VERSION "HNNBNNNYNNNNNNNNNNNNNNNNNNNNNNNNNNNNNNNNNN/4/%%%/4/'%**4NNN///"

NS_ :

BS_:

BU_: BAP_Tester BMS_NV_12V Gateway_Max Klima

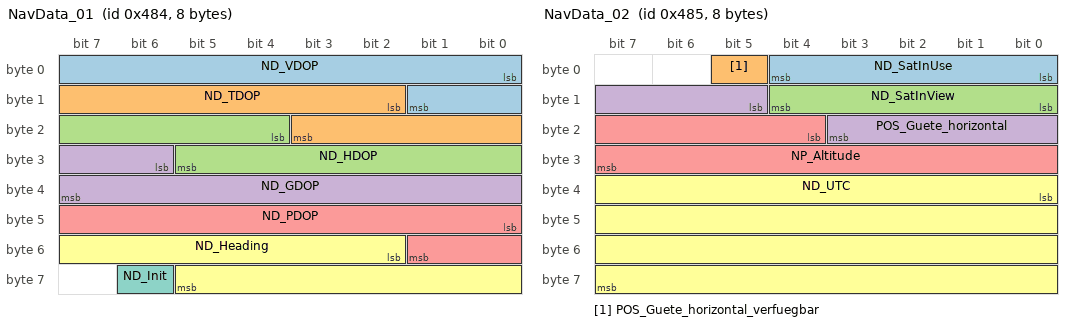
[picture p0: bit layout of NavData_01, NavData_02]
BO_ 1156 NavData_01: 8 Gateway_Max
 SG_ ND_VDOP : 0|10@1+ (0.025,0) [0.000|25.000] ""  Vector__XXX
 SG_ ND_TDOP : 10|10@1+ (0.025,0) [0.000|25.000] ""  Vector__XXX
 SG_ ND_HDOP : 20|10@1+ (0.025,0) [0.000|25.000] ""  Vector__XXX
 SG_ ND_GDOP : 30|10@1+ (0.025,0) [0.000|25.000] ""  Vector__XXX
 SG_ ND_PDOP : 40|10@1+ (0.025,0) [0.000|25.000] ""  Vector__XXX
 SG_ ND_Heading : 50|12@1+ (0.1,0) [0.0|359.9] "Unit_DegreOfArc"  Klima
 SG_ ND_Init : 62|1@1+ (1.0,0.0) [0.0|1] ""  Vector__XXX

BO_ 1157 NavData_02: 8 Gateway_Max
 SG_ ND_SatInUse : 0|5@1+ (1,0) [0|29] ""  Vector__XXX
 SG_ POS_Guete_horizontal_verfuegbar : 5|1@1+ (1.0,0.0) [0.0|1] ""  Vector__XXX
 SG_ ND_SatInView : 8|5@1+ (1,0) [0|29] ""  Vector__XXX
 SG_ POS_Guete_horizontal : 13|7@1+ (2,0) [0|246] "Unit_Meter"  Vector__XXX
 SG_ NP_Altitude : 20|12@1+ (2,-500) [-500|7686] "Unit_Meter"  Klima
 SG_ ND_UTC : 32|32@1+ (1,0) [0|4294967293] "Unit_Secon"  Klima

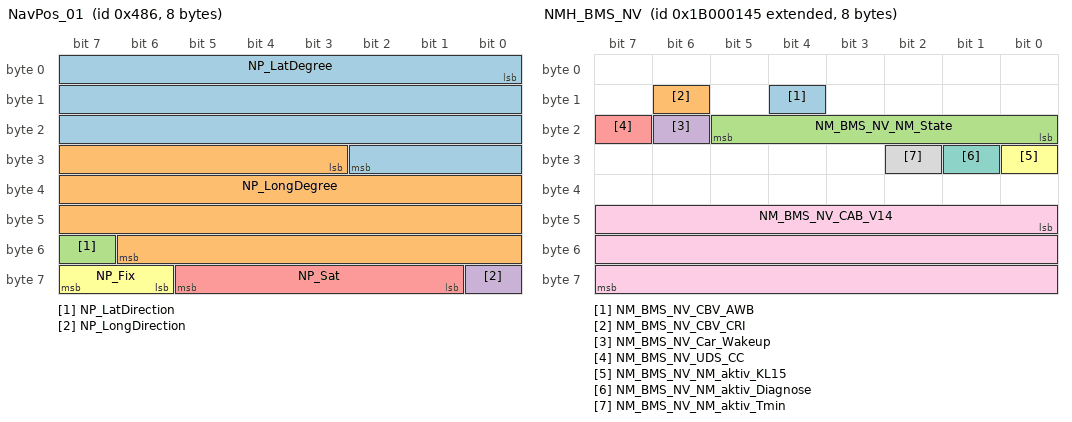
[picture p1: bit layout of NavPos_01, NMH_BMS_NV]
BO_ 1158 NavPos_01: 8 Gateway_Max
 SG_ NP_LatDegree : 0|27@1+ (0.000001,0) [0.000000|90.000000] "Unit_DegreOfArc"  Klima
 SG_ NP_LongDegree : 27|28@1+ (0.000001,0) [0.000000|180.000000] "Unit_DegreOfArc"  Klima
 SG_ NP_LatDirection : 55|1@1+ (1.0,0.0) [0.0|1] ""  Klima
 SG_ NP_LongDirection : 56|1@1+ (1.0,0.0) [0.0|1] ""  Klima
 SG_ NP_Sat : 57|5@1+ (1,0) [0|29] ""  Vector__XXX
 SG_ NP_Fix : 62|2@1+ (1.0,0.0) [0.0|3] ""  Vector__XXX

BO_ 2600468805 NMH_BMS_NV: 8 BMS_NV_12V
 SG_ NM_BMS_NV_CBV_AWB : 12|1@1+ (1.0,0.0) [0.0|1] ""  Gateway_Max
 SG_ NM_BMS_NV_CBV_CRI : 14|1@1+ (1.0,0.0) [0.0|1] ""  Gateway_Max
 SG_ NM_BMS_NV_NM_State : 16|6@1+ (1.0,0.0) [0.0|63] ""  Klima
 SG_ NM_BMS_NV_Car_Wakeup : 22|1@1+ (1.0,0.0) [0.0|1] ""  Gateway_Max
 SG_ NM_BMS_NV_UDS_CC : 23|1@1+ (1.0,0.0) [0.0|1] ""  Vector__XXX
 SG_ NM_BMS_NV_NM_aktiv_KL15 : 24|1@1+ (1.0,0.0) [0.0|1] ""  Vector__XXX
 SG_ NM_BMS_NV_NM_aktiv_Diagnose : 25|1@1+ (1.0,0.0) [0.0|1] ""  Vector__XXX
 SG_ NM_BMS_NV_NM_aktiv_Tmin : 26|1@1+ (1.0,0.0) [0.0|1] ""  Vector__XXX
 SG_ NM_BMS_NV_CAB_V14 : 40|24@1+ (1.0,0.0) [0.0|16777215] ""  Gateway_Max

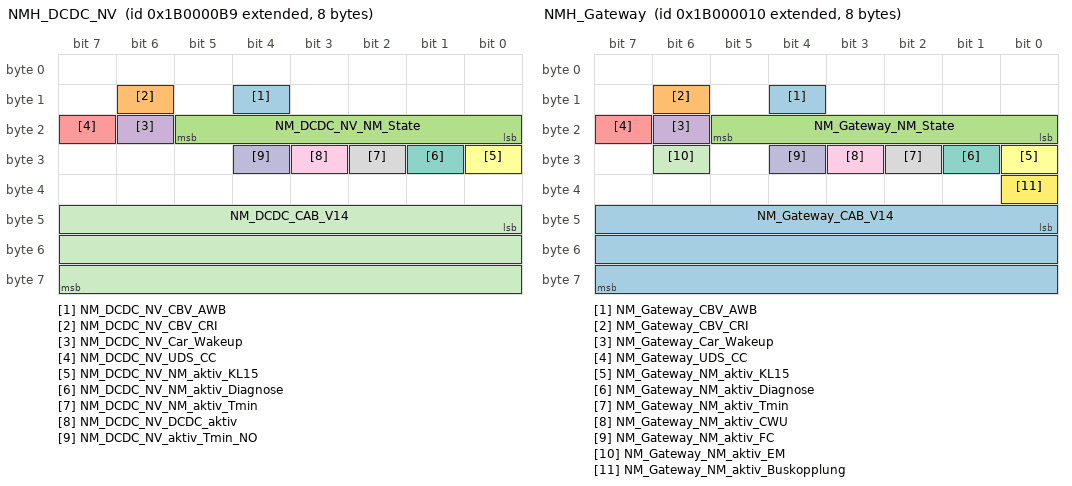
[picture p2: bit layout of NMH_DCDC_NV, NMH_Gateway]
BO_ 2600468665 NMH_DCDC_NV: 8 Vector__XXX
 SG_ NM_DCDC_NV_CBV_AWB : 12|1@1+ (1.0,0.0) [0.0|1] ""  Gateway_Max
 SG_ NM_DCDC_NV_CBV_CRI : 14|1@1+ (1.0,0.0) [0.0|1] ""  Gateway_Max
 SG_ NM_DCDC_NV_NM_State : 16|6@1+ (1.0,0.0) [0.0|63] ""  BMS_NV_12V,Klima
 SG_ NM_DCDC_NV_Car_Wakeup : 22|1@1+ (1.0,0.0) [0.0|1] ""  Gateway_Max
 SG_ NM_DCDC_NV_UDS_CC : 23|1@1+ (1.0,0.0) [0.0|1] ""  Vector__XXX
 SG_ NM_DCDC_NV_NM_aktiv_KL15 : 24|1@1+ (1.0,0.0) [0.0|1] ""  Vector__XXX
 SG_ NM_DCDC_NV_NM_aktiv_Diagnose : 25|1@1+ (1.0,0.0) [0.0|1] ""  Vector__XXX
 SG_ NM_DCDC_NV_NM_aktiv_Tmin : 26|1@1+ (1.0,0.0) [0.0|1] ""  Vector__XXX
 SG_ NM_DCDC_NV_DCDC_aktiv : 27|1@1+ (1.0,0.0) [0.0|1] ""  Vector__XXX
 SG_ NM_DCDC_NV_aktiv_Tmin_NO : 28|1@1+ (1.0,0.0) [0.0|1] ""  Vector__XXX
 SG_ NM_DCDC_CAB_V14 : 40|24@1+ (1.0,0.0) [0.0|16777215] ""  Gateway_Max

BO_ 2600468496 NMH_Gateway: 8 Gateway_Max
 SG_ NM_Gateway_CBV_AWB : 12|1@1+ (1.0,0.0) [0.0|1] ""  Vector__XXX
 SG_ NM_Gateway_CBV_CRI : 14|1@1+ (1.0,0.0) [0.0|1] ""  Vector__XXX
 SG_ NM_Gateway_NM_State : 16|6@1+ (1.0,0.0) [0.0|63] ""  BMS_NV_12V,Klima
 SG_ NM_Gateway_Car_Wakeup : 22|1@1+ (1.0,0.0) [0.0|1] ""  Vector__XXX
 SG_ NM_Gateway_UDS_CC : 23|1@1+ (1.0,0.0) [0.0|1] ""  Vector__XXX
 SG_ NM_Gateway_NM_aktiv_KL15 : 24|1@1+ (1.0,0.0) [0.0|1] ""  Vector__XXX
 SG_ NM_Gateway_NM_aktiv_Diagnose : 25|1@1+ (1.0,0.0) [0.0|1] ""  Vector__XXX
 SG_ NM_Gateway_NM_aktiv_Tmin : 26|1@1+ (1.0,0.0) [0.0|1] ""  Vector__XXX
 SG_ NM_Gateway_NM_aktiv_CWU : 27|1@1+ (1.0,0.0) [0.0|1] ""  Vector__XXX
 SG_ NM_Gateway_NM_aktiv_FC : 28|1@1+ (1.0,0.0) [0.0|1] ""  Vector__XXX
 SG_ NM_Gateway_NM_aktiv_EM : 30|1@1+ (1.0,0.0) [0.0|1] ""  Vector__XXX
 SG_ NM_Gateway_NM_aktiv_Buskopplung : 32|1@1+ (1.0,0.0) [0.0|1] ""  Vector__XXX
 SG_ NM_Gateway_CAB_V14 : 40|24@1+ (1.0,0.0) [0.0|16777215] ""  Vector__XXX

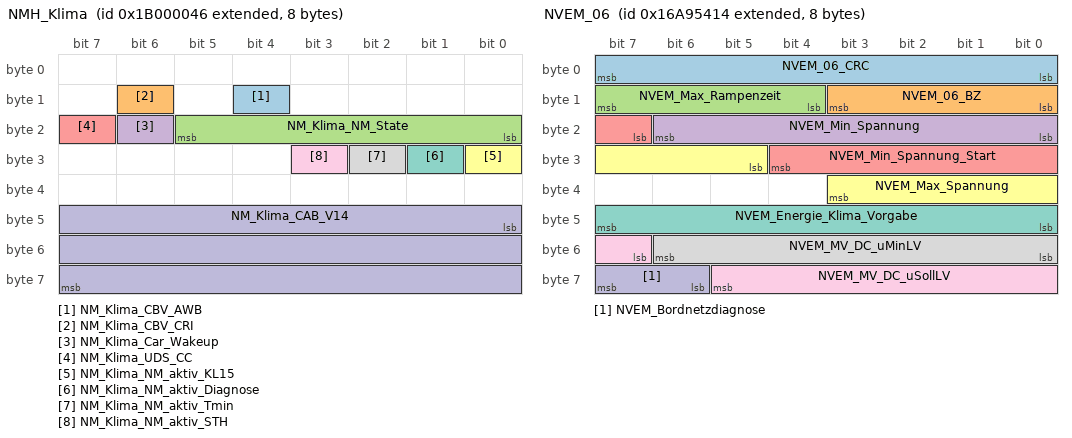
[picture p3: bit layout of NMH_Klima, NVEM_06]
BO_ 2600468550 NMH_Klima: 8 Klima
 SG_ NM_Klima_CBV_AWB : 12|1@1+ (1.0,0.0) [0.0|1] ""  Gateway_Max
 SG_ NM_Klima_CBV_CRI : 14|1@1+ (1.0,0.0) [0.0|1] ""  Gateway_Max
 SG_ NM_Klima_NM_State : 16|6@1+ (1.0,0.0) [0.0|63] ""  BMS_NV_12V
 SG_ NM_Klima_Car_Wakeup : 22|1@1+ (1.0,0.0) [0.0|1] ""  Gateway_Max
 SG_ NM_Klima_UDS_CC : 23|1@1+ (1.0,0.0) [0.0|1] ""  Vector__XXX
 SG_ NM_Klima_NM_aktiv_KL15 : 24|1@1+ (1.0,0.0) [0.0|1] ""  Vector__XXX
 SG_ NM_Klima_NM_aktiv_Diagnose : 25|1@1+ (1.0,0.0) [0.0|1] ""  Vector__XXX
 SG_ NM_Klima_NM_aktiv_Tmin : 26|1@1+ (1.0,0.0) [0.0|1] ""  Vector__XXX
 SG_ NM_Klima_NM_aktiv_STH : 27|1@1+ (1.0,0.0) [0.0|1] ""  Vector__XXX
 SG_ NM_Klima_CAB_V14 : 40|24@1+ (1.0,0.0) [0.0|16777215] ""  Gateway_Max

BO_ 2527679508 NVEM_06: 8 Gateway_Max
 SG_ NVEM_06_CRC : 0|8@1+ (1,0) [0|255] ""  Vector__XXX
 SG_ NVEM_06_BZ : 8|4@1+ (1,0) [0|15] ""  Vector__XXX
 SG_ NVEM_Max_Rampenzeit : 12|4@1+ (1.0,0.0) [0.0|15] ""  Vector__XXX
 SG_ NVEM_Min_Spannung : 16|7@1+ (0.05,10.6) [10.60|16.00] "Unit_Volt"  Vector__XXX
 SG_ NVEM_Min_Spannung_Start : 23|6@1+ (0.1,7) [7.0|13.1] "Unit_Volt"  Vector__XXX
 SG_ NVEM_Max_Spannung : 29|7@1+ (0.05,10.6) [10.60|16.00] "Unit_Volt"  Vector__XXX
 SG_ NVEM_Energie_Klima_Vorgabe : 40|8@1+ (10,0) [0|2530] "Unit_WattHour"  Vector__XXX
 SG_ NVEM_MV_DC_uMinLV : 48|7@1+ (0.1,3.5) [3.5|16.0] "Unit_Volt"  Vector__XXX
 SG_ NVEM_MV_DC_uSollLV : 55|7@1+ (0.05,10.6) [10.60|16.00] "Unit_Volt"  Vector__XXX
 SG_ NVEM_Bordnetzdiagnose : 62|2@1+ (1.0,0.0) [0.0|3] ""  Vector__XXX

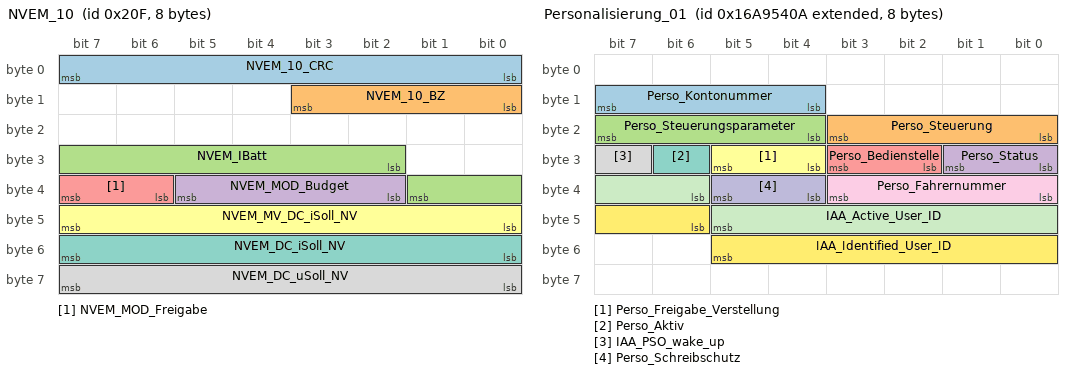
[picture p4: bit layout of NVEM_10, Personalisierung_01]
BO_ 527 NVEM_10: 8 Gateway_Max
 SG_ NVEM_10_CRC : 0|8@1+ (1,0) [0|255] ""  Vector__XXX
 SG_ NVEM_10_BZ : 8|4@1+ (1,0) [0|15] ""  Vector__XXX
 SG_ NVEM_IBatt : 26|8@1+ (1,-127) [-127|127] "Unit_Amper"  Vector__XXX
 SG_ NVEM_MOD_Budget : 34|4@1+ (10,0) [0|100] "Unit_PerCent"  Vector__XXX
 SG_ NVEM_MOD_Freigabe : 38|2@1+ (1.0,0.0) [0.0|3] ""  Vector__XXX
 SG_ NVEM_MV_DC_iSoll_NV : 40|8@1+ (1,-253) [-253|0] "Unit_Amper"  Vector__XXX
 SG_ NVEM_DC_iSoll_NV : 48|8@1+ (1,-253) [-253|0] "Unit_Amper"  Vector__XXX
 SG_ NVEM_DC_uSoll_NV : 56|8@1+ (0.025,10.6) [10.600|16.000] "Unit_Volt"  Vector__XXX

BO_ 2621440668 OBDC_BMS_48V_Req_FD: 64 Gateway_Max
 SG_ OBDC_BMS_48V_Req_FD_Data : 0|512@1+ (1.0,0.0) [0.0|13407807929942597099574024998205846127479365820592393377723561443721764030073546976801874298166903427690031858186486050853753882811946569946433649006084095] ""  Vector__XXX

BO_ 2621571740 OBDC_BMS_48V_Resp_FD: 64 Vector__XXX
 SG_ OBDC_BMS_48V_Resp_FD_Data : 0|512@1+ (1.0,0.0) [0.0|13407807929942597099574024998205846127479365820592393377723561443721764030073546976801874298166903427690031858186486050853753882811946569946433649006084095] ""  Gateway_Max

BO_ 2621702725 OBDC_BMS_NV_Req_FD: 64 Gateway_Max
 SG_ OBDC_BMS_NV_Req_FD_Data : 0|512@1+ (1.0,0.0) [0.0|13407807929942597099574024998205846127479365820592393377723561443721764030073546976801874298166903427690031858186486050853753882811946569946433649006084095] ""  BMS_NV_12V

BO_ 2621833797 OBDC_BMS_NV_Resp_FD: 64 BMS_NV_12V
 SG_ OBDC_BMS_NV_Resp_FD_Data : 0|512@1+ (1.0,0.0) [0.0|13407807929942597099574024998205846127479365820592393377723561443721764030073546976801874298166903427690031858186486050853753882811946569946433649006084095] ""  Gateway_Max

BO_ 2621440697 OBDC_DCDC_NV_Req_FD: 64 Gateway_Max
 SG_ OBDC_DCDC_NV_Req_FD_Data : 0|512@1+ (1.0,0.0) [0.0|13407807929942597099574024998205846127479365820592393377723561443721764030073546976801874298166903427690031858186486050853753882811946569946433649006084095] ""  Vector__XXX

BO_ 2621571769 OBDC_DCDC_NV_Resp_FD: 64 Vector__XXX
 SG_ OBDC_DCDC_NV_Resp_FD_Data : 0|512@1+ (1.0,0.0) [0.0|13407807929942597099574024998205846127479365820592393377723561443721764030073546976801874298166903427690031858186486050853753882811946569946433649006084095] ""  Gateway_Max

BO_ 2621440577 OBDC_DCDC_Req_FD: 64 Gateway_Max
 SG_ OBDC_DCDC_Req_FD_Data : 0|512@1+ (1.0,0.0) [0.0|13407807929942597099574024998205846127479365820592393377723561443721764030073546976801874298166903427690031858186486050853753882811946569946433649006084095] ""  Vector__XXX

BO_ 2621571649 OBDC_DCDC_Resp_FD: 64 Vector__XXX
 SG_ OBDC_DCDC_Resp_FD_Data : 0|512@1+ (1.0,0.0) [0.0|13407807929942597099574024998205846127479365820592393377723561443721764030073546976801874298166903427690031858186486050853753882811946569946433649006084095] ""  Gateway_Max

BO_ 2621506048 OBDC_Funktionaler_Req_All_FD: 64 Gateway_Max
 SG_ OBDC_Funktion_Req_All_FD_Data : 0|512@1+ (1.0,0.0) [0.0|13407807929942597099574024998205846127479365820592393377723561443721764030073546976801874298166903427690031858186486050853753882811946569946433649006084095] ""  BMS_NV_12V,Klima

BO_ 2621440635 OBDC_Hybrid_01_Req_FD: 64 Gateway_Max
 SG_ OBDC_Hybrid_01_Req_FD_Data : 0|512@1+ (1.0,0.0) [0.0|13407807929942597099574024998205846127479365820592393377723561443721764030073546976801874298166903427690031858186486050853753882811946569946433649006084095] ""  Vector__XXX

BO_ 2621571707 OBDC_Hybrid_01_Resp_FD: 64 Vector__XXX
 SG_ OBDC_Hybrid_01_Resp_FD_Data : 0|512@1+ (1.0,0.0) [0.0|13407807929942597099574024998205846127479365820592393377723561443721764030073546976801874298166903427690031858186486050853753882811946569946433649006084095] ""  Gateway_Max

BO_ 2621440582 OBDC_Klima_Req_FD: 64 Gateway_Max
 SG_ OBDC_Klima_Req_FD_Data : 0|512@1+ (1.0,0.0) [0.0|13407807929942597099574024998205846127479365820592393377723561443721764030073546976801874298166903427690031858186486050853753882811946569946433649006084095] ""  Klima

BO_ 2621571654 OBDC_Klima_Resp_FD: 64 Klima
 SG_ OBDC_Klima_Resp_FD_Data : 0|512@1+ (1.0,0.0) [0.0|13407807929942597099574024998205846127479365820592393377723561443721764030073546976801874298166903427690031858186486050853753882811946569946433649006084095] ""  Gateway_Max

BO_ 2621440580 OBDC_Ladegeraet_Req_FD: 64 Gateway_Max
 SG_ OBDC_Ladegeraet_Req_FD_Data : 0|512@1+ (1.0,0.0) [0.0|13407807929942597099574024998205846127479365820592393377723561443721764030073546976801874298166903427690031858186486050853753882811946569946433649006084095] ""  Vector__XXX

BO_ 2621571652 OBDC_Ladegeraet_Resp_FD: 64 Vector__XXX
 SG_ OBDC_Ladegeraet_Resp_FD_Data : 0|512@1+ (1.0,0.0) [0.0|13407807929942597099574024998205846127479365820592393377723561443721764030073546976801874298166903427690031858186486050853753882811946569946433649006084095] ""  Gateway_Max

BO_ 2621702683 OBDC_SACID_1_Req_FD: 64 Gateway_Max
 SG_ OBDC_SACID_1_Req_FD_Data : 0|512@1+ (1.0,0.0) [0.0|13407807929942597099574024998205846127479365820592393377723561443721764030073546976801874298166903427690031858186486050853753882811946569946433649006084095] ""  Vector__XXX

BO_ 2621833755 OBDC_SACID_1_Resp_FD: 64 Vector__XXX
 SG_ OBDC_SACID_1_Resp_FD_Data : 0|512@1+ (1.0,0.0) [0.0|13407807929942597099574024998205846127479365820592393377723561443721764030073546976801874298166903427690031858186486050853753882811946569946433649006084095] ""  Gateway_Max

BO_ 2549903569 OBDC_SSN_CMC_01_Req: 8 Gateway_Max
 SG_ OBDC_SSN_CMC_01_Req_Data : 0|64@1+ (1.0,0.0) [0.0|18446744073709551615] ""  Vector__XXX

BO_ 2550034641 OBDC_SSN_CMC_01_Resp: 8 Vector__XXX
 SG_ OBDC_SSN_CMC_01_Resp_Data : 0|64@1+ (1.0,0.0) [0.0|18446744073709551615] ""  Gateway_Max

BO_ 2549903573 OBDC_SSN_CMC_05_Req: 8 Gateway_Max
 SG_ OBDC_SSN_CMC_05_Req_Data : 0|64@1+ (1.0,0.0) [0.0|18446744073709551615] ""  Vector__XXX

BO_ 2550034645 OBDC_SSN_CMC_05_Resp: 8 Vector__XXX
 SG_ OBDC_SSN_CMC_05_Resp_Data : 0|64@1+ (1.0,0.0) [0.0|18446744073709551615] ""  Gateway_Max

BO_ 2549903577 OBDC_SSN_CMC_09_Req: 8 Gateway_Max
 SG_ OBDC_SSN_CMC_09_Req_Data : 0|64@1+ (1.0,0.0) [0.0|18446744073709551615] ""  Vector__XXX

BO_ 2550034649 OBDC_SSN_CMC_09_Resp: 8 Vector__XXX
 SG_ OBDC_SSN_CMC_09_Resp_Data : 0|64@1+ (1.0,0.0) [0.0|18446744073709551615] ""  Gateway_Max

BO_ 2549903601 OBDC_SSN_CMC_13_Req: 8 Gateway_Max
 SG_ OBDC_SSN_CMC_13_Req_Data : 0|64@1+ (1.0,0.0) [0.0|18446744073709551615] ""  Vector__XXX

BO_ 2550034673 OBDC_SSN_CMC_13_Resp: 8 Vector__XXX
 SG_ OBDC_SSN_CMC_13_Resp_Data : 0|64@1+ (1.0,0.0) [0.0|18446744073709551615] ""  Gateway_Max

BO_ 2564502513 OBDx_allOBD_Req: 8 Gateway_Max
 SG_ OBDx_allOBD_Req_Data : 0|64@1+ (1.0,0.0) [0.0|18446744073709551615] ""  BMS_NV_12V,Klima

BO_ 2564428273 OBDx_BMS_48V_Req: 8 Gateway_Max
 SG_ OBDx_BMS_48V_Req_Data : 0|64@1+ (1.0,0.0) [0.0|18446744073709551615] ""  Vector__XXX

BO_ 2564485393 OBDx_BMS_48V_Resp: 8 Vector__XXX
 SG_ OBDx_BMS_48V_Resp_Data : 0|64@1+ (1.0,0.0) [0.0|18446744073709551615] ""  Gateway_Max

BO_ 2564433393 OBDx_BMS_NV_Req: 8 Gateway_Max
 SG_ OBDx_BMS_NV_Req_Data : 0|64@1+ (1.0,0.0) [0.0|18446744073709551615] ""  BMS_NV_12V

BO_ 2564485413 OBDx_BMS_NV_Resp: 8 BMS_NV_12V
 SG_ OBDx_BMS_NV_Resp_Data : 0|64@1+ (1.0,0.0) [0.0|18446744073709551615] ""  Gateway_Max

BO_ 2564426737 OBDx_DCDC_NV_Req: 8 Gateway_Max
 SG_ OBDx_DCDC_NV_Req_Data : 0|64@1+ (1.0,0.0) [0.0|18446744073709551615] ""  Vector__XXX

BO_ 2564485387 OBDx_DCDC_NV_Resp: 8 Vector__XXX
 SG_ OBDx_DCDC_NV_Resp_Data : 0|64@1+ (1.0,0.0) [0.0|18446744073709551615] ""  Gateway_Max

BO_ 2564425201 OBDx_Hybrid_01_Req: 8 Gateway_Max
 SG_ OBDx_Hybrid_01_Req_Data : 0|64@1+ (1.0,0.0) [0.0|18446744073709551615] ""  Vector__XXX

BO_ 2564485381 OBDx_Hybrid_01_Resp: 8 Vector__XXX
 SG_ OBDx_Hybrid_01_Resp_Data : 0|64@1+ (1.0,0.0) [0.0|18446744073709551615] ""  Gateway_Max

BO_ 2564426481 OBDx_Klima_Req: 8 Gateway_Max
 SG_ OBDx_Klima_Req_Data : 0|64@1+ (1.0,0.0) [0.0|18446744073709551615] ""  Klima

BO_ 2564485386 OBDx_Klima_Resp: 8 Klima
 SG_ OBDx_Klima_Resp_Data : 0|64@1+ (1.0,0.0) [0.0|18446744073709551615] ""  Gateway_Max

BO_ 2564426993 OBDx_Ladegeraet_Req: 8 Gateway_Max
 SG_ OBDx_Ladegeraet_Req_Data : 0|64@1+ (1.0,0.0) [0.0|18446744073709551615] ""  Vector__XXX

BO_ 2564485388 OBDx_Ladegeraet_Resp: 8 Vector__XXX
 SG_ OBDx_Ladegeraet_Resp_Data : 0|64@1+ (1.0,0.0) [0.0|18446744073709551615] ""  Gateway_Max

BO_ 2463978776 OBG_01: 64 Vector__XXX
 SG_ OBG_01_CRC : 0|8@1+ (1,0) [0|255] ""  Gateway_Max
 SG_ OBG_01_BZ : 8|4@1+ (1,0) [0|15] ""  Gateway_Max
 SG_ HVLE_IstSpannung_HV : 12|10@1+ (1,0) [0|1021] "Unit_Volt"  Gateway_Max
 SG_ HVLE_Ist_Wirkungsgrad : 22|7@1+ (1,0) [0|100] "Unit_PerCent"  Gateway_Max
 SG_ HVLE_Netzfrequenz_EVU : 29|9@1+ (0.1,40) [40.0|80.0] "Unit_Hertz"  Gateway_Max
 SG_ HVLE_Energiemenge_Laden : 38|14@1+ (40,0) [0|654800] "Unit_WattHour"  Gateway_Max
 SG_ HVLE_I_istAC_Netz_L1 : 52|9@1+ (0.1,0) [0.0|50.8] "Unit_Amper"  Gateway_Max
 SG_ HVLE_I_istAC_Netz_L2 : 61|9@1+ (0.1,0) [0.0|50.8] "Unit_Amper"  Gateway_Max
 SG_ HVLE_I_istAC_Netz_L3 : 70|9@1+ (0.1,0) [0.0|50.8] "Unit_Amper"  Gateway_Max
 SG_ HVLE_U_istAC_Netz_L1 : 79|9@1+ (1,0) [0|508] "Unit_Volt"  Gateway_Max
 SG_ HVLE_U_istAC_Netz_L2 : 88|9@1+ (1,0) [0|508] "Unit_Volt"  Gateway_Max
 SG_ HVLE_U_istAC_Netz_L3 : 97|9@1+ (1,0) [0|508] "Unit_Volt"  Gateway_Max
 SG_ HVLE_OBG_DC_MaxStrom : 106|11@1+ (0.1,0) [0.0|204.5] "Unit_Amper"  Gateway_Max
 SG_ HVLE_OBG_DC_IstStrom : 117|11@1+ (0.1,0) [0.0|204.5] "Unit_Amper"  Gateway_Max
 SG_ HVLE_Netzmodus : 128|4@1+ (1.0,0.0) [0.0|15] ""  Gateway_Max
 SG_ HVLE_Derating_Temperatur : 132|1@1+ (1.0,0.0) [0.0|1] ""  Gateway_Max
 SG_ HVLE_OBG_IstModus : 133|3@1+ (1.0,0.0) [0.0|7] ""  Gateway_Max
 SG_ HVLE_OBG_Warnzustand : 136|4@1+ (1.0,0.0) [0.0|15] ""  Gateway_Max
 SG_ HVLE_OBG_Fehlerstatus : 140|1@1+ (1.0,0.0) [0.0|1] ""  Gateway_Max
 SG_ HVLE_OBG_Status_EoHVL : 141|2@1+ (1.0,0.0) [0.0|3] ""  Gateway_Max
 SG_ HVLE_OBG_Fehlerstrom : 143|1@1+ (1.0,0.0) [0.0|1] ""  Gateway_Max
 SG_ HVLE_OBG_ACDC_IstLeistung : 144|11@1+ (25,0) [0|45000] "Unit_Watt"  Gateway_Max
 SG_ HVLE_OBG_ACDC_MaxLeistung : 155|11@1+ (25,0) [0|45000] "Unit_Watt"  Gateway_Max
 SG_ HVLE_OBG_AC_maxStrom : 166|10@1+ (0.1,0) [0.0|100.0] "Unit_Amper"  Gateway_Max
 SG_ HVLE_OBG_AC_maxSpannung : 176|10@1+ (1,0) [0|1000] "Unit_Volt"  Gateway_Max
 SG_ HVLE_AnzahlVerwendeterPhasen : 186|2@1+ (1.0,0.0) [0.0|3] ""  Gateway_Max
 SG_ HVLE_AsymmetrischLadenMoeglich : 188|1@1+ (1.0,0.0) [0.0|1] ""  Gateway_Max
 SG_ HVLE_OBG_Typ_verbaut : 189|3@1+ (1.0,0.0) [0.0|7] ""  Gateway_Max
 SG_ HVLE_PE_Monitor : 192|3@1+ (1.0,0.0) [0.0|7] ""  Gateway_Max
 SG_ HVLE_OBG_Status_Spgfreiheit : 195|2@1+ (1.0,0.0) [0.0|3] ""  Gateway_Max
 SG_ HVLE_OBG_Kuehltemperatur : 197|8@1+ (1,-40) [-40|213] "Unit_DegreCelsi"  Gateway_Max
 SG_ SOK_OBG_01_Signatur : 480|32@1+ (1.0,0.0) [0.0|4294967295] ""  Gateway_Max

BO_ 2589283656 ORU_01: 8 Gateway_Max
 SG_ ORU_Warnung : 58|2@1+ (1.0,0.0) [0.0|3] ""  Vector__XXX
 SG_ ORU_Status : 61|3@1+ (1.0,0.0) [0.0|7] ""  Klima

BO_ 2527679498 Personalisierung_01: 8 Gateway_Max
 SG_ Perso_Kontonummer : 12|4@1+ (1.0,0.0) [0.0|15] ""  Klima
 SG_ Perso_Steuerung : 16|4@1+ (1.0,0.0) [0.0|15] ""  Klima
 SG_ Perso_Steuerungsparameter : 20|4@1+ (1.0,0.0) [0.0|15] ""  Klima
 SG_ Perso_Status : 24|2@1+ (1.0,0.0) [0.0|3] ""  Klima
 SG_ Perso_Bedienstelle : 26|2@1+ (1.0,0.0) [0.0|3] ""  Klima
 SG_ Perso_Freigabe_Verstellung : 28|2@1+ (1.0,0.0) [0.0|3] ""  Klima
 SG_ Perso_Aktiv : 30|1@1+ (1.0,0.0) [0.0|1] ""  Klima
 SG_ IAA_PSO_wake_up : 31|1@1+ (1.0,0.0) [0.0|1] ""  Klima
 SG_ Perso_Fahrernummer : 32|4@1+ (1.0,0.0) [0.0|15] ""  Klima
 SG_ Perso_Schreibschutz : 36|2@1+ (1.0,0.0) [0.0|3] ""  Klima
 SG_ IAA_Active_User_ID : 38|8@1+ (1,0) [0|255] "Unit_None"  Klima
 SG_ IAA_Identified_User_ID : 46|8@1+ (1,0) [0|255] "Unit_None"  Klima

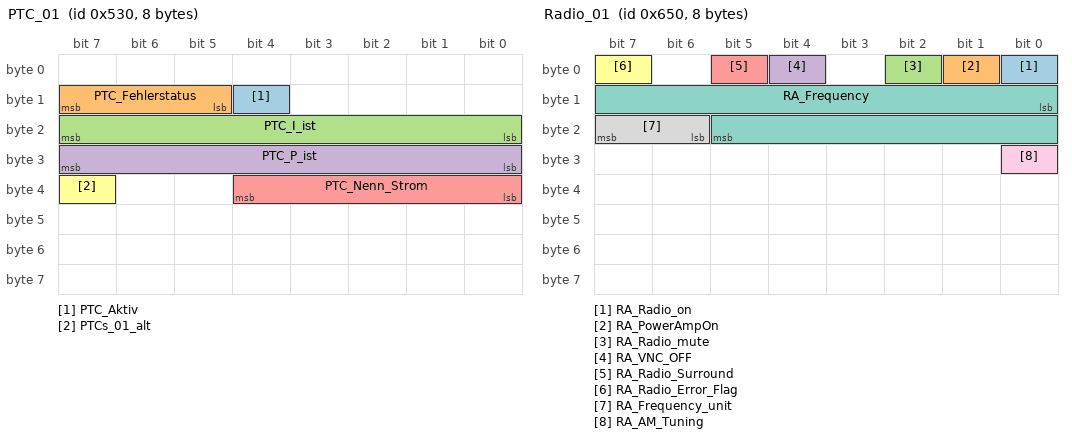
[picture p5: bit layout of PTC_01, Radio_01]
BO_ 1328 PTC_01: 8 Klima
 SG_ PTC_Aktiv : 12|1@1+ (1,0) [0|1] ""  Vector__XXX
 SG_ PTC_Fehlerstatus : 13|3@1+ (1,0) [0|7] ""  Vector__XXX
 SG_ PTC_I_ist : 16|8@1+ (1,0) [0|253] "Unit_Amper"  Gateway_Max
 SG_ PTC_P_ist : 24|8@1+ (10,0) [0|2530] "Unit_Watt"  Vector__XXX
 SG_ PTC_Nenn_Strom : 32|5@1+ (10,0) [0|310] "Unit_Amper"  Vector__XXX
 SG_ PTCs_01_alt : 39|1@1+ (1.0,0.0) [0.0|1] ""  Vector__XXX

BO_ 1616 Radio_01: 8 Gateway_Max
 SG_ RA_Radio_on : 0|1@1+ (1,0) [0|1] ""  Vector__XXX
 SG_ RA_PowerAmpOn : 1|1@1+ (1,0) [0|1] ""  Vector__XXX
 SG_ RA_Radio_mute : 2|1@1+ (1,0) [0|1] ""  Vector__XXX
 SG_ RA_VNC_OFF : 4|1@1+ (1,0) [0|1] ""  Vector__XXX
 SG_ RA_Radio_Surround : 5|1@1+ (1,0) [0|1] ""  Vector__XXX
 SG_ RA_Radio_Error_Flag : 7|1@1+ (1.0,0.0) [0.0|1] ""  Vector__XXX
 SG_ RA_Frequency : 8|14@1+ (1,0) [0|16383] "Unit_None"  Klima
 SG_ RA_Frequency_unit : 22|2@1+ (1.0,0.0) [0.0|3] ""  Klima
 SG_ RA_AM_Tuning : 24|1@1+ (1.0,0.0) [0.0|1] ""  Klima

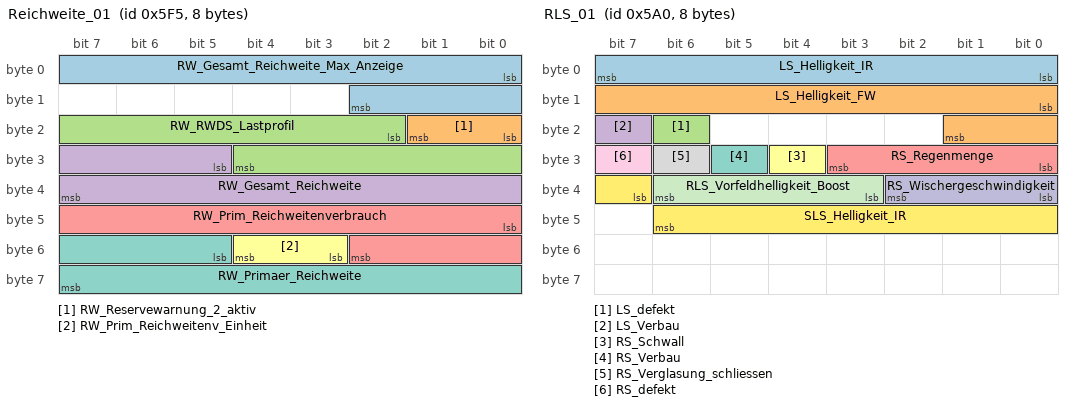
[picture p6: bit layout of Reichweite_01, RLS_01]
BO_ 1525 Reichweite_01: 8 Gateway_Max
 SG_ RW_Gesamt_Reichweite_Max_Anzeige : 0|11@1+ (1,0) [0|2044] "Unit_None"  Vector__XXX
 SG_ RW_Reservewarnung_2_aktiv : 16|2@1+ (1.0,0.0) [0.0|3] ""  Vector__XXX
 SG_ RW_RWDS_Lastprofil : 18|11@1+ (1,0) [0|2045] "Unit_Amper"  Vector__XXX
 SG_ RW_Gesamt_Reichweite : 29|11@1+ (1,0) [0|2044] "Unit_KiloMeter"  Vector__XXX
 SG_ RW_Prim_Reichweitenverbrauch : 40|11@1+ (0.1,0) [0.0|204.4] "Unit_None"  Vector__XXX
 SG_ RW_Prim_Reichweitenv_Einheit : 51|2@1+ (1.0,0.0) [0.0|3] ""  Vector__XXX
 SG_ RW_Primaer_Reichweite : 53|11@1+ (1,0) [0|2044] "Unit_KiloMeter"  Vector__XXX

BO_ 1440 RLS_01: 8 Gateway_Max
 SG_ LS_Helligkeit_IR : 0|8@1+ (400,0) [0|101200] "Unit_Lux"  Klima
 SG_ LS_Helligkeit_FW : 8|10@1+ (6,0) [0|6126] "Unit_Lux"  Vector__XXX
 SG_ LS_defekt : 22|1@1+ (1.0,0.0) [0.0|1] ""  Vector__XXX
 SG_ LS_Verbau : 23|1@1+ (1.0,0.0) [0.0|1] ""  Vector__XXX
 SG_ RS_Regenmenge : 24|4@1+ (1.0,0.0) [0.0|15] ""  Klima
 SG_ RS_Schwall : 28|1@1+ (1.0,0.0) [0.0|1] ""  Vector__XXX
 SG_ RS_Verbau : 29|1@1+ (1.0,0.0) [0.0|1] ""  Vector__XXX
 SG_ RS_Verglasung_schliessen : 30|1@1+ (1.0,0.0) [0.0|1] ""  Vector__XXX
 SG_ RS_defekt : 31|1@1+ (1.0,0.0) [0.0|1] ""  Klima
 SG_ RS_Wischergeschwindigkeit : 32|3@1+ (1.0,0.0) [0.0|7] ""  Klima
 SG_ RLS_Vorfeldhelligkeit_Boost : 35|4@1+ (1.0,0.0) [0.0|15] ""  Vector__XXX
 SG_ SLS_Helligkeit_IR : 39|8@1+ (250,0) [0|7000] "Unit_Lux"  Vector__XXX

BO_ 2584746776 SACID_1_AuthTime_Req: 8 Vector__XXX
 SG_ SACID_1_AuthTime_Req_Data : 0|64@1+ (1.0,0.0) [0.0|18446744073709551615] ""  Gateway_Max

BO_ 2584877848 SACID_1_AuthTime_Resp: 8 Gateway_Max
 SG_ SACID_1_AuthTime_Resp_Data : 0|64@1+ (1.0,0.0) [0.0|18446744073709551615] ""  Vector__XXX

BO_ 2630884158 SACID_1_PLC_Req_FD: 64 Vector__XXX
 SG_ SACID_1_PLC_Req_FD_Data : 0|512@1+ (1.0,0.0) [0.0|13407807929942597099574024998205846127479365820592393377723561443721764030073546976801874298166903427690031858186486050853753882811946569946433649006084095] ""  Gateway_Max

BO_ 2631015230 SACID_1_PLC_Resp_FD: 64 Gateway_Max
 SG_ SACID_1_PLC_Resp_FD_Data : 0|512@1+ (1.0,0.0) [0.0|13407807929942597099574024998205846127479365820592393377723561443721764030073546976801874298166903427690031858186486050853753882811946569946433649006084095] ""  Vector__XXX

BO_ 1504 SAD_01: 8 Gateway_Max
 SG_ MD1_Position : 8|7@1+ (1,0) [0|100] "Unit_PerCent"  Klima
 SG_ MD1_Lage : 15|1@1+ (1.0,0.0) [0.0|1] ""  Klima
 SG_ MD3_Position : 16|7@1+ (1,0) [0|100] "Unit_PerCent"  Klima
 SG_ MD3_Lage : 23|1@1+ (1.0,0.0) [0.0|1] ""  Klima
 SG_ MRollo_Position : 24|7@1+ (1,0) [0|100] "Unit_PerCent"  Klima
 SG_ MRollo_Lage : 31|1@1+ (1.0,0.0) [0.0|1] ""  Klima
 SG_ SAD_normiert : 32|1@1+ (1.0,0.0) [0.0|1] ""  Vector__XXX
 SG_ SAD_Thermoschutz : 33|1@1+ (1.0,0.0) [0.0|1] ""  Vector__XXX
 SG_ SAD_UEKB_aktiv : 34|1@1+ (1.0,0.0) [0.0|1] ""  Vector__XXX
 SG_ Rollo_normiert : 35|1@1+ (1.0,0.0) [0.0|1] ""  Vector__XXX
 SG_ Rollo_Thermoschutz : 36|1@1+ (1.0,0.0) [0.0|1] ""  Vector__XXX
 SG_ Rollo_UEKB_aktiv : 37|1@1+ (1.0,0.0) [0.0|1] ""  Vector__XXX
 SG_ SAD_Taster_Deckel_hi : 38|4@1+ (1.0,0.0) [0.0|15] ""  Vector__XXX
 SG_ SAD_Taster_Deckel_vo : 42|4@1+ (1.0,0.0) [0.0|15] ""  Vector__XXX
 SG_ SAD_Taster_Rollo_hi : 46|3@1+ (1.0,0.0) [0.0|7] ""  Vector__XXX
 SG_ SAD_Taster_Rollo_vo : 49|3@1+ (1.0,0.0) [0.0|7] ""  Vector__XXX
 SG_ SAD_Anf_ESC_Zuschaltung : 52|1@1+ (1.0,0.0) [0.0|1] ""  Vector__XXX

BO_ 980 SMLS_01: 8 Gateway_Max
 SG_ SMLS_01_CRC : 0|8@1+ (1,0) [0|255] ""  Vector__XXX
 SG_ SMLS_01_BZ : 8|4@1+ (1,0) [0|15] ""  Vector__XXX
 SG_ BH_Blinker_li : 12|1@1+ (1.0,0.0) [0.0|1] ""  Vector__XXX
 SG_ BH_Blinker_re : 13|1@1+ (1.0,0.0) [0.0|1] ""  Vector__XXX
 SG_ BH_Lichthupe : 14|1@1+ (1.0,0.0) [0.0|1] ""  Vector__XXX
 SG_ BH_Fernlicht : 15|1@1+ (1.0,0.0) [0.0|1] ""  Vector__XXX
 SG_ WH_Tipwischen : 16|1@1+ (1.0,0.0) [0.0|1] ""  Vector__XXX
 SG_ WH_Intervall : 17|1@1+ (1.0,0.0) [0.0|1] ""  Vector__XXX
 SG_ WH_WischerStufe1 : 18|1@1+ (1.0,0.0) [0.0|1] ""  Vector__XXX
 SG_ WH_WischerStufe2 : 19|1@1+ (1.0,0.0) [0.0|1] ""  Vector__XXX
 SG_ WH_Frontwaschen : 20|1@1+ (1.0,0.0) [0.0|1] ""  Vector__XXX
 SG_ WH_Heckintervall : 21|1@1+ (1.0,0.0) [0.0|1] ""  Vector__XXX
 SG_ WH_Heckwaschen : 22|1@1+ (1.0,0.0) [0.0|1] ""  Vector__XXX
 SG_ WH_Intervallstufen : 23|4@1+ (1.0,0.0) [0.0|15] ""  Vector__XXX
 SG_ FAS_Taster : 27|1@1+ (1.0,0.0) [0.0|1] ""  Vector__XXX
 SG_ FAS_Taster_Fehler : 28|1@1+ (1.0,0.0) [0.0|1] ""  Vector__XXX
 SG_ SMLS_Hupe : 29|1@1+ (1.0,0.0) [0.0|1] ""  Vector__XXX
 SG_ LRH_On_Off : 30|2@1+ (1.0,0.0) [0.0|3] ""  Klima
 SG_ LSS_Tastencode : 32|8@1+ (1.0,0.0) [0.0|255] ""  Vector__XXX
 SG_ LRH_aktiv : 40|1@1+ (1.0,0.0) [0.0|1] ""  Vector__XXX
 SG_ SMLS_P_verriegelt : 41|2@1+ (1.0,0.0) [0.0|3] ""  Vector__XXX
 SG_ SMLS_P_verriegelt_plausibel : 43|1@1+ (1.0,0.0) [0.0|1] ""  Vector__XXX
 SG_ WH_SRA : 44|1@1+ (1.0,0.0) [0.0|1] ""  Vector__XXX
 SG_ WH_Wischer_Fehler : 45|1@1+ (1.0,0.0) [0.0|1] ""  Vector__XXX
 SG_ BH_Blinker_Fehler : 46|1@1+ (1.0,0.0) [0.0|1] ""  Vector__XXX
 SG_ SMLS_PTT : 47|1@1+ (1.0,0.0) [0.0|1] ""  Vector__XXX
 SG_ WH_Tipwischen_lang : 48|1@1+ (1.0,0.0) [0.0|1] ""  Vector__XXX

BO_ 2464157766 SOK_FoD_Klima_Req_Chal_02: 8 Klima
 SG_ SOK_FoD_Klima_Req_Challenge : 0|64@1+ (1,0) [0|18446744073709551615] "Unit_None"  Gateway_Max

BO_ 2464292934 SOK_FoD_Klima_Resp_Chal_02: 8 Gateway_Max
 SG_ SOK_FoD_Klima_Resp_Challenge : 0|64@1+ (1,0) [0|18446744073709551615] "Unit_None"  Klima

BO_ 2589283756 SOK_NoAuthenticTime_01: 8 Gateway_Max
 SG_ SOK_ungeschuetzte_Zeit : 8|56@1+ (1,0) [1|72057594037927935] "Unit_None"  BMS_NV_12V,Klima

BO_ 2464153756 SOK_Zeit_BMS_48V_Chal_01: 8 Vector__XXX
 SG_ SOK_Zeit_BMS_48V_Challenge : 0|64@1+ (1,0) [0|18446744073709551615] "Unit_None"  Gateway_Max

BO_ 2464284828 SOK_Zeit_BMS_48V_Resp_01: 16 Gateway_Max
 SG_ SOK_Zeit_BMS_48V_Zeit : 0|56@1+ (1,0) [0|72057594037927935] "Unit_None"  Vector__XXX
 SG_ SOK_Zeit_BMS_48V_Signatur : 64|64@1+ (1,0) [0|18446744073709551615] ""  Vector__XXX

BO_ 2464153925 SOK_Zeit_BMS_NV_Chal_01: 8 BMS_NV_12V
 SG_ SOK_Zeit_BMS_NV_Challenge : 0|64@1+ (1,0) [0|18446744073709551615] "Unit_None"  Gateway_Max

BO_ 2464284997 SOK_Zeit_BMS_NV_Resp_01: 16 Gateway_Max
 SG_ SOK_Zeit_BMS_NV_Zeit : 0|56@1+ (1,0) [0|72057594037927935] "Unit_None"  BMS_NV_12V
 SG_ SOK_Zeit_BMS_NV_Signatur : 64|64@1+ (1,0) [0|18446744073709551615] ""  BMS_NV_12V

BO_ 2464153665 SOK_Zeit_DCDC_Chal_01: 8 Vector__XXX
 SG_ SOK_Zeit_DCDC_Challenge : 0|64@1+ (1,0) [0|18446744073709551615] "Unit_None"  Gateway_Max

BO_ 2464153785 SOK_Zeit_DCDC_NV_Chal_01: 8 Vector__XXX
 SG_ SOK_Zeit_DCDC_NV_Challenge : 0|64@1+ (1,0) [0|18446744073709551615] "Unit_None"  Gateway_Max

BO_ 2464284857 SOK_Zeit_DCDC_NV_Resp_01: 16 Gateway_Max
 SG_ SOK_Zeit_DCDC_NV_Zeit : 0|56@1+ (1,0) [0|72057594037927935] "Unit_None"  Vector__XXX
 SG_ SOK_Zeit_DCDC_NV_Signatur : 64|64@1+ (1,0) [0|18446744073709551615] ""  Vector__XXX

BO_ 2464284737 SOK_Zeit_DCDC_Resp_01: 16 Gateway_Max
 SG_ SOK_Zeit_DCDC_Zeit : 0|56@1+ (1,0) [0|72057594037927935] "Unit_None"  Vector__XXX
 SG_ SOK_Zeit_DCDC_Signatur : 64|64@1+ (1,0) [0|18446744073709551615] ""  Vector__XXX

BO_ 2464153723 SOK_Zeit_Hybrid_01_Chal_01: 8 Vector__XXX
 SG_ SOK_Zeit_Hybrid_01_Challenge : 0|64@1+ (1,0) [0|18446744073709551615] "Unit_None"  Gateway_Max

BO_ 2464284795 SOK_Zeit_Hybrid_01_Resp_01: 16 Gateway_Max
 SG_ SOK_Zeit_Hybrid_01_Zeit : 0|56@1+ (1,0) [0|72057594037927935] "Unit_None"  Vector__XXX
 SG_ SOK_Zeit_Hybrid_01_Signatur : 64|64@1+ (1,0) [0|18446744073709551615] "Unit_None"  Vector__XXX

BO_ 2464153670 SOK_Zeit_Klima_Chal_01: 8 Klima
 SG_ SOK_Zeit_Klima_Challenge : 0|64@1+ (1,0) [0|18446744073709551615] "Unit_None"  Gateway_Max

BO_ 2464284742 SOK_Zeit_Klima_Signatur_Resp_01: 8 Gateway_Max
 SG_ SOK_Zeit_Klima_Signatur : 0|64@1+ (1,0) [0|18446744073709551615] ""  Klima

BO_ 2464288838 SOK_Zeit_Klima_Zeit_Resp_01: 8 Gateway_Max
 SG_ SOK_Zeit_Klima_Zeit : 0|56@1+ (1,0) [0|72057594037927935] "Unit_None"  Klima

BO_ 2464153668 SOK_Zeit_Ladegeraet_Chal_01: 8 Vector__XXX
 SG_ SOK_Zeit_OCC_Challenge : 0|64@1+ (1,0) [0|18446744073709551615] "Unit_None"  Gateway_Max

BO_ 2464284740 SOK_Zeit_Ladegeraet_Resp_01: 16 Gateway_Max
 SG_ SOK_Zeit_OCC_Zeit : 0|56@1+ (1,0) [0|72057594037927935] "Unit_None"  Vector__XXX
 SG_ SOK_Zeit_OCC_Signatur : 64|64@1+ (1,0) [0|18446744073709551615] ""  Vector__XXX

BO_ 2464153883 SOK_Zeit_SACID_1_Chal_01: 8 Vector__XXX
 SG_ SOK_Zeit_SACID_1_Challenge : 0|64@1+ (1,0) [0|18446744073709551615] "Unit_None"  Gateway_Max

BO_ 2464284955 SOK_Zeit_SACID_1_Resp_01: 16 Gateway_Max
 SG_ SOK_Zeit_SACID_1_Zeit : 0|56@1+ (1,0) [0|72057594037927935] "Unit_None"  Vector__XXX
 SG_ SOK_Zeit_SACID_1_Signatur : 64|64@1+ (1,0) [0|18446744073709551615] ""  Vector__XXX

BO_ 1467 SoSe_01: 8 Gateway_Max
 SG_ SoSe_SunInt_2D_Li : 0|8@1+ (5,0) [0|1200] "Unit_WattPerMeterSquar"  Gateway_Max,Klima
 SG_ SoSe_SunInt_2D_Re : 8|8@1+ (5,0) [0|1200] "Unit_WattPerMeterSquar"  Gateway_Max,Klima

BO_ 2527679739 Standklima_01: 8 Gateway_Max
 SG_ STK_Betriebsdauer : 5|7@1+ (1,0) [0|120] "Unit_Minut"  Klima
 SG_ STK_FSH_Anf : 12|1@1+ (1.0,0.0) [0.0|1] ""  Klima
 SG_ STK_HSH_Anf : 13|1@1+ (1.0,0.0) [0.0|1] ""  Klima
 SG_ STK_Klima_Temp : 14|5@1+ (0.5,15.5) [15.5|29.5] "Unit_DegreCelsi"  Klima
 SG_ STK_KurzVK_Anf : 19|1@1+ (1.0,0.0) [0.0|1] ""  Klima
 SG_ STK_Standklima_Anf : 20|1@1+ (1.0,0.0) [0.0|1] ""  Klima
 SG_ STK_Standklima_Timer_Status : 21|1@1+ (1.0,0.0) [0.0|1] ""  Klima
 SG_ STK_AirCLeaner_Anf : 22|1@1+ (1.0,0.0) [0.0|1] ""  Klima
 SG_ STK_VK_Modus : 23|2@1+ (1.0,0.0) [0.0|3] ""  Klima
 SG_ STK_ErwVK_Anf : 25|1@1+ (1.0,0.0) [0.0|1] ""  Klima
 SG_ STK_ErwVK_Modus : 26|4@1+ (1.0,0.0) [0.0|15] ""  Klima
 SG_ STK_Berechnungsphase : 30|2@1+ (1.0,0.0) [0.0|3] ""  Klima
 SG_ STK_VK_Timer_Status : 32|2@1+ (1.0,0.0) [0.0|3] ""  Vector__XXX
 SG_ STK_Anf_AussenspiegelHZ : 34|1@1+ (1.0,0.0) [0.0|1] ""  Klima
 SG_ STK_ErwVK_Beifahrerzone : 35|1@1+ (1.0,0.0) [0.0|1] ""  Klima
 SG_ STK_ErwVK_Fahrerzone : 36|1@1+ (1.0,0.0) [0.0|1] ""  Klima
 SG_ STK_ErwVK_Heckzone_links : 37|1@1+ (1.0,0.0) [0.0|1] ""  Klima
 SG_ STK_ErwVK_Heckzone_rechts : 38|1@1+ (1.0,0.0) [0.0|1] ""  Klima
 SG_ STK_ErwVK_Scheibenheizung : 39|1@1+ (1.0,0.0) [0.0|1] ""  Klima
 SG_ STK_VK_STH_Einsatz : 40|3@1+ (1.0,0.0) [0.0|7] ""  Klima
 SG_ STK_Voko_LED : 43|1@1+ (1.0,0.0) [0.0|1] ""  Klima
 SG_ STK_MaxLeistung : 44|8@1+ (0.1,0) [0.0|15.0] "Unit_KiloWatt"  Klima
 SG_ STK_GesamtEnergiebedarf : 52|8@1+ (0.1,0) [0.0|15.0] "Unit_KiloWattHour"  Vector__XXX
 SG_ STK_Stecker_Status : 60|2@1+ (1.0,0.0) [0.0|3] ""  Klima
 SG_ STK_ErwVK_Heckzone2_links : 62|1@1+ (1.0,0.0) [0.0|1] ""  Klima
 SG_ STK_ErwVK_Heckzone2_rechts : 63|1@1+ (1.0,0.0) [0.0|1] ""  Klima

BO_ 1313 STH_01: 8 Gateway_Max
 SG_ STH_Funk_ein : 0|1@1+ (1.0,0.0) [0.0|1] ""  Vector__XXX
 SG_ STH_Funk_aus : 1|1@1+ (1.0,0.0) [0.0|1] ""  Vector__XXX
 SG_ STH_Zusatzheizung : 2|1@1+ (1.0,0.0) [0.0|1] ""  Vector__XXX
 SG_ STH_LED : 3|1@1+ (1.0,0.0) [0.0|1] ""  Klima
 SG_ STH_Pumpe_ein : 4|1@1+ (1,0) [0|1] ""  Vector__XXX
 SG_ STH_Geblaese : 5|1@1+ (1.0,0.0) [0.0|1] ""  Klima
 SG_ STH_EKP_Anst : 6|1@1+ (1.0,0.0) [0.0|1] ""  Vector__XXX
 SG_ STH_Start_folgt : 7|1@1+ (1.0,0.0) [0.0|1] ""  Vector__XXX
 SG_ STH_Ventiloeffnungszeit : 8|6@1+ (1,0) [0|63] "Unit_Minut"  Vector__XXX
 SG_ STH_Ventil_Status : 14|1@1+ (1.0,0.0) [0.0|1] ""  Klima
 SG_ STH_Fehler_ElWaPu : 15|1@1+ (1.0,0.0) [0.0|1] ""  Vector__XXX
 SG_ STH_Waermeeintrag : 16|6@1+ (1,0) [0|63] "Unit_None"  Klima
 SG_ STH_Pumpen_Anf_extern : 22|1@1+ (1.0,0.0) [0.0|1] ""  Vector__XXX
 SG_ STH_KL_HUP : 23|1@1+ (1.0,0.0) [0.0|1] ""  Klima
 SG_ STH_KVS : 24|13@1+ (1,0) [0|8191] "Unit_MilliLiter"  Vector__XXX
 SG_ STH_Fehlerstatus : 37|3@1+ (1.0,0.0) [0.0|7] ""  Klima
 SG_ STH_Heizleistung : 40|8@1+ (1,0) [0|255] ""  Klima
 SG_ STH_Wassertemp : 48|8@1+ (0.75,-40) [-40.00|142.25] "Unit_DegreCelsi"  Klima
 SG_ STH_Texte : 56|3@1+ (1.0,0.0) [0.0|7] ""  Klima
 SG_ STH_Motorvorwaermung : 59|1@1+ (1.0,0.0) [0.0|1] ""  Vector__XXX
 SG_ STH_Servicemode : 60|1@1+ (1.0,0.0) [0.0|1] ""  Vector__XXX
 SG_ STH_war_aktiv : 61|1@1+ (1.0,0.0) [0.0|1] ""  Klima
 SG_ STH_KVS_Ueberlauf : 62|1@1+ (1.0,0.0) [0.0|1] ""  Vector__XXX
 SG_ STH_SH_ZH : 63|1@1+ (1.0,0.0) [0.0|1] ""  Klima

CM_ BO_ 2621506048 "VDC funktionaler Request auf CANFD";
CM_ BO_ 1328 "PTC";
CM_ BO_ 1440 "8Byte ab MLBevo
LIN-CAN (1:1) Botschaften werden geroutet
-  wenn entsprechender Slave codiert ist
-  wenn fehlerfreie Kommunikation zum Slave besteht
-  bei fehlerhafter Kommunikation zum Slave wird die Botschaft für 4s mit den letzten gültigen Werte";
CM_ BO_ 1504 "MLBevo 8Byte
LIN-CAN (1:1) Botschaft wird geroutet:
- wenn entsprechender Slave codiert ist
- wenn fehlerfreie Kommunikation zum Slave besteht
- bei fehlerhafter Kommunikation zum Slave wird die Botschaft für 4s mit den letzten gültigen Werten versend";
CM_ BO_ 980 "Ab MQB 7.2";

CM_ SG_ 1156 ND_GDOP "geometric dilution of precision (Gesamtgenauigkeit, 3D und Zeit) 
";
CM_ SG_ 1156 ND_HDOP "horizontal dilution of precision (Horizontalrichtung, 2D)
";
CM_ SG_ 1156 ND_Heading "Fahrtrichtung";
CM_ SG_ 1156 ND_Init "Initialisierung";
CM_ SG_ 1156 ND_PDOP "positional dilution of precision (Positionsgenauigkeit, 3D) 
";
CM_ SG_ 1156 ND_TDOP "time dilution of precision (Zeitgenauigkeit)
";
CM_ SG_ 1156 ND_VDOP "vertical dilution of precision (Vertikalrichtung, 1D)
";

CM_ SG_ 1157 ND_SatInUse "Anzahl der zur Berechnung verwendeten Satelliten";
CM_ SG_ 1157 ND_SatInView "Anzahl der sichtbaren Satelliten";
CM_ SG_ 1157 ND_UTC "UTC-Zeit, verstrichene Sekunden seit 01.01.1970 00:00
0xFFFFFFFE = Init
0xFFFFFFFF = Fehler bei Berechnung der UTC-Time";
CM_ SG_ 1157 NP_Altitude "Hoehe ueber NN
0xFFF = Fehler bei der Berechnung der Höhe über NN";
CM_ SG_ 1157 POS_Guete_horizontal "Horizontale Genauigkeit der Position in der Botschaft NavPos_02_MapMatched (Signale
POS_LatDegree, POS_LongDegree)

Abhängig vom Signal
POS_Guete_horizontal_verfuegbar";
CM_ SG_ 1157 POS_Guete_horizontal_verfuegbar "Bei gesetztem Bit wird das Signal POS_Guete_horizontal befüllt und ist verfügbar.";

CM_ SG_ 1158 NP_LatDegree "Latitude (Nord-Süd Wert)";
CM_ SG_ 1158 NP_LatDirection "Hemisphäre Nord/Süd";
CM_ SG_ 1158 NP_LongDegree "Longitude (Ost-West Wert)";
CM_ SG_ 1158 NP_LongDirection "Hemisphäre Ost/West";
CM_ SG_ 1158 NP_Sat "Nummer der verwendeten Sateliten beim letzten Fix";

CM_ SG_ 2600468805 NM_BMS_NV_CAB_V14 "CAB = Clusteraktivbits (V14)";
CM_ SG_ 2600468805 NM_BMS_NV_Car_Wakeup "Car Wakeup (Gateway wertet aus)";
CM_ SG_ 2600468805 NM_BMS_NV_CBV_AWB "Das Signal ist zu setzen, wenn das SG aktiv den Bus geweckt hat
0 = Passiver_WakeUp = SG hat das Netzwerk nicht aktiv geweckt
1 = Akitiver_WakeUp = SG hat das Netzwerk aktiv geweckt";
CM_ SG_ 2600468805 NM_BMS_NV_CBV_CRI "Das Signal ist dauerhaft gesetzt, wenn das NM-Layout Cluster- Anforderungen enthält";
CM_ SG_ 2600468805 NM_BMS_NV_NM_aktiv_Diagnose "Diagnose befindet sich nach VW80124 in einer NonDefaultDiagnostic-Session, z.B. ExtendedDiagnostic-Session";
CM_ SG_ 2600468805 NM_BMS_NV_NM_aktiv_KL15 "Steuergerät hat KL15-EIN erkannt";
CM_ SG_ 2600468805 NM_BMS_NV_NM_aktiv_Tmin "Mindestaktivzeit ist noch nicht abgelaufen (bei jedem Weckereignis wird die Mindestaktivzeit neu gestartet)";
CM_ SG_ 2600468805 NM_BMS_NV_NM_State "1 = Zustand Repeat Message (<-- Bus-Sleep Mode)
2 = Zustand Repeat Message (<-- Prepare Bus-Sleep Mode)
4 = Zustand Normal Operation (<-- Repeat Message)
8 = Zustand Normal Operation (<-- Ready Sleep)";
CM_ SG_ 2600468805 NM_BMS_NV_UDS_CC "Funktionseinschränkung aufgrund aktivem UDS-Communication Control, siehe VW80124";

CM_ SG_ 2600468665 NM_DCDC_CAB_V14 "CAB = Clusteraktivbits (V14)";
CM_ SG_ 2600468665 NM_DCDC_NV_aktiv_Tmin_NO "Mindestaktivzeit in NormalOperation ist noch nicht abgelaufen";
CM_ SG_ 2600468665 NM_DCDC_NV_Car_Wakeup "Car Wakeup (Gateway wertet aus)

MQB:
aktuell kein Car Wakeup Grund seitens DCDC NV";
CM_ SG_ 2600468665 NM_DCDC_NV_CBV_AWB "Das Signal ist zu setzen, wenn das SG aktiv den Bus geweckt hat
0 = Passiver_WakeUp = SG hat das Netzwerk nicht aktiv geweckt
1 = Akitiver_WakeUp = SG hat das Netzwerk aktiv geweckt";
CM_ SG_ 2600468665 NM_DCDC_NV_CBV_CRI "Das Signal ist dauerhaft gesetzt, wenn das NM-Layout Cluster- Anforderungen enthält";
CM_ SG_ 2600468665 NM_DCDC_NV_DCDC_aktiv "Dieser Bus wird wachgehalten, weil DCDC_NV aktiv";
CM_ SG_ 2600468665 NM_DCDC_NV_NM_aktiv_Diagnose "Diagnose befindet sich nach VW80124 in einer NonDefaultDiagnostic-Session, z.B. ExtendedDiagnostic-Session";
CM_ SG_ 2600468665 NM_DCDC_NV_NM_aktiv_KL15 "Steuergerät hat KL15-EIN erkannt";
CM_ SG_ 2600468665 NM_DCDC_NV_NM_aktiv_Tmin "Mindestaktivzeit ist noch nicht abgelaufen (bei jedem Weckereignis wird die Mindestaktivzeit neu gestartet)";
CM_ SG_ 2600468665 NM_DCDC_NV_NM_State "1 = Zustand Repeat Message (<-- Bus-Sleep Mode)
2 = Zustand Repeat Message (<-- Prepare Bus-Sleep Mode)
4 = Zustand Normal Operation (<-- Repeat Message)
8 = Zustand Normal Operation (<-- Ready Sleep)";
CM_ SG_ 2600468665 NM_DCDC_NV_UDS_CC "Funktionseinschränkung aufgrund aktivem UDS-Communication Control, siehe VW80124";

CM_ SG_ 2600468496 NM_Gateway_CAB_V14 "CAB = Clusteraktivbits (V14)

Cluster CAB_01_Antrieb
-Innenraumklimatisierung starten
-Ladevorbedingung, Beginn des Ladens, Ende
-Lademodusänderung, Timer-Laden vs. Sofort Laden

Cluster CAB_02_Hybrid_Laden
-Laden an oder ausschalten
-Ladevorbedi";
CM_ SG_ 2600468496 NM_Gateway_Car_Wakeup "Car Wakeup (Subbusmaster wertet aus)

MQB: 
-Diagnose- oder Komponentenschutzmaster-Funktion weckt den schlafenden Subbus (z.B. MOST)

E3_Volumen:
- Diagnose aktiv -aktive Diagnosekommunikation am OBD-Stecker

MQBw_Baseline:
- Diagnose aktiv -akt";
CM_ SG_ 2600468496 NM_Gateway_CBV_AWB "Das Signal ist zu setzen, wenn das SG aktiv den Bus geweckt hat
0 = Passiver_WakeUp = SG hat das Netzwerk nicht aktiv geweckt
1 = Akitiver_WakeUp = SG hat das Netzwerk aktiv geweckt";
CM_ SG_ 2600468496 NM_Gateway_CBV_CRI "Das Signal ist dauerhaft gesetzt, wenn das NM-Layout Cluster- Anforderungen enthält";
CM_ SG_ 2600468496 NM_Gateway_NM_aktiv_Buskopplung "Nachlauf aufgrund Kopplung zweier Busse. z.B. K-CAN und K2-CAN";
CM_ SG_ 2600468496 NM_Gateway_NM_aktiv_CWU "Nachlauf aufgrund CWU Anforderung";
CM_ SG_ 2600468496 NM_Gateway_NM_aktiv_Diagnose "Diagnose befindet sich nach VW80124 in einer NonDefaultDiagnostic-Session, z.B. ExtendedDiagnostic-Session";
CM_ SG_ 2600468496 NM_Gateway_NM_aktiv_EM "Nachlauf aufgrund Energiemanagement";
CM_ SG_ 2600468496 NM_Gateway_NM_aktiv_FC "Nachlauf aufgrund Funktionscluster Anforderung";
CM_ SG_ 2600468496 NM_Gateway_NM_aktiv_KL15 "Steuergerät hat KL15-EIN erkannt";
CM_ SG_ 2600468496 NM_Gateway_NM_aktiv_Tmin "Mindestaktivzeit ist noch nicht abgelaufen (bei jedem Weckereignis wird die Mindestaktivzeit neu gestartet)";
CM_ SG_ 2600468496 NM_Gateway_NM_State "1 = Zustand Repeat Message (<-- Bus-Sleep Mode)
2 = Zustand Repeat Message (<-- Prepare Bus-Sleep Mode)
4 = Zustand Normal Operation (<-- Repeat Message)
8 = Zustand Normal Operation (<-- Ready Sleep)";
CM_ SG_ 2600468496 NM_Gateway_UDS_CC "Funktionseinschränkung aufgrund aktivem UDS-Communication Control, siehe VW80124";

CM_ SG_ 2600468550 NM_Klima_CAB_V14 "CAB = Clusteraktivbits (V14)

Cluster - CAB_01_Antrieb
Standheizung ein- oder ausschalten: 
- STH-Taster gedrückt: direkte Aktivierung/Deaktivierung der Standheizung
- STH ein- oder ausschalten (zur programmierten Zeit oder mit Zielzeitlogik)
Restwä";
CM_ SG_ 2600468550 NM_Klima_Car_Wakeup "Car Wakeup (Gateway wertet aus)
MQB: STH einschalten (Zielzeitlogik), Standheizbetrieb angefordert (Sofortheiztaste gedrückt, Ein- und Ausschalten), Restwärmefunktion angefordert, Umentscheidung STL nach STH, Ablauf max Betriebsdauer

MLBevo: STH einsc";
CM_ SG_ 2600468550 NM_Klima_CBV_AWB "Das Signal ist zu setzen, wenn das SG aktiv den Bus geweckt hat";
CM_ SG_ 2600468550 NM_Klima_CBV_CRI "Das Signal ist dauerhaft gesetzt, wenn das NM-Layout dem neuen NM-Layout für Teilnetzbetrieb entspricht";
CM_ SG_ 2600468550 NM_Klima_NM_aktiv_Diagnose "Diagnose befindet sich nach VW80124 in einer NonDefaultDiagnostic-Session, z.B. ExtendedDiagnostic-Session";
CM_ SG_ 2600468550 NM_Klima_NM_aktiv_KL15 "Steuergerät hat KL15-EIN erkannt";
CM_ SG_ 2600468550 NM_Klima_NM_aktiv_STH "Nachlauf aufgrund aktiver Kommunikation mit STH
VW: EE-PROM-Daten speichern";
CM_ SG_ 2600468550 NM_Klima_NM_aktiv_Tmin "Mindestaktivzeit ist noch nicht abgelaufen (bei jedem Weckereignis wird die Mindestaktivzeit neu gestartet)";
CM_ SG_ 2600468550 NM_Klima_NM_State "1 = Zustand Repeat Message (<-- Bus-Sleep Mode)
2 = Zustand Repeat Message (<-- Prepare Bus-Sleep Mode)
4 = Zustand Normal Operation (<-- Repeat Message)
8 = Zustand Normal Operation (<-- Ready Sleep)";
CM_ SG_ 2600468550 NM_Klima_UDS_CC "Funktionseinschränkung aufgrund aktivem UDS-Communication Control; siehe VW80124";

CM_ SG_ 2527679508 NVEM_06_BZ "4bit Botschaftszähler, wird mit jeder Sendebotschaft inkrementiert";
CM_ SG_ 2527679508 NVEM_06_CRC "Für MLB:
'Berechnung siehe Lastenheft 'Kommunikationsabsicherung für FlexRay und CAN''

Ab MQB und MLBevo:
'Berechnung siehe Lastenheft 'End-to-End Kommunikationsabsicherung''

Endwerte siehe Begleitdokument 'S-PDU Kennungsfolgen'";
CM_ SG_ 2527679508 NVEM_Bordnetzdiagnose "Wird vom NVEM im NV-Netz ein Bordnetz-Fehler erkannt, so soll dies zu einer mehrstufigen Anzeige führen.";
CM_ SG_ 2527679508 NVEM_Energie_Klima_Vorgabe "NVEM-Energievorgabe für Klima-Vorkonditionierung";
CM_ SG_ 2527679508 NVEM_Max_Rampenzeit "Vorgabe der max. Rampenzeit für den Generatorbetrieb des 12V-RSG (RSG-Ansteuerung durch Motor-SG)";
CM_ SG_ 2527679508 NVEM_Max_Spannung "Mild_Hybrid: erlaubte Maximalspannung 12V - Netz
";
CM_ SG_ 2527679508 NVEM_Min_Spannung "Mild_Hybrid: erforderliche Mindestspannung 12V - Netz";
CM_ SG_ 2527679508 NVEM_Min_Spannung_Start "Minimale einzuhaltende Spannung im RSG Wiederstart";
CM_ SG_ 2527679508 NVEM_MV_DC_uMinLV "Abregelgrenze: minimal erlaubte Bordnetzspannung im Hochsetzbetrieb vom 12V-Bordnetz ins 48V-Netz";
CM_ SG_ 2527679508 NVEM_MV_DC_uSollLV "Sollwert für die 12V-Bordnetzspannung im Tiefsetzbetrieb vom 48V-Netz ins 12V-Bordnetz";

CM_ SG_ 527 NVEM_10_BZ "4bit Botschaftszähler, wird mit jeder Sendebotschaft inkrementiert";
CM_ SG_ 527 NVEM_10_CRC "Für MLB:
Berechnung siehe Lastenheft 'Kommunikationsabsicherung für FlexRay und CAN'
Ab MQB und MLBevo:
Berechnung siehe Lastenheft 'End-to-End Kommunikationsabsicherung'

Endwerte siehe Begleitdokument 'S-PDU Kennungsfolgen'";
CM_ SG_ 527 NVEM_DC_iSoll_NV "Soll-Entladestrom 12V Seite des DCDC Wandlers";
CM_ SG_ 527 NVEM_DC_uSoll_NV "Sollspannung 12V Seite des DC Wandlers, feine Auflösung";
CM_ SG_ 527 NVEM_IBatt "Strom der Bordnetzbatterie";
CM_ SG_ 527 NVEM_MOD_Budget "Füllstand des NV - Energie-Budgets für MD4";
CM_ SG_ 527 NVEM_MOD_Freigabe "Energiefreigabe für MOD  Funktionen";
CM_ SG_ 527 NVEM_MV_DC_iSoll_NV "Sollstromvorgabe NVEM an MV - DCDC Wandler";

CM_ SG_ 2621440668 OBDC_BMS_48V_Req_FD_Data "OnBoard Tester Diagnose Request BMS_48V";

CM_ SG_ 2621571740 OBDC_BMS_48V_Resp_FD_Data "OnBoard Tester Diagnose Response BMS_48V";

CM_ SG_ 2621702725 OBDC_BMS_NV_Req_FD_Data "TP-Kanal für den Onboard Datensammler";

CM_ SG_ 2621833797 OBDC_BMS_NV_Resp_FD_Data "TP-Kanal für den Onboard Datensammler";

CM_ SG_ 2621440697 OBDC_DCDC_NV_Req_FD_Data "OnBoard Tester Diagnose Request DCDC_NV";

CM_ SG_ 2621571769 OBDC_DCDC_NV_Resp_FD_Data "OnBoard Tester Diagnose Response DCDC_NV";

CM_ SG_ 2621440577 OBDC_DCDC_Req_FD_Data "OnBoard Tester Diagnose Request DCDC";

CM_ SG_ 2621571649 OBDC_DCDC_Resp_FD_Data "OnBoard Tester Diagnose Response DCDC";

CM_ SG_ 2621506048 OBDC_Funktion_Req_All_FD_Data "OnBoard Tester funktionaler Diagnose Request ALL";

CM_ SG_ 2621440635 OBDC_Hybrid_01_Req_FD_Data "OnBoard Tester Diagnose Request Hybrid_01";

CM_ SG_ 2621571707 OBDC_Hybrid_01_Resp_FD_Data "OnBoard Tester Diagnose Response Hybrid_01";

CM_ SG_ 2621440582 OBDC_Klima_Req_FD_Data "OnBoard Tester Diagnose über ISO TP.";

CM_ SG_ 2621571654 OBDC_Klima_Resp_FD_Data "OnBoard Tester Diagnose über ISO TP.";

CM_ SG_ 2621440580 OBDC_Ladegeraet_Req_FD_Data "OnBoard Tester Diagnose Request Ladegeraet";

CM_ SG_ 2621571652 OBDC_Ladegeraet_Resp_FD_Data "OnBoard Tester Diagnose Response Ladegeraet";

CM_ SG_ 2621702683 OBDC_SACID_1_Req_FD_Data "OnBoard Tester Diagnose Request SACID_1";

CM_ SG_ 2621833755 OBDC_SACID_1_Resp_FD_Data "OnBoard Tester Diagnose Response SACID_1";

CM_ SG_ 2549903569 OBDC_SSN_CMC_01_Req_Data "Request FID- zu NA- Kommunikation zw. OnboardDiagnoseClient und DK2F Sub-System-Knoten CMC_01 ... 16";

CM_ SG_ 2550034641 OBDC_SSN_CMC_01_Resp_Data "Response FID- zu NA- Kommunikation zw. OnboardDiagnoseClient und DK2F Sub-System-Knoten CMC_01 ... 16";

CM_ SG_ 2549903573 OBDC_SSN_CMC_05_Req_Data "Request FID- zu NA- Kommunikation zw. OnboardDiagnoseClient und DK2F Sub-System-Knoten CMC_01 ... 16";

CM_ SG_ 2550034645 OBDC_SSN_CMC_05_Resp_Data "Response FID- zu NA- Kommunikation zw. OnboardDiagnoseClient und DK2F Sub-System-Knoten CMC_01 ... 16";

CM_ SG_ 2549903577 OBDC_SSN_CMC_09_Req_Data "Request FID- zu NA- Kommunikation zw. OnboardDiagnoseClient und DK2F Sub-System-Knoten CMC_01 ... 16";

CM_ SG_ 2550034649 OBDC_SSN_CMC_09_Resp_Data "Response FID- zu NA- Kommunikation zw. OnboardDiagnoseClient und DK2F Sub-System-Knoten CMC_01 ... 16";

CM_ SG_ 2549903601 OBDC_SSN_CMC_13_Req_Data "Request FID- zu NA- Kommunikation zw. OnboardDiagnoseClient und DK2F Sub-System-Knoten CMC_01 ... 16";

CM_ SG_ 2550034673 OBDC_SSN_CMC_13_Resp_Data "Response FID- zu NA- Kommunikation zw. OnboardDiagnoseClient und DK2F Sub-System-Knoten CMC_01 ... 16";

CM_ SG_ 2564502513 OBDx_allOBD_Req_Data "Generic Scan Tool funktionaler Diagnose Request ALL OBD";

CM_ SG_ 2564428273 OBDx_BMS_48V_Req_Data "Generic Scan Tool funktionaler Diagnose Request ALL OBD";

CM_ SG_ 2564485393 OBDx_BMS_48V_Resp_Data "Generic Scan Tool funktionaler Diagnose Request ALL OBD";

CM_ SG_ 2564433393 OBDx_BMS_NV_Req_Data "29bit OBD Diagnose";

CM_ SG_ 2564485413 OBDx_BMS_NV_Resp_Data "29bit OBD Diagnose";

CM_ SG_ 2564426737 OBDx_DCDC_NV_Req_Data "29bit OBD Diagnose";

CM_ SG_ 2564485387 OBDx_DCDC_NV_Resp_Data "29bit OBD Diagnose";

CM_ SG_ 2564425201 OBDx_Hybrid_01_Req_Data "Generic Scan Tool funktionaler Diagnose Request ALL OBD";

CM_ SG_ 2564485381 OBDx_Hybrid_01_Resp_Data "Generic Scan Tool funktionaler Diagnose Request ALL OBD";

CM_ SG_ 2564426481 OBDx_Klima_Req_Data "29bit OBD Diagnose";

CM_ SG_ 2564485386 OBDx_Klima_Resp_Data "29bit OBD Diagnose";

CM_ SG_ 2564426993 OBDx_Ladegeraet_Req_Data "Generic Scan Tool funktionaler Diagnose Request ALL OBD";

CM_ SG_ 2564485388 OBDx_Ladegeraet_Resp_Data "Generic Scan Tool funktionaler Diagnose Request ALL OBD";

CM_ SG_ 2463978776 HVLE_AnzahlVerwendeterPhasen "Gibt die Anzahl der verwendeten Phasen für das AC Laden an";
CM_ SG_ 2463978776 HVLE_AsymmetrischLadenMoeglich "Information ob das Ladegerät ein asymetrisches Laden bauartbedingt unterstützt";
CM_ SG_ 2463978776 HVLE_Derating_Temperatur "Derating-Status aufgrund von Temperaturbegrenzungen des Ladegeraet";
CM_ SG_ 2463978776 HVLE_Energiemenge_Laden "Energiemenge, die von dem Ladegeraet ueber einen definierten Zeitraum an das Fahrzeug geliefert wurde";
CM_ SG_ 2463978776 HVLE_I_istAC_Netz_L1 "aktueller AC-Iststrom am Eingangskreis Phase 1 des Ladegeraet";
CM_ SG_ 2463978776 HVLE_I_istAC_Netz_L2 "aktueller AC-Iststrom am Eingangskreis Phase 2 des Ladegeraet";
CM_ SG_ 2463978776 HVLE_I_istAC_Netz_L3 "aktueller AC-Iststrom am Eingangskreis Phase 3 des Ladegeraet";
CM_ SG_ 2463978776 HVLE_Ist_Wirkungsgrad "aktueller Wirkungsgrad des Ladegeraet";
CM_ SG_ 2463978776 HVLE_IstSpannung_HV "aktuelle DC-Ausgangsspannung des Ladegeraet";
CM_ SG_ 2463978776 HVLE_Netzfrequenz_EVU "aktuelle AC-Netzfrequenz im Eingangskreis des Ladegeraet";
CM_ SG_ 2463978776 HVLE_Netzmodus "Das Ladegeraet signalisiert hier den aktuellen Netzmodus. (1-phasig, 2-phasig, 3phasig, usw.)";
CM_ SG_ 2463978776 HVLE_OBG_AC_maxSpannung "Bauteiltechnischer Grenzwert der maximalen nominellen Spannung gemessen zwischen Phase und Neutral.";
CM_ SG_ 2463978776 HVLE_OBG_AC_maxStrom "auteiltechnischer Grenzwert des maximalen Stroms pro Phase welches vom Ladegerät unterstützt wird.";
CM_ SG_ 2463978776 HVLE_OBG_ACDC_IstLeistung "Aktuelle Ist-Leistung des Onboardgleichrichters nach der AC-DC-Umwandlung inkl. Verluste des Wirkungsgrades";
CM_ SG_ 2463978776 HVLE_OBG_ACDC_MaxLeistung "Maximale mögliche Leistung des Onboardgleichrichters nach der AC-DC-Umwandlung inkl. Verluste des Wirkungsgrades";
CM_ SG_ 2463978776 HVLE_OBG_DC_IstStrom "aktueller Iststrom des OCC";
CM_ SG_ 2463978776 HVLE_OBG_DC_MaxStrom "maximaler Strom den das Ladegeraet bei der aktuellen Spannungslage und des vorgegebenen AC-Aufnahmenstrom stellen kann";
CM_ SG_ 2463978776 HVLE_OBG_Fehlerstatus "Gibt an, ob bei dem Ladegerät ein Fehler anliegt.";
CM_ SG_ 2463978776 HVLE_OBG_Fehlerstrom "Fehlerstrom der durch einen Isolationsfehler (z.B. schadhafte Isolierung, Berührung) vom Betriebsmittel zum Erdungssystem abfließt. Dies können hier AC- oder DC-Ströme sein.";
CM_ SG_ 2463978776 HVLE_OBG_IstModus "aktueller Funktionszustand des Ladegeraet";
CM_ SG_ 2463978776 HVLE_OBG_Kuehltemperatur "aktuelle Kuehlmitteltemperatur des OBGs";
CM_ SG_ 2463978776 HVLE_OBG_Status_EoHVL "Erkennung einer offenen HV-Leitung (EoHVL), bewertet anhand einer Spannungsgrenze";
CM_ SG_ 2463978776 HVLE_OBG_Status_Spgfreiheit "Status der Spannungsfreiheit für den Onboard Charge Client";
CM_ SG_ 2463978776 HVLE_OBG_Typ_verbaut "Typ des verbauten Onboard-Gleichrichters";
CM_ SG_ 2463978776 HVLE_OBG_Warnzustand "Zeigt an, ob eine Warnung für das Ladegerät aufgetreten ist.";
CM_ SG_ 2463978776 HVLE_PE_Monitor "Messung des PE-Leiters der Infrastruktur bei galvanisch nicht getrennten Onboard Gleichrichtern.";
CM_ SG_ 2463978776 HVLE_U_istAC_Netz_L1 "aktuelle AC-Istspannung am Eingangskreis Phase 1 des Ladegeraet";
CM_ SG_ 2463978776 HVLE_U_istAC_Netz_L2 "aktuelle AC-Istspannung am Eingangskreis Phase 2 des Ladegeraet";
CM_ SG_ 2463978776 HVLE_U_istAC_Netz_L3 "aktuelle AC-Istspannung am Eingangskreis Phase 3 des Ladegeraet";
CM_ SG_ 2463978776 OBG_01_BZ "4bit Botschaftszähler, wird mit jeder Sendebotschaft inkrementiert";
CM_ SG_ 2463978776 OBG_01_CRC "Für MLB:
Berechnung siehe Lastenheft 'Kommunikationsabsicherung für FlexRay und CAN'
Ab MQB und MLBevo:
Berechnung siehe Lastenheft 'End-to-End Kommunikationsabsicherung'

Endwerte siehe Begleitdokument 'S-PDU Kennungsfolgen'";
CM_ SG_ 2463978776 SOK_OBG_01_Signatur "Signatur im Rahmen des SOK.

Geschützte Funktion:	
Geschützte Signale:  	";

CM_ SG_ 2589283656 ORU_Status "Verteilung des internen ORU Zustandes";
CM_ SG_ 2589283656 ORU_Warnung "Wenn durch Störungen der Funktion Online Remote Update nicht sichergestellt ist, dass vor Kunde keine Funktionseinschränkungen auftreten, muss der Benutzer des Fahrzeugs entsprechend gewarnt werden.";

CM_ SG_ 2527679498 IAA_Active_User_ID "Signal gibt die IAA Nutzer ID des aktiven IAA Nutzers an.";
CM_ SG_ 2527679498 IAA_Identified_User_ID "Signal gibt die IAA Nutzer ID des vom BCM identifizierten IAA Nutzers an";
CM_ SG_ 2527679498 IAA_PSO_wake_up "Signal zum Wake_up der IAA und PSO Komponenten im Kombi und in der OCU";
CM_ SG_ 2527679498 Perso_Aktiv "Status Personalisierung für den Fahrer aktiviert/ deaktiviert (via HMI)";
CM_ SG_ 2527679498 Perso_Bedienstelle "Signal zeigt an, über welche Bedienstelle die Umschaltung des Benutzerkontos gestartet wurden.";
CM_ SG_ 2527679498 Perso_Fahrernummer "Signal gibt die jewels aktuelle Nummer des Fahrers für die Personalisierung an.
Nicht für AU736 und AU48x.";
CM_ SG_ 2527679498 Perso_Freigabe_Verstellung "Signal zeigt an, ob die Ergonomiefunktionen nach Umschaltung des Benutzerkontos verfahren dürfen.";
CM_ SG_ 2527679498 Perso_Kontonummer "Signal gibt die jewels aktuelle Kontonummer für die Personalisierung an.
Nicht für AU736 und AU48x.";
CM_ SG_ 2527679498 Perso_Schreibschutz "Signal zeigt an, ob der Schreibschutz der Personalisierung aktiv ist.";
CM_ SG_ 2527679498 Perso_Status "Codierstatus der Personalisierung
Nicht für AU736 und AU49x.";
CM_ SG_ 2527679498 Perso_Steuerung "Signal gibt einen Steuerungsbefehl an die Funktionsteilnehmer der Personalisierung.
Nicht für AU736 und AU49x.";
CM_ SG_ 2527679498 Perso_Steuerungsparameter "Signal gibt einen Parameter zum Steuerungsbefehl (Signal Perso_Steuerung) für die Personalisierung an.
Nicht für AU736 und AU49x.";

CM_ SG_ 1328 PTC_Aktiv "1 = PTC-Elemente werden bestromt (Heizanforderung vom Bediengeraet und Aussen- und Kuehlwasser-temperaturbedingung erfuellt
Vorhalt fuer VW, nicht Audi B8";
CM_ SG_ 1328 PTC_Fehlerstatus "Fehlerstatus PTC Zuheizer; 0 = kein Fehler; 1 = Unterspannung; 2 = Ueberspannung; 3 = Ueberstrom; 4 = HW defekt; 5 = Ueberhitzung; 6...7 nicht definiert
Vorhalt fuer VW, nicht Audi B8";
CM_ SG_ 1328 PTC_I_ist "PTC Stromverbrauch (max. 120A)";
CM_ SG_ 1328 PTC_Nenn_Strom "Summe der Nennstroeme aller PTC-Heizelemente";
CM_ SG_ 1328 PTC_P_ist "PTC Leistungsaufnahme";
CM_ SG_ 1328 PTCs_01_alt "Veraltet Bit für die LIN-Botschaft PTCs_01. Betroffene Signale:

PTC_I_ist
PTC_P_ist";

CM_ SG_ 1616 RA_AM_Tuning "Das Signal kennzeichnet einen aktiven AM Suchlauf. Während des Suchlaufes wird die Frequenz = 0 übertragen.
0 = frequency locked => Störquelle vermeidet die aktuelle Frequenz
1 = AM tuning in progress => Störquelle abschalten bzw.PWM Signal auf DC umsch";
CM_ SG_ 1616 RA_Frequency "Übermittlung der eingestellten Sendefrequenz AM oder FM, diese wird mit RA_Frequency_unit multipliziert.
Im DAB oder Hybrid/Online Mode wird die aktuelle FM-Alternativfrequenz oder, falls nicht vorhanden, die zuletzt gehörte Senderfrequenz übertragen (AM";
CM_ SG_ 1616 RA_Frequency_unit "Faktor für RA_Frequency
bei AM: Faktor 0 = 1kHz
sonst   Faktor 1 = 100kHz";
CM_ SG_ 1616 RA_PowerAmpOn "1 = Request for Amplifier; 0 = Amplifier mute/off";
CM_ SG_ 1616 RA_Radio_Error_Flag "1 = mindestens ein Kundendienstfehlerspeicher Eintrag vorhanden";
CM_ SG_ 1616 RA_Radio_mute "1=Radio is muted for telephone";
CM_ SG_ 1616 RA_Radio_on "1 = user perceived On";
CM_ SG_ 1616 RA_Radio_Surround "1 = Surround ON; 0 = Surround OFF
requests the Amp to switch Surroundmode";
CM_ SG_ 1616 RA_VNC_OFF "VNC = Vehicle Noice Cancellation;
1 = VNC OFF; 0 = VNC ON
requests the Amp to switch VNC off";

CM_ SG_ 1525 RW_Gesamt_Reichweite "Reichweite für primär und sekundär Reichweite (eventuell Gewichtet)";
CM_ SG_ 1525 RW_Gesamt_Reichweite_Max_Anzeige "Angabe der Maximalen Anzeige der gesamten Reichweite.
Ergänzt das Signal RW_Gesamt_Reichweite_Anzeige.Die Einheit dieser Signal ist über RW_Reichweite_Einheit_Anzeige bereitgestellt.";
CM_ SG_ 1525 RW_Prim_Reichweitenv_Einheit "Für primäre  Reichweitenberechnung (KBI_Prim_Reichweitenverbrauch) zugrunde gelegte Einheit";
CM_ SG_ 1525 RW_Prim_Reichweitenverbrauch "Für primäre Reichweitenberechnung zugrunde gelegter Verbrauch";
CM_ SG_ 1525 RW_Primaer_Reichweite "Reichweite der primären Antriebsart";
CM_ SG_ 1525 RW_Reservewarnung_2_aktiv "Ansteuerung der Reservewarnung im Kombiinstrument (Leuchte und MFA-Warnhinweis). Wird gesetzt bei Erreichen / Unterschreiten eines unteren Reichweitenschwellwerts und zurückgenommen bei Erreich.
Zusätzlich erfolgt eine logische Verknüpfung mit einer akti";
CM_ SG_ 1525 RW_RWDS_Lastprofil "Lastprofil zur Bestimmung der notwendigen Nachladeenergie (Reichweitendurchschnittstrom)";

CM_ SG_ 1440 LS_defekt "Fehlererkennung Lichtsensor
";
CM_ SG_ 1440 LS_Helligkeit_FW "Vorfeldhelligkeit";
CM_ SG_ 1440 LS_Helligkeit_IR "Globalfeldhelligkeit";
CM_ SG_ 1440 LS_Verbau "Verbauinfo Lichtsensor";
CM_ SG_ 1440 RLS_Vorfeldhelligkeit_Boost "erweiterte Helligkeitssensierung für HUD";
CM_ SG_ 1440 RS_defekt "Fehlererkennung Regensensor";
CM_ SG_ 1440 RS_Regenmenge "Regenmenge";
CM_ SG_ 1440 RS_Schwall "Schwallereignis";
CM_ SG_ 1440 RS_Verbau "Verbauinfo Regensensor";
CM_ SG_ 1440 RS_Verglasung_schliessen "Anforderung: Verglasung schliessen
";
CM_ SG_ 1440 RS_Wischergeschwindigkeit "Wischergeschwindigkeit (Hübe/min)";
CM_ SG_ 1440 SLS_Helligkeit_IR "Helligkeitswert des 'Smart-Light-Sensor' im Dashboard analog / alternativ zu LS_Helligkeit_IR.

Es ist entweder ein RLS_LIN oder ein Smart-LS im FZG verbaut.";

CM_ SG_ 2584746776 SACID_1_AuthTime_Req_Data "AuthTime - Authentische Zeit
ISO-TP Datenkanal - NA2FID

SACID_1 an Funktion Authentische Zeit (Request)";

CM_ SG_ 2584877848 SACID_1_AuthTime_Resp_Data "AuthTime - Authentische Zeit
ISO-TP Datenkanal - NA2FID
Response Funktion 0x18 AuthTime

Funktion Authentische Zeit an SACID_1 (Response)";

CM_ SG_ 2630884158 SACID_1_PLC_Req_FD_Data "ISO-TP FD Request Datenkanal (Anfrage Client 'SACID_1') für Inhalte der Power-Line-Kommunikation bzw HEMS Kommunikation über WLAN";

CM_ SG_ 2631015230 SACID_1_PLC_Resp_FD_Data "ISO-TP FD Response Datenkanal (Antwort Server auf dem HCP5) für Inhalte der Power-Line-Kommunikation bzw HEMS Kommunikation über WLAN";

CM_ SG_ 1504 MD1_Lage "Lage Schiebedachstellung 1 (Signal wird 1:1 vom BCM2 geroutet; ursprünglicher Sender: SAD = LIN-Slave vom BCM2)";
CM_ SG_ 1504 MD1_Position "Aktuelle Öffnungsweite Schiebedach.";
CM_ SG_ 1504 MD3_Lage "Lage Schiebedachstellung 3 
(Signal wird 1:1 vom BCM2 geroutet; ursprünglicher Sender: SAD = LIN-Slave vom BCM2) 
";
CM_ SG_ 1504 MD3_Position "Schiebedachstellung 3 
(Signal wird 1:1 vom BCM2 geroutet; ursprünglicher Sender: SAD = LIN-Slave vom BCM2)
";
CM_ SG_ 1504 MRollo_Lage "Lage Rollo
(Signal wird 1:1 vom BCM2 geroutet; ursprünglicher Sender: Rollo = LIN-Slave vom BCM2)";
CM_ SG_ 1504 MRollo_Position "Aktuelle Öffnungsweite des Dachrollos.";
CM_ SG_ 1504 Rollo_normiert "Anzeigen Normierung des Dachrollos";
CM_ SG_ 1504 Rollo_Thermoschutz "Anzeigen aktivierter Thermoschutz des Dachrollo";
CM_ SG_ 1504 Rollo_UEKB_aktiv "Anzeigen aktivierter Überschusskraftbegrenzung des Dachrollos";
CM_ SG_ 1504 SAD_Anf_ESC_Zuschaltung "Zwangsaktivierung ESP durch SAD-SG (bei geöffnetem Schiebedach und V> xx km/h).";
CM_ SG_ 1504 SAD_normiert "Anzeige Normierung des Schiebeausstelldaches";
CM_ SG_ 1504 SAD_Taster_Deckel_hi "Taster für SAD Deckel hinten";
CM_ SG_ 1504 SAD_Taster_Deckel_vo "Taster für SAD Deckel vorne";
CM_ SG_ 1504 SAD_Taster_Rollo_hi "Taster für SAD Rollo hinten";
CM_ SG_ 1504 SAD_Taster_Rollo_vo "Taster für SAD Rollo vorne";
CM_ SG_ 1504 SAD_Thermoschutz "Anzeige aktivierter Thermoschutz des Schiebeausstelldaches";
CM_ SG_ 1504 SAD_UEKB_aktiv "Anzeige aktivierter Überschusskraftbegrenzung des Schiebeausstelldaches";

CM_ SG_ 980 BH_Blinker_Fehler "Anzeige, ob am Lenkstockschalter ein Fehler anliegt.
Notwendig aufgrund ASIL-Einstufung";
CM_ SG_ 980 BH_Blinker_li "Blinkerhebel Richtung links";
CM_ SG_ 980 BH_Blinker_re "Blinkerhebel Richtung rechts";
CM_ SG_ 980 BH_Fernlicht "Betaetigung Fernlicht
";
CM_ SG_ 980 BH_Lichthupe "Betaetigung Lichthupe
";
CM_ SG_ 980 FAS_Taster "Betaetigung FAS Taster
";
CM_ SG_ 980 FAS_Taster_Fehler "Fehlerstatus FAS Taster
";
CM_ SG_ 980 LRH_aktiv "Signal gibt an, ob ein Heizstrom durch die Lenkradheizung fließt. Es dient der Auswertung durch das Energiemanagement.";
CM_ SG_ 980 LRH_On_Off "Status Lenkradheizung";
CM_ SG_ 980 LSS_Tastencode "0x00 = No key pressed / key released
0x01 = Menu
0x02 = Menu Up / Next Screen
0x03 = Menu Down / Previous Screen
0x04 = Up
0x05 = Down
0x06 = Up / Down ThumbWheel
0x07 = OK (ThumbWheel-Button)
0x08 = Cancel / Escape
0x09..0x0F = reserved for furt";
CM_ SG_ 980 SMLS_01_BZ "4bit Botschaftszaehler, wird mit jeder Sendebotschaft inkrementiert";
CM_ SG_ 980 SMLS_01_CRC "Für MLB:
'Berechnung siehe Lastenheft 'Kommunikationsabsicherung für FlexRay und CAN''

Ab MQB und MLBevo:
'Berechnung siehe Lastenheft 'End-to-End Kommunikationsabsicherung''

Endwerte siehe Begleitdokument 'S-PDU Kennungsfolgen'";
CM_ SG_ 980 SMLS_Hupe "Betaetigung Hupe
";
CM_ SG_ 980 SMLS_P_verriegelt "Signal stellt den Status des Signals P-verriegelt auf den Fahrzeugbus zur Verfügung. Nutzer sind z.B. die ELV, die das Signal für die Verriegelung benötigt und die Funktion Verlassenswarnung, die den Fahrer beim Verrollen des Fahrzeugs warnt.";
CM_ SG_ 980 SMLS_P_verriegelt_plausibel "Signal stellt den Plausibilisierungstatus des Signals p_verriegelt auf den Fahrzeugbus zur Verfügung. Eine Plausibilität muss explizit erkannt werden. Initial wird 'unplausibel' gesendet. Ein plausibles Signal wird erkannt, wenn p_verriegelt plausibel geg";
CM_ SG_ 980 SMLS_PTT "Betaetigung PTT";
CM_ SG_ 980 WH_Frontwaschen "Wischerhebel: Stellung Wisch Wasch vorne
";
CM_ SG_ 980 WH_Heckintervall "Wischerhebel: Stellung Heckintervall
";
CM_ SG_ 980 WH_Heckwaschen "Wischerhebel: Stellung Wisch Wasch hinten
";
CM_ SG_ 980 WH_Intervall "Wischerhebel: Stellung Intervall
";
CM_ SG_ 980 WH_Intervallstufen "Wischerhebel: Stellung Intervallstufen";
CM_ SG_ 980 WH_SRA "Scheinwerferreinigungsanlage

derzeit nur bei PAG umgesetzt";
CM_ SG_ 980 WH_Tipwischen "Wischerhebel: Tippwischen

MQB A0/ PQ26: Bei Verbau LSS (kein SMLS): gespiegelter Wert zu Signal WH_WischerStufe1";
CM_ SG_ 980 WH_Tipwischen_lang "Wischerhebel: Tippwischen lang
(dient zur Auswertung für die Unterscheidung Tippwischen oder Serviceposition Wischer)";
CM_ SG_ 980 WH_Wischer_Fehler "Anzeige, ob am Lenkstockschalter ein Fehler anliegt.
Notwendig aufgrund ASIL-Einstufung";
CM_ SG_ 980 WH_WischerStufe1 "Wischerhebel: Stufe Wischen 1
";
CM_ SG_ 980 WH_WischerStufe2 "Wischerhebel: Stufe Wischen 2
";

CM_ SG_ 2464157766 SOK_FoD_Klima_Req_Challenge "Challenge im Rahmen des SOK Challenge-Response Protokolls.

Geschützte Funktion: Function on Demand";

CM_ SG_ 2464292934 SOK_FoD_Klima_Resp_Challenge "Challenge im Rahmen des SOK Challenge-Response Protokolls.

Geschützte Funktion: Function on Demand";

CM_ SG_ 2589283756 SOK_ungeschuetzte_Zeit "Periodisch verschickter SOK Zeitwert des SOK Zeitmasters als Referenzzeit zur Erkennung von Clockjitter durch andere SOK Teilnehmer.

Der Empfang dieses Signals ist verpflichtend für jedes Steuergerät, das durch die authentische Broadcast Funktionalität";

CM_ SG_ 2464153756 SOK_Zeit_BMS_48V_Challenge "Challenge im Rahmen des SOK Challenge-Response Protokolls.

Geschützte Funktion: Empfang der SOK-Zeit vom SOK-Zeitmaster; verbindlich für Steuergeräte, welche mit der durch SOK geschützten Broadcast Nachrichten empfangen oder versenden";

CM_ SG_ 2464284828 SOK_Zeit_BMS_48V_Signatur "Signatur im Rahmen des SOK Challenge-Response Protokolls.

Geschützte Funktion: Empfang der SOK-Zeit vom SOK-Zeitmaster; verbindlich für Steuergeräte, welche mit der durch SOK geschützten Broadcast Nachrichten empfangen oder versenden";
CM_ SG_ 2464284828 SOK_Zeit_BMS_48V_Zeit "Aktueller Wert der SOK-Zeit des SOK-Zeitmasters; geschützt durch das SOK Challenge-Response Protokoll";

CM_ SG_ 2464153925 SOK_Zeit_BMS_NV_Challenge "Challenge im Rahmen des SOK Challenge-Response Protokolls.

Geschützte Funktion: Empfang der SOK-Zeit vom SOK-Zeitmaster; verbindlich für Steuergeräte, welche mit der durch SOK geschützten Broadcast Nachrichten empfangen oder versenden";

CM_ SG_ 2464284997 SOK_Zeit_BMS_NV_Signatur "Signatur im Rahmen des SOK Challenge-Response Protokolls.

Geschützte Funktion: Empfang der SOK-Zeit vom SOK-Zeitmaster; verbindlich für Steuergeräte, welche mit der durch SOK geschützten Broadcast Nachrichten empfangen oder versenden";
CM_ SG_ 2464284997 SOK_Zeit_BMS_NV_Zeit "Aktueller Wert der SOK-Zeit des SOK-Zeitmasters; geschützt durch das SOK Challenge-Response Protokoll";

CM_ SG_ 2464153665 SOK_Zeit_DCDC_Challenge "Challenge im Rahmen des SOK Challenge-Response Protokolls.

Geschützte Funktion: Empfang der SOK-Zeit vom SOK-Zeitmaster; verbindlich für Steuergeräte, welche mit der durch SOK geschützten Broadcast Nachrichten empfangen oder versenden";

CM_ SG_ 2464153785 SOK_Zeit_DCDC_NV_Challenge "Challenge im Rahmen des SOK Challenge-Response Protokolls.

Geschützte Funktion: Empfang der SOK-Zeit vom SOK-Zeitmaster; verbindlich für Steuergeräte, welche mit der durch SOK geschützten Broadcast Nachrichten empfangen oder versenden";

CM_ SG_ 2464284857 SOK_Zeit_DCDC_NV_Signatur "Signatur im Rahmen des SOK Challenge-Response Protokolls.

Geschützte Funktion: Empfang der SOK-Zeit vom SOK-Zeitmaster; verbindlich für Steuergeräte, welche mit der durch SOK geschützten Broadcast Nachrichten empfangen oder versenden";
CM_ SG_ 2464284857 SOK_Zeit_DCDC_NV_Zeit "Aktueller Wert der SOK-Zeit des SOK-Zeitmasters; geschützt durch das SOK Challenge-Response Protokoll";

CM_ SG_ 2464284737 SOK_Zeit_DCDC_Signatur "Signatur im Rahmen des SOK Challenge-Response Protokolls.

Geschützte Funktion: Empfang der SOK-Zeit vom SOK-Zeitmaster; verbindlich für Steuergeräte, welche mit der durch SOK geschützten Broadcast Nachrichten empfangen oder versenden";
CM_ SG_ 2464284737 SOK_Zeit_DCDC_Zeit "Aktueller Wert der SOK-Zeit des SOK-Zeitmasters; geschützt durch das SOK Challenge-Response Protokoll";

CM_ SG_ 2464153723 SOK_Zeit_Hybrid_01_Challenge "Challenge of SOK participant BMC_HV to SOK time server for requesting authentic SOK time";

CM_ SG_ 2464284795 SOK_Zeit_Hybrid_01_Signatur "Signature to protect authentic SOK time";
CM_ SG_ 2464284795 SOK_Zeit_Hybrid_01_Zeit "Response signal of SOK time server to challenge of an SOK participant, containing SOK time";

CM_ SG_ 2464153670 SOK_Zeit_Klima_Challenge "Challenge im Rahmen des SOK Challenge-Response Protokolls.

Geschützte Funktion: Empfang der SOK-Zeit vom SOK-Zeitmaster; verbindlich für Steuergeräte, welche mit der durch SOK geschützten Broadcast Nachrichten empfangen oder versenden";

CM_ SG_ 2464284742 SOK_Zeit_Klima_Signatur "Signatur im Rahmen des SOK Challenge-Response Protokolls.

Geschützte Funktion: Empfang der SOK-Zeit vom SOK-Zeitmaster; verbindlich für Steuergeräte, welche mit der durch SOK geschützten Broadcast Nachrichten empfangen oder versenden";

CM_ SG_ 2464288838 SOK_Zeit_Klima_Zeit "Aktueller Wert der SOK-Zeit des SOK-Zeitmasters; geschützt durch das SOK Challenge-Response Protokoll";

CM_ SG_ 2464153668 SOK_Zeit_OCC_Challenge "Challenge im Rahmen des SOK Challenge-Response Protokolls.

Geschützte Funktion: Empfang der SOK-Zeit vom SOK-Zeitmaster; verbindlich für Steuergeräte, welche mit der durch SOK geschützten Broadcast Nachrichten empfangen oder versenden";

CM_ SG_ 2464284740 SOK_Zeit_OCC_Signatur "Signatur im Rahmen des SOK Challenge-Response Protokolls.

Geschützte Funktion: Empfang der SOK-Zeit vom SOK-Zeitmaster; verbindlich für Steuergeräte, welche mit der durch SOK geschützten Broadcast Nachrichten empfangen oder versenden";
CM_ SG_ 2464284740 SOK_Zeit_OCC_Zeit "Aktueller Wert der SOK-Zeit des SOK-Zeitmasters; geschützt durch das SOK Challenge-Response Protokoll";

CM_ SG_ 2464153883 SOK_Zeit_SACID_1_Challenge "Challenge im Rahmen des SOK Challenge-Response Protokolls.

Geschützte Funktion: Empfang der SOK-Zeit vom SOK-Zeitmaster; verbindlich für Steuergeräte, welche mit der durch SOK geschützten Broadcast Nachrichten empfangen oder versenden";

CM_ SG_ 2464284955 SOK_Zeit_SACID_1_Signatur "Signatur im Rahmen des SOK Challenge-Response Protokolls.

Geschützte Funktion: Empfang der SOK-Zeit vom SOK-Zeitmaster; verbindlich für Steuergeräte, welche mit durch SOK geschütztem Broadcast Nachrichten empfangen oder versenden";
CM_ SG_ 2464284955 SOK_Zeit_SACID_1_Zeit "Aktueller Wert der SOK-Zeit des SOK-Zeitmasters; geschützt durch das SOK Challenge-Response Protokoll";

CM_ SG_ 1467 SoSe_SunInt_2D_Li "Sonnenintensität links (2D Sensor)";
CM_ SG_ 1467 SoSe_SunInt_2D_Re "Sonnenintensität rechts (2D Sensor)";

CM_ SG_ 2527679739 STK_AirCLeaner_Anf "Anforderung an das Klimasteuergerät dien Zustand der Umluftklappe zu ändern.";
CM_ SG_ 2527679739 STK_Anf_AussenspiegelHZ "Anforderung Außenspiegelheizung seitens Klimafunktion (z.B. bei Erweiterter VoKo)";
CM_ SG_ 2527679739 STK_Berechnungsphase "Status der Berechnungsphase Vorkonditionierung.

0 = keine Berechnungsphase
1 = Berechnungsphase erforderlich
2 = Init
3 = Fehler";
CM_ SG_ 2527679739 STK_Betriebsdauer "Betriebsdauer (TimeRemaining) Standklima Frontend";
CM_ SG_ 2527679739 STK_ErwVK_Anf "Anforderung  zur Aktivierung der Erweiterten-Vorkonditionierung  im  Innenraum";
CM_ SG_ 2527679739 STK_ErwVK_Beifahrerzone "Erweiterte Voko Beifahrerseite";
CM_ SG_ 2527679739 STK_ErwVK_Fahrerzone "Erweiterte Voko Fahrerseite";
CM_ SG_ 2527679739 STK_ErwVK_Heckzone2_links "Anforderung der erweiterten Standklimatisierung in der dritten Sitzreihe links";
CM_ SG_ 2527679739 STK_ErwVK_Heckzone2_rechts "Anforderung der erweiterten Standklimatisierung für die dritte Sitzreihe rechts.";
CM_ SG_ 2527679739 STK_ErwVK_Heckzone_links "Erweiterte Voko Sitzheizung hinten links";
CM_ SG_ 2527679739 STK_ErwVK_Heckzone_rechts "Erweiterte Voko Sitzheizung hinten rechts";
CM_ SG_ 2527679739 STK_ErwVK_Modus "Erweiterte Voko angefordert";
CM_ SG_ 2527679739 STK_ErwVK_Scheibenheizung "Erweiterte Voko Scheibenheizung Freigabe";
CM_ SG_ 2527679739 STK_FSH_Anf "Frontscheibenheizung anfordern";
CM_ SG_ 2527679739 STK_GesamtEnergiebedarf "Für den Klimavorgang benötigte Energie von ca. 15 kWh für Signal 
STK_GesamtEnergiebedarf";
CM_ SG_ 2527679739 STK_HSH_Anf "Heckscheibenheizung anfordern";
CM_ SG_ 2527679739 STK_Klima_Temp "MEB: Gewünschte Innenraumtemperatur, auf die bei der Standklimatisierung geregelt werden soll.
MQB: Temperatur die vom Nutzer vorgewählt wurde (VW: low=15,5 °C/ high=30,0°C)";
CM_ SG_ 2527679739 STK_KurzVK_Anf "Anforderung der kurz-Vorkonditionierung  zur Aktivierung der Vorkonditionierung Innenraum";
CM_ SG_ 2527679739 STK_MaxLeistung "Anforderung an  HVLM über den Maximalwert der angeforderten Energieleistung für Klima-Vorkonditionierung";
CM_ SG_ 2527679739 STK_Standklima_Anf "Anforderung der Vorkonditionierung zur Aktivierung der Vorkonditionierung Innenraum";
CM_ SG_ 2527679739 STK_Standklima_Timer_Status "Signalisierung an die Klima Black Box ob mind. ein Timer zur Standklimatisierung programmiert ist";
CM_ SG_ 2527679739 STK_Stecker_Status "Übermittlung Status des Ladesteckers für das Klima Steuergerät";
CM_ SG_ 2527679739 STK_VK_Modus "Übermittlung des aktuellen Konditionierungs-Status für HMI, Mobile Online Dienste";
CM_ SG_ 2527679739 STK_VK_STH_Einsatz "Anforderung(STK) an CCM zur Freigabe der Standheizung";
CM_ SG_ 2527679739 STK_VK_Timer_Status "Statusmeldung an BMCe zum Vorkonditionierungsmodus, zur Aktivierung der Vorkonditionierung der HV-Batterie.
'aktiv' = falls die Batterie einen Kühl-/Heizbedarf festgestellt hat, darf diese Batterie darf diese eine HV-Aktivierung anfordern und die Batteri";
CM_ SG_ 2527679739 STK_Voko_LED "Signalisierung des Standheizungsbetriebs";

CM_ SG_ 1313 STH_EKP_Anst "STH sendet die Anforderung zur Ansteuerung der EKP an den Motor, um Kraftstoffbehälter der STH zu befüllen.";
CM_ SG_ 1313 STH_Fehler_ElWaPu "Fehler der el. Zusatzwasserpumpe der zur Deaktivierung der Wasserpumpe führt ";
CM_ SG_ 1313 STH_Fehlerstatus "Übermittlung der unterschiedlichen Fehlerzustände der Standheizung";
CM_ SG_ 1313 STH_Funk_aus "Funkbefehl über Funkfernbedienung zum Ausschalten Standheizung";
CM_ SG_ 1313 STH_Funk_ein "Funkbefehl über Funkfernbedienung zum Einschalten Standheizung";
CM_ SG_ 1313 STH_Geblaese "Ein-/ Ausschaltbefehl an die Klimaanlage, Gebläse";
CM_ SG_ 1313 STH_Heizleistung "Heizleistung in %";
CM_ SG_ 1313 STH_KL_HUP "Signal HUP Aktivierung an Klima

0 = HUP aus
1 = HUP ein";
CM_ SG_ 1313 STH_KVS "Kraftstoffverbrauch";
CM_ SG_ 1313 STH_KVS_Ueberlauf "Kraftstoffverbrauch, Überlauf hat stattgefunden";
CM_ SG_ 1313 STH_LED "Funktionslampe";
CM_ SG_ 1313 STH_Motorvorwaermung "Info an der Motor, dass der Aufheizvorgang mit Motorvorwärmung erfolgt ist";
CM_ SG_ 1313 STH_Pumpen_Anf_extern "Anforderung der motorseitigen elektr. (externen) Wasserpumpe zur Kreislaufunterstützung im Standheizbetrieb";
CM_ SG_ 1313 STH_Servicemode "Rückmeldung, dass die Standheizung sich gerade im Diagnosemodus befindet, gestartet über Diagnosetester";
CM_ SG_ 1313 STH_SH_ZH "0 = Heizgerät ist Standheizung
1 = Heizgerät ist Zuheizer
Gerätekennung WZH oder ZH
";
CM_ SG_ 1313 STH_Start_folgt "Thema Start/Stop: Im Stop-Modus muß das KBT einen Wiederstart anfordern, da ein STH-Start notwendig ist.";
CM_ SG_ 1313 STH_Texte "Anforderung der unterschiedlichen Anzeigetexte im Mitteldisplay des Kombi.

0: Keine Anzeige
1: Kein Standheizungs- bzw Lueftungsbetrieb wegen Batteriemanagementeinschraenkung
2: Kein Standheizungs- bzw Lueftungsbetrieb wegen Kraftstoffmangels
3: Kei";
CM_ SG_ 1313 STH_Ventil_Status "Statusrückmeldung Ansteuerung 3/2 Wege-Ventil";
CM_ SG_ 1313 STH_Ventiloeffnungszeit "Die Standheizung sendet an den Motor die Information darüber wie lange das Magnetventil die Wasserkreisläufe von 'klein' aus 'gross' geschaltet hat. ";
CM_ SG_ 1313 STH_Waermeeintrag "Signal enthält die Brenndauer in 1min-Schritten, über welche die Standheizung gelaufen ist";
CM_ SG_ 1313 STH_war_aktiv "Bit beeinhaltet die Info, dass die Standheizung während der letzten halbe Stunde aktiv war.";
CM_ SG_ 1313 STH_Wassertemp "Kühlmitteltemperatur der Standheizung";
CM_ SG_ 1313 STH_Zusatzheizung "Kraftstoffzuheizer aktiv";
BA_DEF_REL_ BU_SG_REL_  "GenSigTimeoutTime" INT 0 65535;
BA_DEF_ BO_  "DiagRequest" ENUM "No", "Yes";
BA_DEF_ BO_  "DiagResponse" ENUM "No", "Yes";
BA_DEF_ BO_  "DiagState" ENUM "No", "Yes";
BA_DEF_ BO_  "GenMsgChkConstant" HEX 0 4095;
BA_DEF_ BO_  "GenMsgCycleTime" INT 0 65535;
BA_DEF_ BO_  "GenMsgCycleTimeFast" INT 0 65535;
BA_DEF_ BO_  "GenMsgDelayTime" INT 0 100000;
BA_DEF_ BO_  "GenMsgILSupport" ENUM "No", "Yes";
BA_DEF_ BO_  "GenMsgNrOfRepetition" INT 0 100;
BA_DEF_ BO_  "GenMsgPDUConstants" STRING;
BA_DEF_ BO_  "GenMsgSendType" ENUM "Cyclic", "not_used", "not_used", "not_used", "not_used", "not_used", "not_used", "IfActive", "NoMsgSendType";
BA_DEF_ BO_  "GenMsgStartDelayTime" INT 0 100000;
BA_DEF_ BO_  "NmMessage" ENUM "No", "Yes";
BA_DEF_ BO_  "NmhMessage" ENUM "No", "Yes";
BA_DEF_ BO_  "MsgType" ENUM "Application", "NM ", "NMH", "TP2.0", "ISO-TP ", "BAP", "EID", "KS", "XCP_PRE_CONFIGURED", "XCP_RUNTIME_CONFIGURED";
BA_DEF_ BO_  "VAGTP20_API" HEX 0 255;
BA_DEF_ BO_  "VAGTP20_DynConnection" ENUM "No", "Yes";
BA_DEF_ BO_  "VAGTP20_DynSetup" ENUM "No", "Yes";
BA_DEF_ BO_  "VAGTP20_StatConnection" ENUM "No", "Yes";
BA_DEF_ BO_  "CANFD_BRS" ENUM "0", "1";
BA_DEF_ BO_  "VFrameFormat" ENUM "StandardCAN", "ExtendedCAN", "reserved", "reserved", "reserved", "reserved", "reserved", "reserved", "reserved", "reserved", "reserved", "reserved", "reserved", "reserved", "StandardCAN_FD", "ExtendedCAN_FD";
BA_DEF_ SG_  "GenSigActiveRepetitions" INT -2147483648 2147483647;
BA_DEF_ SG_  "GenSigInactiveValue" INT -2147483648 2147483647;
BA_DEF_ SG_  "GenSigSendType" ENUM "Cyclic", "OnWrite", "OnWriteWithRepetition", "OnChange", "OnChangeWithRepetition", "IfActive", "IfActiveWithRepetition", "NoSigSendType", "OnChangeAndIfActive", "OnChangeAndIfActiveWithRepetition";
BA_DEF_ SG_  "GenSigStartValue" INT -2147483648 2147483647;
BA_DEF_ SG_  "NWM-WakeupAllowed" ENUM "No", "Yes";
BA_DEF_ SG_  "GenSigFuncType" ENUM "NoFunction", "MsgCounter", "CRC-8", "XOR", "XOR-2", "DatedBit", "SW-Kl15", "CHK", "Constant", "Protocol", "CRC-8-SAE_J1850", "CRC-32", "DataLength", "DataID", "MsgCounter16", "SOK-Signatur", "Cluster";
BA_DEF_ SG_  "GenSigSwitchedByIgnition" ENUM "No", "Yes";
BA_DEF_ SG_  "Fehlerwert" HEX 0 2147483647;
BA_DEF_ SG_  "GenSigMissingSourceValue" HEX 0 2147483647;
BA_DEF_DEF_REL_  "GenSigTimeoutTime" 0;
BA_DEF_DEF_  "DiagRequest" "No";
BA_DEF_DEF_  "DiagResponse" "No";
BA_DEF_DEF_  "DiagState" "No";
BA_DEF_DEF_  "GenMsgChkConstant" 0;
BA_DEF_DEF_  "GenMsgCycleTime" 0;
BA_DEF_DEF_  "GenMsgCycleTimeFast" 0;
BA_DEF_DEF_  "GenMsgDelayTime" 0;
BA_DEF_DEF_  "GenMsgILSupport" "No";
BA_DEF_DEF_  "GenMsgNrOfRepetition" 0;
BA_DEF_DEF_  "GenMsgPDUConstants" "";
BA_DEF_DEF_  "GenMsgSendType" "NoMsgSendType";
BA_DEF_DEF_  "GenMsgStartDelayTime" 0;
BA_DEF_DEF_  "NmMessage" "No";
BA_DEF_DEF_  "NmhMessage" "No";
BA_DEF_DEF_  "MsgType" "Application";
BA_DEF_DEF_  "VAGTP20_API" 0;
BA_DEF_DEF_  "VAGTP20_DynConnection" "No";
BA_DEF_DEF_  "VAGTP20_DynSetup" "No";
BA_DEF_DEF_  "VAGTP20_StatConnection" "No";
BA_DEF_DEF_  "CANFD_BRS" "1";
BA_DEF_DEF_  "VFrameFormat" "StandardCAN";
BA_DEF_DEF_  "GenSigActiveRepetitions" 0;
BA_DEF_DEF_  "GenSigInactiveValue" 0;
BA_DEF_DEF_  "GenSigSendType" "NoSigSendType";
BA_DEF_DEF_  "GenSigStartValue" 0;
BA_DEF_DEF_  "NWM-WakeupAllowed" "No";
BA_DEF_DEF_  "GenSigFuncType" "NoFunction";
BA_DEF_DEF_  "GenSigSwitchedByIgnition" "Yes";
BA_DEF_DEF_  "Fehlerwert" 0;
BA_DEF_DEF_  "GenSigMissingSourceValue" 0;
BA_ "GenMsgCycleTime" BO_ 1156 200;
BA_ "GenMsgILSupport" BO_ 1156 1;
BA_ "GenMsgSendType" BO_ 1156 0;
BA_ "VFrameFormat" BO_ 1156 14;
BA_ "GenMsgCycleTime" BO_ 1157 200;
BA_ "GenMsgILSupport" BO_ 1157 1;
BA_ "GenMsgSendType" BO_ 1157 0;
BA_ "VFrameFormat" BO_ 1157 14;
BA_ "GenMsgCycleTime" BO_ 1158 200;
BA_ "GenMsgILSupport" BO_ 1158 1;
BA_ "GenMsgSendType" BO_ 1158 0;
BA_ "VFrameFormat" BO_ 1158 14;
BA_ "GenMsgCycleTime" BO_ 2600468805 200;
BA_ "GenMsgCycleTimeFast" BO_ 2600468805 10;
BA_ "NmhMessage" BO_ 2600468805 1;
BA_ "MsgType" BO_ 2600468805 2;
BA_ "CANFD_BRS" BO_ 2600468805 0;
BA_ "VFrameFormat" BO_ 2600468805 1;
BA_ "GenMsgCycleTime" BO_ 2600468665 200;
BA_ "GenMsgCycleTimeFast" BO_ 2600468665 10;
BA_ "NmhMessage" BO_ 2600468665 1;
BA_ "MsgType" BO_ 2600468665 2;
BA_ "CANFD_BRS" BO_ 2600468665 0;
BA_ "VFrameFormat" BO_ 2600468665 1;
BA_ "GenMsgCycleTime" BO_ 2600468496 200;
BA_ "GenMsgCycleTimeFast" BO_ 2600468496 10;
BA_ "NmhMessage" BO_ 2600468496 1;
BA_ "MsgType" BO_ 2600468496 2;
BA_ "CANFD_BRS" BO_ 2600468496 0;
BA_ "VFrameFormat" BO_ 2600468496 1;
BA_ "GenMsgCycleTime" BO_ 2600468550 200;
BA_ "GenMsgCycleTimeFast" BO_ 2600468550 10;
BA_ "NmhMessage" BO_ 2600468550 1;
BA_ "MsgType" BO_ 2600468550 2;
BA_ "CANFD_BRS" BO_ 2600468550 0;
BA_ "VFrameFormat" BO_ 2600468550 1;
BA_ "GenMsgCycleTime" BO_ 2527679508 100;
BA_ "GenMsgILSupport" BO_ 2527679508 1;
BA_ "GenMsgPDUConstants" BO_ 2527679508 "0xa3,0xed,0x65,0xcf,0xc5,0x26,0x54,0x1a,0x99,0x3c,0x01,0x84,0xf4,0x46,0x9c,0x28";
BA_ "GenMsgSendType" BO_ 2527679508 0;
BA_ "VFrameFormat" BO_ 2527679508 15;
BA_ "GenMsgCycleTime" BO_ 527 50;
BA_ "GenMsgILSupport" BO_ 527 1;
BA_ "GenMsgPDUConstants" BO_ 527 "0xd4,0x22,0xad,0x3f,0x25,0xaa,0x62,0x5b,0xdc,0x73,0xed,0xc3,0x9a,0x14,0x2f,0x3e";
BA_ "GenMsgSendType" BO_ 527 0;
BA_ "VFrameFormat" BO_ 527 14;
BA_ "DiagRequest" BO_ 2621440668 1;
BA_ "MsgType" BO_ 2621440668 4;
BA_ "VFrameFormat" BO_ 2621440668 15;
BA_ "DiagResponse" BO_ 2621571740 1;
BA_ "MsgType" BO_ 2621571740 4;
BA_ "VFrameFormat" BO_ 2621571740 15;
BA_ "DiagRequest" BO_ 2621702725 1;
BA_ "MsgType" BO_ 2621702725 4;
BA_ "VFrameFormat" BO_ 2621702725 15;
BA_ "DiagResponse" BO_ 2621833797 1;
BA_ "MsgType" BO_ 2621833797 4;
BA_ "VFrameFormat" BO_ 2621833797 15;
BA_ "DiagRequest" BO_ 2621440697 1;
BA_ "MsgType" BO_ 2621440697 4;
BA_ "VFrameFormat" BO_ 2621440697 15;
BA_ "DiagResponse" BO_ 2621571769 1;
BA_ "MsgType" BO_ 2621571769 4;
BA_ "VFrameFormat" BO_ 2621571769 15;
BA_ "DiagRequest" BO_ 2621440577 1;
BA_ "MsgType" BO_ 2621440577 4;
BA_ "VFrameFormat" BO_ 2621440577 15;
BA_ "DiagResponse" BO_ 2621571649 1;
BA_ "MsgType" BO_ 2621571649 4;
BA_ "VFrameFormat" BO_ 2621571649 15;
BA_ "DiagState" BO_ 2621506048 1;
BA_ "MsgType" BO_ 2621506048 4;
BA_ "VFrameFormat" BO_ 2621506048 15;
BA_ "DiagRequest" BO_ 2621440635 1;
BA_ "MsgType" BO_ 2621440635 4;
BA_ "VFrameFormat" BO_ 2621440635 15;
BA_ "DiagResponse" BO_ 2621571707 1;
BA_ "MsgType" BO_ 2621571707 4;
BA_ "VFrameFormat" BO_ 2621571707 15;
BA_ "DiagRequest" BO_ 2621440582 1;
BA_ "MsgType" BO_ 2621440582 4;
BA_ "VFrameFormat" BO_ 2621440582 15;
BA_ "DiagResponse" BO_ 2621571654 1;
BA_ "MsgType" BO_ 2621571654 4;
BA_ "VFrameFormat" BO_ 2621571654 15;
BA_ "DiagRequest" BO_ 2621440580 1;
BA_ "MsgType" BO_ 2621440580 4;
BA_ "VFrameFormat" BO_ 2621440580 15;
BA_ "DiagResponse" BO_ 2621571652 1;
BA_ "MsgType" BO_ 2621571652 4;
BA_ "VFrameFormat" BO_ 2621571652 15;
BA_ "DiagRequest" BO_ 2621702683 1;
BA_ "MsgType" BO_ 2621702683 4;
BA_ "VFrameFormat" BO_ 2621702683 15;
BA_ "DiagResponse" BO_ 2621833755 1;
BA_ "MsgType" BO_ 2621833755 4;
BA_ "VFrameFormat" BO_ 2621833755 15;
BA_ "DiagRequest" BO_ 2549903569 1;
BA_ "MsgType" BO_ 2549903569 4;
BA_ "VFrameFormat" BO_ 2549903569 15;
BA_ "DiagResponse" BO_ 2550034641 1;
BA_ "MsgType" BO_ 2550034641 4;
BA_ "VFrameFormat" BO_ 2550034641 15;
BA_ "DiagRequest" BO_ 2549903573 1;
BA_ "MsgType" BO_ 2549903573 4;
BA_ "VFrameFormat" BO_ 2549903573 15;
BA_ "DiagResponse" BO_ 2550034645 1;
BA_ "MsgType" BO_ 2550034645 4;
BA_ "VFrameFormat" BO_ 2550034645 15;
BA_ "DiagRequest" BO_ 2549903577 1;
BA_ "MsgType" BO_ 2549903577 4;
BA_ "VFrameFormat" BO_ 2549903577 15;
BA_ "DiagResponse" BO_ 2550034649 1;
BA_ "MsgType" BO_ 2550034649 4;
BA_ "VFrameFormat" BO_ 2550034649 15;
BA_ "DiagRequest" BO_ 2549903601 1;
BA_ "MsgType" BO_ 2549903601 4;
BA_ "VFrameFormat" BO_ 2549903601 15;
BA_ "DiagResponse" BO_ 2550034673 1;
BA_ "MsgType" BO_ 2550034673 4;
BA_ "VFrameFormat" BO_ 2550034673 15;
BA_ "DiagState" BO_ 2564502513 1;
BA_ "MsgType" BO_ 2564502513 4;
BA_ "VFrameFormat" BO_ 2564502513 15;
BA_ "DiagRequest" BO_ 2564428273 1;
BA_ "MsgType" BO_ 2564428273 4;
BA_ "VFrameFormat" BO_ 2564428273 15;
BA_ "DiagResponse" BO_ 2564485393 1;
BA_ "MsgType" BO_ 2564485393 4;
BA_ "VFrameFormat" BO_ 2564485393 15;
BA_ "DiagRequest" BO_ 2564433393 1;
BA_ "MsgType" BO_ 2564433393 4;
BA_ "VFrameFormat" BO_ 2564433393 15;
BA_ "DiagResponse" BO_ 2564485413 1;
BA_ "MsgType" BO_ 2564485413 4;
BA_ "VFrameFormat" BO_ 2564485413 15;
BA_ "DiagRequest" BO_ 2564426737 1;
BA_ "MsgType" BO_ 2564426737 4;
BA_ "VFrameFormat" BO_ 2564426737 15;
BA_ "DiagResponse" BO_ 2564485387 1;
BA_ "MsgType" BO_ 2564485387 4;
BA_ "VFrameFormat" BO_ 2564485387 15;
BA_ "DiagRequest" BO_ 2564425201 1;
BA_ "MsgType" BO_ 2564425201 4;
BA_ "VFrameFormat" BO_ 2564425201 15;
BA_ "DiagResponse" BO_ 2564485381 1;
BA_ "MsgType" BO_ 2564485381 4;
BA_ "VFrameFormat" BO_ 2564485381 15;
BA_ "DiagRequest" BO_ 2564426481 1;
BA_ "MsgType" BO_ 2564426481 4;
BA_ "VFrameFormat" BO_ 2564426481 15;
BA_ "DiagResponse" BO_ 2564485386 1;
BA_ "MsgType" BO_ 2564485386 4;
BA_ "VFrameFormat" BO_ 2564485386 15;
BA_ "DiagRequest" BO_ 2564426993 1;
BA_ "MsgType" BO_ 2564426993 4;
BA_ "VFrameFormat" BO_ 2564426993 15;
BA_ "DiagResponse" BO_ 2564485388 1;
BA_ "MsgType" BO_ 2564485388 4;
BA_ "VFrameFormat" BO_ 2564485388 15;
BA_ "GenMsgCycleTime" BO_ 2463978776 100;
BA_ "GenMsgILSupport" BO_ 2463978776 1;
BA_ "GenMsgPDUConstants" BO_ 2463978776 "0xec,0x0e,0x83,0xa2,0x3c,0xbc,0xd7,0xc6,0x90,0x54,0xdb,0x6d,0x73,0x12,0xcf,0x40";
BA_ "GenMsgSendType" BO_ 2463978776 0;
BA_ "VFrameFormat" BO_ 2463978776 15;
BA_ "GenMsgCycleTime" BO_ 2589283656 500;
BA_ "GenMsgDelayTime" BO_ 2589283656 100;
BA_ "GenMsgILSupport" BO_ 2589283656 1;
BA_ "GenMsgSendType" BO_ 2589283656 0;
BA_ "VFrameFormat" BO_ 2589283656 15;
BA_ "GenMsgCycleTime" BO_ 2527679498 1000;
BA_ "GenMsgCycleTimeFast" BO_ 2527679498 200;
BA_ "GenMsgDelayTime" BO_ 2527679498 50;
BA_ "GenMsgILSupport" BO_ 2527679498 1;
BA_ "GenMsgNrOfRepetition" BO_ 2527679498 3;
BA_ "GenMsgSendType" BO_ 2527679498 0;
BA_ "VFrameFormat" BO_ 2527679498 15;
BA_ "GenMsgCycleTime" BO_ 1328 200;
BA_ "GenMsgILSupport" BO_ 1328 1;
BA_ "GenMsgSendType" BO_ 1328 0;
BA_ "VFrameFormat" BO_ 1328 14;
BA_ "GenMsgCycleTime" BO_ 1616 1000;
BA_ "GenMsgDelayTime" BO_ 1616 50;
BA_ "GenMsgILSupport" BO_ 1616 1;
BA_ "GenMsgSendType" BO_ 1616 0;
BA_ "VFrameFormat" BO_ 1616 14;
BA_ "GenMsgCycleTime" BO_ 1525 1000;
BA_ "GenMsgILSupport" BO_ 1525 1;
BA_ "GenMsgSendType" BO_ 1525 0;
BA_ "VFrameFormat" BO_ 1525 14;
BA_ "GenMsgCycleTime" BO_ 1440 200;
BA_ "GenMsgILSupport" BO_ 1440 1;
BA_ "GenMsgSendType" BO_ 1440 0;
BA_ "VFrameFormat" BO_ 1440 14;
BA_ "MsgType" BO_ 2584746776 4;
BA_ "VFrameFormat" BO_ 2584746776 15;
BA_ "MsgType" BO_ 2584877848 4;
BA_ "VFrameFormat" BO_ 2584877848 15;
BA_ "MsgType" BO_ 2630884158 4;
BA_ "VFrameFormat" BO_ 2630884158 15;
BA_ "MsgType" BO_ 2631015230 4;
BA_ "VFrameFormat" BO_ 2631015230 15;
BA_ "GenMsgCycleTime" BO_ 1504 500;
BA_ "GenMsgCycleTimeFast" BO_ 1504 100;
BA_ "GenMsgDelayTime" BO_ 1504 50;
BA_ "GenMsgILSupport" BO_ 1504 1;
BA_ "GenMsgNrOfRepetition" BO_ 1504 5;
BA_ "GenMsgSendType" BO_ 1504 0;
BA_ "VFrameFormat" BO_ 1504 14;
BA_ "GenMsgCycleTime" BO_ 980 1000;
BA_ "GenMsgCycleTimeFast" BO_ 980 100;
BA_ "GenMsgDelayTime" BO_ 980 50;
BA_ "GenMsgILSupport" BO_ 980 1;
BA_ "GenMsgNrOfRepetition" BO_ 980 5;
BA_ "GenMsgPDUConstants" BO_ 980 "0xc3,0x79,0xbf,0xdb,0xe9,0x11,0x46,0x86,0x69,0xb6,0x9b,0x29,0x15,0x9c,0x45,0x0d";
BA_ "GenMsgSendType" BO_ 980 0;
BA_ "VFrameFormat" BO_ 980 14;
BA_ "GenMsgDelayTime" BO_ 2464157766 100;
BA_ "GenMsgILSupport" BO_ 2464157766 1;
BA_ "VFrameFormat" BO_ 2464157766 15;
BA_ "GenMsgDelayTime" BO_ 2464292934 100;
BA_ "GenMsgILSupport" BO_ 2464292934 1;
BA_ "VFrameFormat" BO_ 2464292934 15;
BA_ "GenMsgDelayTime" BO_ 2589283756 100;
BA_ "GenMsgILSupport" BO_ 2589283756 1;
BA_ "VFrameFormat" BO_ 2589283756 15;
BA_ "GenMsgDelayTime" BO_ 2464153756 100;
BA_ "GenMsgILSupport" BO_ 2464153756 1;
BA_ "VFrameFormat" BO_ 2464153756 15;
BA_ "GenMsgDelayTime" BO_ 2464284828 100;
BA_ "GenMsgILSupport" BO_ 2464284828 1;
BA_ "VFrameFormat" BO_ 2464284828 15;
BA_ "GenMsgDelayTime" BO_ 2464153925 100;
BA_ "GenMsgILSupport" BO_ 2464153925 1;
BA_ "VFrameFormat" BO_ 2464153925 15;
BA_ "GenMsgDelayTime" BO_ 2464284997 100;
BA_ "GenMsgILSupport" BO_ 2464284997 1;
BA_ "VFrameFormat" BO_ 2464284997 15;
BA_ "GenMsgDelayTime" BO_ 2464153665 100;
BA_ "GenMsgILSupport" BO_ 2464153665 1;
BA_ "VFrameFormat" BO_ 2464153665 15;
BA_ "GenMsgDelayTime" BO_ 2464153785 100;
BA_ "GenMsgILSupport" BO_ 2464153785 1;
BA_ "VFrameFormat" BO_ 2464153785 15;
BA_ "GenMsgDelayTime" BO_ 2464284857 100;
BA_ "GenMsgILSupport" BO_ 2464284857 1;
BA_ "VFrameFormat" BO_ 2464284857 15;
BA_ "GenMsgDelayTime" BO_ 2464284737 100;
BA_ "GenMsgILSupport" BO_ 2464284737 1;
BA_ "VFrameFormat" BO_ 2464284737 15;
BA_ "GenMsgDelayTime" BO_ 2464153723 100;
BA_ "GenMsgILSupport" BO_ 2464153723 1;
BA_ "VFrameFormat" BO_ 2464153723 15;
BA_ "GenMsgDelayTime" BO_ 2464284795 100;
BA_ "GenMsgILSupport" BO_ 2464284795 1;
BA_ "VFrameFormat" BO_ 2464284795 15;
BA_ "GenMsgDelayTime" BO_ 2464153670 100;
BA_ "GenMsgILSupport" BO_ 2464153670 1;
BA_ "VFrameFormat" BO_ 2464153670 15;
BA_ "GenMsgDelayTime" BO_ 2464284742 100;
BA_ "VFrameFormat" BO_ 2464284742 15;
BA_ "GenMsgDelayTime" BO_ 2464288838 100;
BA_ "GenMsgILSupport" BO_ 2464288838 1;
BA_ "VFrameFormat" BO_ 2464288838 15;
BA_ "GenMsgDelayTime" BO_ 2464153668 100;
BA_ "GenMsgILSupport" BO_ 2464153668 1;
BA_ "VFrameFormat" BO_ 2464153668 15;
BA_ "GenMsgDelayTime" BO_ 2464284740 100;
BA_ "GenMsgILSupport" BO_ 2464284740 1;
BA_ "VFrameFormat" BO_ 2464284740 15;
BA_ "GenMsgDelayTime" BO_ 2464153883 100;
BA_ "GenMsgILSupport" BO_ 2464153883 1;
BA_ "VFrameFormat" BO_ 2464153883 15;
BA_ "GenMsgDelayTime" BO_ 2464284955 100;
BA_ "GenMsgILSupport" BO_ 2464284955 1;
BA_ "VFrameFormat" BO_ 2464284955 15;
BA_ "GenMsgCycleTime" BO_ 1467 500;
BA_ "GenMsgILSupport" BO_ 1467 1;
BA_ "GenMsgSendType" BO_ 1467 0;
BA_ "VFrameFormat" BO_ 1467 14;
BA_ "GenMsgCycleTime" BO_ 2527679739 500;
BA_ "GenMsgDelayTime" BO_ 2527679739 50;
BA_ "GenMsgILSupport" BO_ 2527679739 1;
BA_ "GenMsgSendType" BO_ 2527679739 0;
BA_ "VFrameFormat" BO_ 2527679739 15;
BA_ "GenMsgCycleTime" BO_ 1313 200;
BA_ "GenMsgILSupport" BO_ 1313 1;
BA_ "GenMsgSendType" BO_ 1313 0;
BA_ "VFrameFormat" BO_ 1313 14;
BA_ "GenSigSendType" SG_ 1156 ND_GDOP 0;
BA_ "GenSigStartValue" SG_ 1156 ND_GDOP 254;
BA_ "GenSigSwitchedByIgnition" SG_ 1156 ND_GDOP 0;
BA_ "Fehlerwert" SG_ 1156 ND_GDOP 1023;
BA_ "GenSigSendType" SG_ 1156 ND_HDOP 0;
BA_ "GenSigStartValue" SG_ 1156 ND_HDOP 1022;
BA_ "GenSigSwitchedByIgnition" SG_ 1156 ND_HDOP 0;
BA_ "Fehlerwert" SG_ 1156 ND_HDOP 1023;
BA_ "GenSigSendType" SG_ 1156 ND_Heading 0;
BA_ "GenSigStartValue" SG_ 1156 ND_Heading 1022;
BA_ "GenSigSwitchedByIgnition" SG_ 1156 ND_Heading 0;
BA_ "Fehlerwert" SG_ 1156 ND_Heading 4095;
BA_ "GenSigSendType" SG_ 1156 ND_Init 0;
BA_ "GenSigSwitchedByIgnition" SG_ 1156 ND_Init 0;
BA_ "GenSigSendType" SG_ 1156 ND_PDOP 0;
BA_ "GenSigStartValue" SG_ 1156 ND_PDOP 1022;
BA_ "GenSigSwitchedByIgnition" SG_ 1156 ND_PDOP 0;
BA_ "Fehlerwert" SG_ 1156 ND_PDOP 1023;
BA_ "GenSigSendType" SG_ 1156 ND_TDOP 0;
BA_ "GenSigStartValue" SG_ 1156 ND_TDOP 1022;
BA_ "GenSigSwitchedByIgnition" SG_ 1156 ND_TDOP 0;
BA_ "Fehlerwert" SG_ 1156 ND_TDOP 1023;
BA_ "GenSigSendType" SG_ 1156 ND_VDOP 0;
BA_ "GenSigStartValue" SG_ 1156 ND_VDOP 1022;
BA_ "GenSigSwitchedByIgnition" SG_ 1156 ND_VDOP 0;
BA_ "Fehlerwert" SG_ 1156 ND_VDOP 1023;
BA_ "GenSigSendType" SG_ 1157 ND_SatInUse 0;
BA_ "GenSigStartValue" SG_ 1157 ND_SatInUse 30;
BA_ "GenSigSwitchedByIgnition" SG_ 1157 ND_SatInUse 0;
BA_ "Fehlerwert" SG_ 1157 ND_SatInUse 31;
BA_ "GenSigSendType" SG_ 1157 ND_SatInView 0;
BA_ "GenSigStartValue" SG_ 1157 ND_SatInView 30;
BA_ "GenSigSwitchedByIgnition" SG_ 1157 ND_SatInView 0;
BA_ "Fehlerwert" SG_ 1157 ND_SatInView 31;
BA_ "GenSigSendType" SG_ 1157 ND_UTC 0;
BA_ "GenSigStartValue" SG_ 1157 ND_UTC 1022;
BA_ "GenSigSwitchedByIgnition" SG_ 1157 ND_UTC 0;
BA_ "GenSigSendType" SG_ 1157 NP_Altitude 0;
BA_ "GenSigStartValue" SG_ 1157 NP_Altitude 4094;
BA_ "GenSigSwitchedByIgnition" SG_ 1157 NP_Altitude 0;
BA_ "Fehlerwert" SG_ 1157 NP_Altitude 4095;
BA_ "GenSigSendType" SG_ 1157 POS_Guete_horizontal 0;
BA_ "GenSigStartValue" SG_ 1157 POS_Guete_horizontal 126;
BA_ "GenSigSwitchedByIgnition" SG_ 1157 POS_Guete_horizontal 0;
BA_ "Fehlerwert" SG_ 1157 POS_Guete_horizontal 127;
BA_ "GenSigSendType" SG_ 1157 POS_Guete_horizontal_verfuegbar 0;
BA_ "GenSigSwitchedByIgnition" SG_ 1157 POS_Guete_horizontal_verfuegbar 0;
BA_ "GenSigSendType" SG_ 1158 NP_Fix 0;
BA_ "GenSigSwitchedByIgnition" SG_ 1158 NP_Fix 0;
BA_ "GenSigSendType" SG_ 1158 NP_LatDegree 0;
BA_ "GenSigStartValue" SG_ 1158 NP_LatDegree 134217726;
BA_ "GenSigSwitchedByIgnition" SG_ 1158 NP_LatDegree 0;
BA_ "Fehlerwert" SG_ 1158 NP_LatDegree 134217727;
BA_ "GenSigSendType" SG_ 1158 NP_LatDirection 0;
BA_ "GenSigStartValue" SG_ 1158 NP_LatDirection 1;
BA_ "GenSigSwitchedByIgnition" SG_ 1158 NP_LatDirection 0;
BA_ "GenSigSendType" SG_ 1158 NP_LongDegree 0;
BA_ "GenSigStartValue" SG_ 1158 NP_LongDegree 268435454;
BA_ "GenSigSwitchedByIgnition" SG_ 1158 NP_LongDegree 0;
BA_ "Fehlerwert" SG_ 1158 NP_LongDegree 268435455;
BA_ "GenSigSendType" SG_ 1158 NP_LongDirection 0;
BA_ "GenSigStartValue" SG_ 1158 NP_LongDirection 1;
BA_ "GenSigSwitchedByIgnition" SG_ 1158 NP_LongDirection 0;
BA_ "GenSigSendType" SG_ 1158 NP_Sat 0;
BA_ "GenSigStartValue" SG_ 1158 NP_Sat 30;
BA_ "GenSigSwitchedByIgnition" SG_ 1158 NP_Sat 0;
BA_ "Fehlerwert" SG_ 1158 NP_Sat 31;
BA_ "GenSigFuncType" SG_ 2600468805 NM_BMS_NV_CAB_V14 16;
BA_ "GenSigSwitchedByIgnition" SG_ 2600468805 NM_BMS_NV_CAB_V14 0;
BA_ "GenSigSwitchedByIgnition" SG_ 2600468805 NM_BMS_NV_Car_Wakeup 0;
BA_ "GenSigSwitchedByIgnition" SG_ 2600468805 NM_BMS_NV_CBV_AWB 0;
BA_ "GenSigSwitchedByIgnition" SG_ 2600468805 NM_BMS_NV_CBV_CRI 0;
BA_ "GenSigSwitchedByIgnition" SG_ 2600468805 NM_BMS_NV_NM_aktiv_Diagnose 0;
BA_ "GenSigSwitchedByIgnition" SG_ 2600468805 NM_BMS_NV_NM_aktiv_KL15 0;
BA_ "GenSigSwitchedByIgnition" SG_ 2600468805 NM_BMS_NV_NM_aktiv_Tmin 0;
BA_ "GenSigSwitchedByIgnition" SG_ 2600468805 NM_BMS_NV_NM_State 0;
BA_ "GenSigSwitchedByIgnition" SG_ 2600468805 NM_BMS_NV_UDS_CC 0;
BA_ "GenSigFuncType" SG_ 2600468665 NM_DCDC_CAB_V14 16;
BA_ "GenSigSwitchedByIgnition" SG_ 2600468665 NM_DCDC_CAB_V14 0;
BA_ "GenSigSwitchedByIgnition" SG_ 2600468665 NM_DCDC_NV_Car_Wakeup 0;
BA_ "GenSigSwitchedByIgnition" SG_ 2600468665 NM_DCDC_NV_CBV_AWB 0;
BA_ "GenSigSwitchedByIgnition" SG_ 2600468665 NM_DCDC_NV_CBV_CRI 0;
BA_ "GenSigSwitchedByIgnition" SG_ 2600468665 NM_DCDC_NV_NM_State 0;
BA_ "GenSigFuncType" SG_ 2600468496 NM_Gateway_CAB_V14 16;
BA_ "GenSigSwitchedByIgnition" SG_ 2600468496 NM_Gateway_CAB_V14 0;
BA_ "GenSigSwitchedByIgnition" SG_ 2600468496 NM_Gateway_Car_Wakeup 0;
BA_ "GenSigSwitchedByIgnition" SG_ 2600468496 NM_Gateway_CBV_AWB 0;
BA_ "GenSigSwitchedByIgnition" SG_ 2600468496 NM_Gateway_CBV_CRI 0;
BA_ "GenSigSwitchedByIgnition" SG_ 2600468496 NM_Gateway_NM_aktiv_Buskopplung 0;
BA_ "GenSigSwitchedByIgnition" SG_ 2600468496 NM_Gateway_NM_aktiv_CWU 0;
BA_ "GenSigSwitchedByIgnition" SG_ 2600468496 NM_Gateway_NM_aktiv_Diagnose 0;
BA_ "GenSigSwitchedByIgnition" SG_ 2600468496 NM_Gateway_NM_aktiv_EM 0;
BA_ "GenSigSwitchedByIgnition" SG_ 2600468496 NM_Gateway_NM_aktiv_FC 0;
BA_ "GenSigSwitchedByIgnition" SG_ 2600468496 NM_Gateway_NM_aktiv_KL15 0;
BA_ "GenSigSwitchedByIgnition" SG_ 2600468496 NM_Gateway_NM_aktiv_Tmin 0;
BA_ "GenSigSwitchedByIgnition" SG_ 2600468496 NM_Gateway_NM_State 0;
BA_ "GenSigSwitchedByIgnition" SG_ 2600468496 NM_Gateway_UDS_CC 0;
BA_ "GenSigFuncType" SG_ 2600468550 NM_Klima_CAB_V14 16;
BA_ "GenSigSwitchedByIgnition" SG_ 2600468550 NM_Klima_CAB_V14 0;
BA_ "GenSigSwitchedByIgnition" SG_ 2600468550 NM_Klima_Car_Wakeup 0;
BA_ "GenSigSwitchedByIgnition" SG_ 2600468550 NM_Klima_CBV_AWB 0;
BA_ "GenSigFuncType" SG_ 2600468550 NM_Klima_CBV_CRI 8;
BA_ "GenSigSwitchedByIgnition" SG_ 2600468550 NM_Klima_CBV_CRI 0;
BA_ "GenSigSwitchedByIgnition" SG_ 2600468550 NM_Klima_NM_aktiv_Diagnose 0;
BA_ "GenSigSwitchedByIgnition" SG_ 2600468550 NM_Klima_NM_aktiv_KL15 0;
BA_ "GenSigSwitchedByIgnition" SG_ 2600468550 NM_Klima_NM_aktiv_STH 0;
BA_ "GenSigSwitchedByIgnition" SG_ 2600468550 NM_Klima_NM_aktiv_Tmin 0;
BA_ "GenSigSwitchedByIgnition" SG_ 2600468550 NM_Klima_NM_State 0;
BA_ "GenSigSwitchedByIgnition" SG_ 2600468550 NM_Klima_UDS_CC 0;
BA_ "GenSigSendType" SG_ 2527679508 NVEM_06_BZ 0;
BA_ "GenSigFuncType" SG_ 2527679508 NVEM_06_BZ 1;
BA_ "GenSigSwitchedByIgnition" SG_ 2527679508 NVEM_06_BZ 0;
BA_ "GenSigSendType" SG_ 2527679508 NVEM_06_CRC 0;
BA_ "GenSigFuncType" SG_ 2527679508 NVEM_06_CRC 2;
BA_ "GenSigSwitchedByIgnition" SG_ 2527679508 NVEM_06_CRC 0;
BA_ "GenSigSendType" SG_ 2527679508 NVEM_Bordnetzdiagnose 0;
BA_ "GenSigSwitchedByIgnition" SG_ 2527679508 NVEM_Bordnetzdiagnose 0;
BA_ "GenSigSendType" SG_ 2527679508 NVEM_Energie_Klima_Vorgabe 0;
BA_ "GenSigStartValue" SG_ 2527679508 NVEM_Energie_Klima_Vorgabe 254;
BA_ "GenSigSwitchedByIgnition" SG_ 2527679508 NVEM_Energie_Klima_Vorgabe 0;
BA_ "Fehlerwert" SG_ 2527679508 NVEM_Energie_Klima_Vorgabe 255;
BA_ "GenSigSendType" SG_ 2527679508 NVEM_Max_Rampenzeit 0;
BA_ "GenSigStartValue" SG_ 2527679508 NVEM_Max_Rampenzeit 6;
BA_ "GenSigSwitchedByIgnition" SG_ 2527679508 NVEM_Max_Rampenzeit 0;
BA_ "GenSigSendType" SG_ 2527679508 NVEM_Max_Spannung 0;
BA_ "GenSigStartValue" SG_ 2527679508 NVEM_Max_Spannung 126;
BA_ "GenSigSwitchedByIgnition" SG_ 2527679508 NVEM_Max_Spannung 0;
BA_ "Fehlerwert" SG_ 2527679508 NVEM_Max_Spannung 127;
BA_ "GenSigSendType" SG_ 2527679508 NVEM_Min_Spannung 0;
BA_ "GenSigStartValue" SG_ 2527679508 NVEM_Min_Spannung 126;
BA_ "GenSigSwitchedByIgnition" SG_ 2527679508 NVEM_Min_Spannung 0;
BA_ "Fehlerwert" SG_ 2527679508 NVEM_Min_Spannung 127;
BA_ "GenSigSendType" SG_ 2527679508 NVEM_Min_Spannung_Start 0;
BA_ "GenSigStartValue" SG_ 2527679508 NVEM_Min_Spannung_Start 62;
BA_ "GenSigSwitchedByIgnition" SG_ 2527679508 NVEM_Min_Spannung_Start 0;
BA_ "Fehlerwert" SG_ 2527679508 NVEM_Min_Spannung_Start 63;
BA_ "GenSigSendType" SG_ 2527679508 NVEM_MV_DC_uMinLV 0;
BA_ "GenSigStartValue" SG_ 2527679508 NVEM_MV_DC_uMinLV 126;
BA_ "GenSigSwitchedByIgnition" SG_ 2527679508 NVEM_MV_DC_uMinLV 0;
BA_ "Fehlerwert" SG_ 2527679508 NVEM_MV_DC_uMinLV 127;
BA_ "GenSigSendType" SG_ 2527679508 NVEM_MV_DC_uSollLV 0;
BA_ "GenSigStartValue" SG_ 2527679508 NVEM_MV_DC_uSollLV 126;
BA_ "GenSigSwitchedByIgnition" SG_ 2527679508 NVEM_MV_DC_uSollLV 0;
BA_ "Fehlerwert" SG_ 2527679508 NVEM_MV_DC_uSollLV 127;
BA_ "GenSigSendType" SG_ 527 NVEM_10_BZ 0;
BA_ "GenSigFuncType" SG_ 527 NVEM_10_BZ 1;
BA_ "GenSigSwitchedByIgnition" SG_ 527 NVEM_10_BZ 0;
BA_ "GenSigSendType" SG_ 527 NVEM_10_CRC 0;
BA_ "GenSigFuncType" SG_ 527 NVEM_10_CRC 2;
BA_ "GenSigSwitchedByIgnition" SG_ 527 NVEM_10_CRC 0;
BA_ "GenSigSendType" SG_ 527 NVEM_DC_iSoll_NV 0;
BA_ "GenSigStartValue" SG_ 527 NVEM_DC_iSoll_NV 254;
BA_ "GenSigSwitchedByIgnition" SG_ 527 NVEM_DC_iSoll_NV 0;
BA_ "Fehlerwert" SG_ 527 NVEM_DC_iSoll_NV 255;
BA_ "GenSigSendType" SG_ 527 NVEM_DC_uSoll_NV 0;
BA_ "GenSigStartValue" SG_ 527 NVEM_DC_uSoll_NV 116;
BA_ "GenSigSwitchedByIgnition" SG_ 527 NVEM_DC_uSoll_NV 0;
BA_ "Fehlerwert" SG_ 527 NVEM_DC_uSoll_NV 255;
BA_ "GenSigSendType" SG_ 527 NVEM_IBatt 0;
BA_ "GenSigStartValue" SG_ 527 NVEM_IBatt 127;
BA_ "GenSigSwitchedByIgnition" SG_ 527 NVEM_IBatt 0;
BA_ "Fehlerwert" SG_ 527 NVEM_IBatt 255;
BA_ "GenSigSendType" SG_ 527 NVEM_MOD_Budget 0;
BA_ "GenSigStartValue" SG_ 527 NVEM_MOD_Budget 15;
BA_ "GenSigSwitchedByIgnition" SG_ 527 NVEM_MOD_Budget 0;
BA_ "GenSigSendType" SG_ 527 NVEM_MOD_Freigabe 0;
BA_ "GenSigStartValue" SG_ 527 NVEM_MOD_Freigabe 3;
BA_ "GenSigSwitchedByIgnition" SG_ 527 NVEM_MOD_Freigabe 0;
BA_ "GenSigSendType" SG_ 527 NVEM_MV_DC_iSoll_NV 0;
BA_ "GenSigStartValue" SG_ 527 NVEM_MV_DC_iSoll_NV 254;
BA_ "GenSigSwitchedByIgnition" SG_ 527 NVEM_MV_DC_iSoll_NV 0;
BA_ "Fehlerwert" SG_ 527 NVEM_MV_DC_iSoll_NV 255;
BA_ "GenSigSendType" SG_ 2621440668 OBDC_BMS_48V_Req_FD_Data 3;
BA_ "GenSigFuncType" SG_ 2621440668 OBDC_BMS_48V_Req_FD_Data 9;
BA_ "GenSigSwitchedByIgnition" SG_ 2621440668 OBDC_BMS_48V_Req_FD_Data 0;
BA_ "GenSigSendType" SG_ 2621571740 OBDC_BMS_48V_Resp_FD_Data 3;
BA_ "GenSigFuncType" SG_ 2621571740 OBDC_BMS_48V_Resp_FD_Data 9;
BA_ "GenSigSwitchedByIgnition" SG_ 2621571740 OBDC_BMS_48V_Resp_FD_Data 0;
BA_ "GenSigSendType" SG_ 2621702725 OBDC_BMS_NV_Req_FD_Data 3;
BA_ "GenSigFuncType" SG_ 2621702725 OBDC_BMS_NV_Req_FD_Data 9;
BA_ "GenSigSwitchedByIgnition" SG_ 2621702725 OBDC_BMS_NV_Req_FD_Data 0;
BA_ "GenSigSendType" SG_ 2621833797 OBDC_BMS_NV_Resp_FD_Data 3;
BA_ "GenSigFuncType" SG_ 2621833797 OBDC_BMS_NV_Resp_FD_Data 9;
BA_ "GenSigSwitchedByIgnition" SG_ 2621833797 OBDC_BMS_NV_Resp_FD_Data 0;
BA_ "GenSigSendType" SG_ 2621440697 OBDC_DCDC_NV_Req_FD_Data 3;
BA_ "GenSigFuncType" SG_ 2621440697 OBDC_DCDC_NV_Req_FD_Data 9;
BA_ "GenSigSwitchedByIgnition" SG_ 2621440697 OBDC_DCDC_NV_Req_FD_Data 0;
BA_ "GenSigSendType" SG_ 2621571769 OBDC_DCDC_NV_Resp_FD_Data 3;
BA_ "GenSigFuncType" SG_ 2621571769 OBDC_DCDC_NV_Resp_FD_Data 9;
BA_ "GenSigSwitchedByIgnition" SG_ 2621571769 OBDC_DCDC_NV_Resp_FD_Data 0;
BA_ "GenSigSendType" SG_ 2621440577 OBDC_DCDC_Req_FD_Data 3;
BA_ "GenSigFuncType" SG_ 2621440577 OBDC_DCDC_Req_FD_Data 9;
BA_ "GenSigSwitchedByIgnition" SG_ 2621440577 OBDC_DCDC_Req_FD_Data 0;
BA_ "GenSigSendType" SG_ 2621571649 OBDC_DCDC_Resp_FD_Data 3;
BA_ "GenSigFuncType" SG_ 2621571649 OBDC_DCDC_Resp_FD_Data 9;
BA_ "GenSigSwitchedByIgnition" SG_ 2621571649 OBDC_DCDC_Resp_FD_Data 0;
BA_ "GenSigSendType" SG_ 2621506048 OBDC_Funktion_Req_All_FD_Data 3;
BA_ "GenSigFuncType" SG_ 2621506048 OBDC_Funktion_Req_All_FD_Data 9;
BA_ "GenSigSwitchedByIgnition" SG_ 2621506048 OBDC_Funktion_Req_All_FD_Data 0;
BA_ "GenSigSendType" SG_ 2621440635 OBDC_Hybrid_01_Req_FD_Data 3;
BA_ "GenSigFuncType" SG_ 2621440635 OBDC_Hybrid_01_Req_FD_Data 9;
BA_ "GenSigSwitchedByIgnition" SG_ 2621440635 OBDC_Hybrid_01_Req_FD_Data 0;
BA_ "GenSigSendType" SG_ 2621571707 OBDC_Hybrid_01_Resp_FD_Data 3;
BA_ "GenSigFuncType" SG_ 2621571707 OBDC_Hybrid_01_Resp_FD_Data 9;
BA_ "GenSigSwitchedByIgnition" SG_ 2621571707 OBDC_Hybrid_01_Resp_FD_Data 0;
BA_ "GenSigSendType" SG_ 2621440582 OBDC_Klima_Req_FD_Data 3;
BA_ "GenSigFuncType" SG_ 2621440582 OBDC_Klima_Req_FD_Data 9;
BA_ "GenSigSwitchedByIgnition" SG_ 2621440582 OBDC_Klima_Req_FD_Data 0;
BA_ "GenSigSendType" SG_ 2621571654 OBDC_Klima_Resp_FD_Data 3;
BA_ "GenSigFuncType" SG_ 2621571654 OBDC_Klima_Resp_FD_Data 9;
BA_ "GenSigSwitchedByIgnition" SG_ 2621571654 OBDC_Klima_Resp_FD_Data 0;
BA_ "GenSigSendType" SG_ 2621440580 OBDC_Ladegeraet_Req_FD_Data 3;
BA_ "GenSigFuncType" SG_ 2621440580 OBDC_Ladegeraet_Req_FD_Data 9;
BA_ "GenSigSwitchedByIgnition" SG_ 2621440580 OBDC_Ladegeraet_Req_FD_Data 0;
BA_ "GenSigSendType" SG_ 2621571652 OBDC_Ladegeraet_Resp_FD_Data 3;
BA_ "GenSigFuncType" SG_ 2621571652 OBDC_Ladegeraet_Resp_FD_Data 9;
BA_ "GenSigSwitchedByIgnition" SG_ 2621571652 OBDC_Ladegeraet_Resp_FD_Data 0;
BA_ "GenSigSendType" SG_ 2621702683 OBDC_SACID_1_Req_FD_Data 3;
BA_ "GenSigFuncType" SG_ 2621702683 OBDC_SACID_1_Req_FD_Data 9;
BA_ "GenSigSwitchedByIgnition" SG_ 2621702683 OBDC_SACID_1_Req_FD_Data 0;
BA_ "GenSigSendType" SG_ 2621833755 OBDC_SACID_1_Resp_FD_Data 3;
BA_ "GenSigFuncType" SG_ 2621833755 OBDC_SACID_1_Resp_FD_Data 9;
BA_ "GenSigSwitchedByIgnition" SG_ 2621833755 OBDC_SACID_1_Resp_FD_Data 0;
BA_ "GenSigSendType" SG_ 2549903569 OBDC_SSN_CMC_01_Req_Data 3;
BA_ "GenSigFuncType" SG_ 2549903569 OBDC_SSN_CMC_01_Req_Data 9;
BA_ "GenSigSwitchedByIgnition" SG_ 2549903569 OBDC_SSN_CMC_01_Req_Data 0;
BA_ "GenSigSendType" SG_ 2550034641 OBDC_SSN_CMC_01_Resp_Data 3;
BA_ "GenSigFuncType" SG_ 2550034641 OBDC_SSN_CMC_01_Resp_Data 9;
BA_ "GenSigSwitchedByIgnition" SG_ 2550034641 OBDC_SSN_CMC_01_Resp_Data 0;
BA_ "GenSigSendType" SG_ 2549903573 OBDC_SSN_CMC_05_Req_Data 3;
BA_ "GenSigFuncType" SG_ 2549903573 OBDC_SSN_CMC_05_Req_Data 9;
BA_ "GenSigSwitchedByIgnition" SG_ 2549903573 OBDC_SSN_CMC_05_Req_Data 0;
BA_ "GenSigSendType" SG_ 2550034645 OBDC_SSN_CMC_05_Resp_Data 3;
BA_ "GenSigFuncType" SG_ 2550034645 OBDC_SSN_CMC_05_Resp_Data 9;
BA_ "GenSigSwitchedByIgnition" SG_ 2550034645 OBDC_SSN_CMC_05_Resp_Data 0;
BA_ "GenSigSendType" SG_ 2549903577 OBDC_SSN_CMC_09_Req_Data 3;
BA_ "GenSigFuncType" SG_ 2549903577 OBDC_SSN_CMC_09_Req_Data 9;
BA_ "GenSigSwitchedByIgnition" SG_ 2549903577 OBDC_SSN_CMC_09_Req_Data 0;
BA_ "GenSigSendType" SG_ 2550034649 OBDC_SSN_CMC_09_Resp_Data 3;
BA_ "GenSigFuncType" SG_ 2550034649 OBDC_SSN_CMC_09_Resp_Data 9;
BA_ "GenSigSwitchedByIgnition" SG_ 2550034649 OBDC_SSN_CMC_09_Resp_Data 0;
BA_ "GenSigSendType" SG_ 2549903601 OBDC_SSN_CMC_13_Req_Data 3;
BA_ "GenSigFuncType" SG_ 2549903601 OBDC_SSN_CMC_13_Req_Data 9;
BA_ "GenSigSwitchedByIgnition" SG_ 2549903601 OBDC_SSN_CMC_13_Req_Data 0;
BA_ "GenSigSendType" SG_ 2550034673 OBDC_SSN_CMC_13_Resp_Data 3;
BA_ "GenSigFuncType" SG_ 2550034673 OBDC_SSN_CMC_13_Resp_Data 9;
BA_ "GenSigSwitchedByIgnition" SG_ 2550034673 OBDC_SSN_CMC_13_Resp_Data 0;
BA_ "GenSigSendType" SG_ 2564502513 OBDx_allOBD_Req_Data 3;
BA_ "GenSigFuncType" SG_ 2564502513 OBDx_allOBD_Req_Data 9;
BA_ "GenSigSwitchedByIgnition" SG_ 2564502513 OBDx_allOBD_Req_Data 0;
BA_ "GenSigSendType" SG_ 2564428273 OBDx_BMS_48V_Req_Data 3;
BA_ "GenSigFuncType" SG_ 2564428273 OBDx_BMS_48V_Req_Data 9;
BA_ "GenSigSwitchedByIgnition" SG_ 2564428273 OBDx_BMS_48V_Req_Data 0;
BA_ "GenSigSendType" SG_ 2564485393 OBDx_BMS_48V_Resp_Data 3;
BA_ "GenSigFuncType" SG_ 2564485393 OBDx_BMS_48V_Resp_Data 9;
BA_ "GenSigSwitchedByIgnition" SG_ 2564485393 OBDx_BMS_48V_Resp_Data 0;
BA_ "GenSigSendType" SG_ 2564433393 OBDx_BMS_NV_Req_Data 3;
BA_ "GenSigFuncType" SG_ 2564433393 OBDx_BMS_NV_Req_Data 9;
BA_ "GenSigSwitchedByIgnition" SG_ 2564433393 OBDx_BMS_NV_Req_Data 0;
BA_ "GenSigSendType" SG_ 2564485413 OBDx_BMS_NV_Resp_Data 3;
BA_ "GenSigFuncType" SG_ 2564485413 OBDx_BMS_NV_Resp_Data 9;
BA_ "GenSigSwitchedByIgnition" SG_ 2564485413 OBDx_BMS_NV_Resp_Data 0;
BA_ "GenSigSendType" SG_ 2564426737 OBDx_DCDC_NV_Req_Data 3;
BA_ "GenSigFuncType" SG_ 2564426737 OBDx_DCDC_NV_Req_Data 9;
BA_ "GenSigSwitchedByIgnition" SG_ 2564426737 OBDx_DCDC_NV_Req_Data 0;
BA_ "GenSigSendType" SG_ 2564485387 OBDx_DCDC_NV_Resp_Data 3;
BA_ "GenSigFuncType" SG_ 2564485387 OBDx_DCDC_NV_Resp_Data 9;
BA_ "GenSigSwitchedByIgnition" SG_ 2564485387 OBDx_DCDC_NV_Resp_Data 0;
BA_ "GenSigSendType" SG_ 2564425201 OBDx_Hybrid_01_Req_Data 3;
BA_ "GenSigFuncType" SG_ 2564425201 OBDx_Hybrid_01_Req_Data 9;
BA_ "GenSigSwitchedByIgnition" SG_ 2564425201 OBDx_Hybrid_01_Req_Data 0;
BA_ "GenSigSendType" SG_ 2564485381 OBDx_Hybrid_01_Resp_Data 3;
BA_ "GenSigFuncType" SG_ 2564485381 OBDx_Hybrid_01_Resp_Data 9;
BA_ "GenSigSwitchedByIgnition" SG_ 2564485381 OBDx_Hybrid_01_Resp_Data 0;
BA_ "GenSigSendType" SG_ 2564426481 OBDx_Klima_Req_Data 3;
BA_ "GenSigFuncType" SG_ 2564426481 OBDx_Klima_Req_Data 9;
BA_ "GenSigSwitchedByIgnition" SG_ 2564426481 OBDx_Klima_Req_Data 0;
BA_ "GenSigSendType" SG_ 2564485386 OBDx_Klima_Resp_Data 3;
BA_ "GenSigFuncType" SG_ 2564485386 OBDx_Klima_Resp_Data 9;
BA_ "GenSigSwitchedByIgnition" SG_ 2564485386 OBDx_Klima_Resp_Data 0;
BA_ "GenSigSendType" SG_ 2564426993 OBDx_Ladegeraet_Req_Data 3;
BA_ "GenSigFuncType" SG_ 2564426993 OBDx_Ladegeraet_Req_Data 9;
BA_ "GenSigSwitchedByIgnition" SG_ 2564426993 OBDx_Ladegeraet_Req_Data 0;
BA_ "GenSigSendType" SG_ 2564485388 OBDx_Ladegeraet_Resp_Data 3;
BA_ "GenSigFuncType" SG_ 2564485388 OBDx_Ladegeraet_Resp_Data 9;
BA_ "GenSigSwitchedByIgnition" SG_ 2564485388 OBDx_Ladegeraet_Resp_Data 0;
BA_ "GenSigSendType" SG_ 2463978776 HVLE_AnzahlVerwendeterPhasen 0;
BA_ "GenSigSwitchedByIgnition" SG_ 2463978776 HVLE_AnzahlVerwendeterPhasen 0;
BA_ "Fehlerwert" SG_ 2463978776 HVLE_AnzahlVerwendeterPhasen 3;
BA_ "GenSigSendType" SG_ 2463978776 HVLE_AsymmetrischLadenMoeglich 0;
BA_ "GenSigSwitchedByIgnition" SG_ 2463978776 HVLE_AsymmetrischLadenMoeglich 0;
BA_ "GenSigSendType" SG_ 2463978776 HVLE_Derating_Temperatur 0;
BA_ "GenSigSwitchedByIgnition" SG_ 2463978776 HVLE_Derating_Temperatur 0;
BA_ "GenSigSendType" SG_ 2463978776 HVLE_Energiemenge_Laden 0;
BA_ "GenSigSwitchedByIgnition" SG_ 2463978776 HVLE_Energiemenge_Laden 0;
BA_ "GenSigSendType" SG_ 2463978776 HVLE_I_istAC_Netz_L1 0;
BA_ "GenSigStartValue" SG_ 2463978776 HVLE_I_istAC_Netz_L1 510;
BA_ "GenSigSwitchedByIgnition" SG_ 2463978776 HVLE_I_istAC_Netz_L1 0;
BA_ "Fehlerwert" SG_ 2463978776 HVLE_I_istAC_Netz_L1 511;
BA_ "GenSigSendType" SG_ 2463978776 HVLE_I_istAC_Netz_L2 0;
BA_ "GenSigStartValue" SG_ 2463978776 HVLE_I_istAC_Netz_L2 510;
BA_ "GenSigSwitchedByIgnition" SG_ 2463978776 HVLE_I_istAC_Netz_L2 0;
BA_ "Fehlerwert" SG_ 2463978776 HVLE_I_istAC_Netz_L2 511;
BA_ "GenSigSendType" SG_ 2463978776 HVLE_I_istAC_Netz_L3 0;
BA_ "GenSigStartValue" SG_ 2463978776 HVLE_I_istAC_Netz_L3 510;
BA_ "GenSigSwitchedByIgnition" SG_ 2463978776 HVLE_I_istAC_Netz_L3 0;
BA_ "Fehlerwert" SG_ 2463978776 HVLE_I_istAC_Netz_L3 511;
BA_ "GenSigSendType" SG_ 2463978776 HVLE_Ist_Wirkungsgrad 0;
BA_ "GenSigStartValue" SG_ 2463978776 HVLE_Ist_Wirkungsgrad 126;
BA_ "GenSigSwitchedByIgnition" SG_ 2463978776 HVLE_Ist_Wirkungsgrad 0;
BA_ "Fehlerwert" SG_ 2463978776 HVLE_Ist_Wirkungsgrad 127;
BA_ "GenSigSendType" SG_ 2463978776 HVLE_IstSpannung_HV 0;
BA_ "GenSigStartValue" SG_ 2463978776 HVLE_IstSpannung_HV 1022;
BA_ "GenSigSwitchedByIgnition" SG_ 2463978776 HVLE_IstSpannung_HV 0;
BA_ "Fehlerwert" SG_ 2463978776 HVLE_IstSpannung_HV 1023;
BA_ "GenSigSendType" SG_ 2463978776 HVLE_Netzfrequenz_EVU 0;
BA_ "GenSigStartValue" SG_ 2463978776 HVLE_Netzfrequenz_EVU 510;
BA_ "GenSigSwitchedByIgnition" SG_ 2463978776 HVLE_Netzfrequenz_EVU 0;
BA_ "Fehlerwert" SG_ 2463978776 HVLE_Netzfrequenz_EVU 511;
BA_ "GenSigSendType" SG_ 2463978776 HVLE_Netzmodus 0;
BA_ "GenSigSwitchedByIgnition" SG_ 2463978776 HVLE_Netzmodus 0;
BA_ "Fehlerwert" SG_ 2463978776 HVLE_Netzmodus 15;
BA_ "GenSigSendType" SG_ 2463978776 HVLE_OBG_AC_maxSpannung 0;
BA_ "GenSigStartValue" SG_ 2463978776 HVLE_OBG_AC_maxSpannung 1022;
BA_ "GenSigSwitchedByIgnition" SG_ 2463978776 HVLE_OBG_AC_maxSpannung 0;
BA_ "Fehlerwert" SG_ 2463978776 HVLE_OBG_AC_maxSpannung 1023;
BA_ "GenSigSendType" SG_ 2463978776 HVLE_OBG_AC_maxStrom 0;
BA_ "GenSigStartValue" SG_ 2463978776 HVLE_OBG_AC_maxStrom 1022;
BA_ "GenSigSwitchedByIgnition" SG_ 2463978776 HVLE_OBG_AC_maxStrom 0;
BA_ "Fehlerwert" SG_ 2463978776 HVLE_OBG_AC_maxStrom 1023;
BA_ "GenSigSendType" SG_ 2463978776 HVLE_OBG_ACDC_IstLeistung 0;
BA_ "GenSigStartValue" SG_ 2463978776 HVLE_OBG_ACDC_IstLeistung 2046;
BA_ "GenSigSwitchedByIgnition" SG_ 2463978776 HVLE_OBG_ACDC_IstLeistung 0;
BA_ "Fehlerwert" SG_ 2463978776 HVLE_OBG_ACDC_IstLeistung 2047;
BA_ "GenSigSendType" SG_ 2463978776 HVLE_OBG_ACDC_MaxLeistung 0;
BA_ "GenSigStartValue" SG_ 2463978776 HVLE_OBG_ACDC_MaxLeistung 2046;
BA_ "GenSigSwitchedByIgnition" SG_ 2463978776 HVLE_OBG_ACDC_MaxLeistung 0;
BA_ "Fehlerwert" SG_ 2463978776 HVLE_OBG_ACDC_MaxLeistung 2047;
BA_ "GenSigSendType" SG_ 2463978776 HVLE_OBG_DC_IstStrom 0;
BA_ "GenSigStartValue" SG_ 2463978776 HVLE_OBG_DC_IstStrom 2046;
BA_ "GenSigSwitchedByIgnition" SG_ 2463978776 HVLE_OBG_DC_IstStrom 0;
BA_ "Fehlerwert" SG_ 2463978776 HVLE_OBG_DC_IstStrom 2047;
BA_ "GenSigSendType" SG_ 2463978776 HVLE_OBG_DC_MaxStrom 0;
BA_ "GenSigStartValue" SG_ 2463978776 HVLE_OBG_DC_MaxStrom 2046;
BA_ "GenSigSwitchedByIgnition" SG_ 2463978776 HVLE_OBG_DC_MaxStrom 0;
BA_ "Fehlerwert" SG_ 2463978776 HVLE_OBG_DC_MaxStrom 2047;
BA_ "GenSigSendType" SG_ 2463978776 HVLE_OBG_Fehlerstatus 0;
BA_ "GenSigSwitchedByIgnition" SG_ 2463978776 HVLE_OBG_Fehlerstatus 0;
BA_ "GenSigSendType" SG_ 2463978776 HVLE_OBG_Fehlerstrom 0;
BA_ "GenSigSwitchedByIgnition" SG_ 2463978776 HVLE_OBG_Fehlerstrom 0;
BA_ "GenSigSendType" SG_ 2463978776 HVLE_OBG_IstModus 0;
BA_ "GenSigStartValue" SG_ 2463978776 HVLE_OBG_IstModus 6;
BA_ "GenSigSwitchedByIgnition" SG_ 2463978776 HVLE_OBG_IstModus 0;
BA_ "Fehlerwert" SG_ 2463978776 HVLE_OBG_IstModus 7;
BA_ "GenSigSendType" SG_ 2463978776 HVLE_OBG_Kuehltemperatur 0;
BA_ "GenSigStartValue" SG_ 2463978776 HVLE_OBG_Kuehltemperatur 254;
BA_ "GenSigSwitchedByIgnition" SG_ 2463978776 HVLE_OBG_Kuehltemperatur 0;
BA_ "Fehlerwert" SG_ 2463978776 HVLE_OBG_Kuehltemperatur 255;
BA_ "GenSigSendType" SG_ 2463978776 HVLE_OBG_Status_EoHVL 0;
BA_ "GenSigSwitchedByIgnition" SG_ 2463978776 HVLE_OBG_Status_EoHVL 0;
BA_ "Fehlerwert" SG_ 2463978776 HVLE_OBG_Status_EoHVL 3;
BA_ "GenSigSendType" SG_ 2463978776 HVLE_OBG_Status_Spgfreiheit 0;
BA_ "GenSigSwitchedByIgnition" SG_ 2463978776 HVLE_OBG_Status_Spgfreiheit 0;
BA_ "Fehlerwert" SG_ 2463978776 HVLE_OBG_Status_Spgfreiheit 3;
BA_ "GenSigSendType" SG_ 2463978776 HVLE_OBG_Typ_verbaut 0;
BA_ "GenSigStartValue" SG_ 2463978776 HVLE_OBG_Typ_verbaut 7;
BA_ "GenSigSwitchedByIgnition" SG_ 2463978776 HVLE_OBG_Typ_verbaut 0;
BA_ "GenSigSendType" SG_ 2463978776 HVLE_OBG_Warnzustand 0;
BA_ "GenSigSwitchedByIgnition" SG_ 2463978776 HVLE_OBG_Warnzustand 0;
BA_ "GenSigSendType" SG_ 2463978776 HVLE_PE_Monitor 0;
BA_ "GenSigSwitchedByIgnition" SG_ 2463978776 HVLE_PE_Monitor 0;
BA_ "Fehlerwert" SG_ 2463978776 HVLE_PE_Monitor 7;
BA_ "GenSigSendType" SG_ 2463978776 HVLE_U_istAC_Netz_L1 0;
BA_ "GenSigStartValue" SG_ 2463978776 HVLE_U_istAC_Netz_L1 510;
BA_ "GenSigSwitchedByIgnition" SG_ 2463978776 HVLE_U_istAC_Netz_L1 0;
BA_ "Fehlerwert" SG_ 2463978776 HVLE_U_istAC_Netz_L1 511;
BA_ "GenSigSendType" SG_ 2463978776 HVLE_U_istAC_Netz_L2 0;
BA_ "GenSigStartValue" SG_ 2463978776 HVLE_U_istAC_Netz_L2 510;
BA_ "GenSigSwitchedByIgnition" SG_ 2463978776 HVLE_U_istAC_Netz_L2 0;
BA_ "Fehlerwert" SG_ 2463978776 HVLE_U_istAC_Netz_L2 511;
BA_ "GenSigSendType" SG_ 2463978776 HVLE_U_istAC_Netz_L3 0;
BA_ "GenSigStartValue" SG_ 2463978776 HVLE_U_istAC_Netz_L3 510;
BA_ "GenSigSwitchedByIgnition" SG_ 2463978776 HVLE_U_istAC_Netz_L3 0;
BA_ "Fehlerwert" SG_ 2463978776 HVLE_U_istAC_Netz_L3 511;
BA_ "GenSigSendType" SG_ 2463978776 OBG_01_BZ 0;
BA_ "GenSigFuncType" SG_ 2463978776 OBG_01_BZ 1;
BA_ "GenSigSwitchedByIgnition" SG_ 2463978776 OBG_01_BZ 0;
BA_ "GenSigSendType" SG_ 2463978776 OBG_01_CRC 0;
BA_ "GenSigFuncType" SG_ 2463978776 OBG_01_CRC 2;
BA_ "GenSigSwitchedByIgnition" SG_ 2463978776 OBG_01_CRC 0;
BA_ "GenSigSendType" SG_ 2463978776 SOK_OBG_01_Signatur 0;
BA_ "GenSigFuncType" SG_ 2463978776 SOK_OBG_01_Signatur 15;
BA_ "GenSigSwitchedByIgnition" SG_ 2463978776 SOK_OBG_01_Signatur 0;
BA_ "GenSigSendType" SG_ 2589283656 ORU_Status 3;
BA_ "GenSigSwitchedByIgnition" SG_ 2589283656 ORU_Status 0;
BA_ "GenSigSendType" SG_ 2589283656 ORU_Warnung 3;
BA_ "GenSigSwitchedByIgnition" SG_ 2589283656 ORU_Warnung 0;
BA_ "GenSigSendType" SG_ 2527679498 IAA_Active_User_ID 4;
BA_ "GenSigSwitchedByIgnition" SG_ 2527679498 IAA_Active_User_ID 0;
BA_ "GenSigSendType" SG_ 2527679498 IAA_Identified_User_ID 4;
BA_ "GenSigSwitchedByIgnition" SG_ 2527679498 IAA_Identified_User_ID 0;
BA_ "GenSigSendType" SG_ 2527679498 IAA_PSO_wake_up 4;
BA_ "GenSigSwitchedByIgnition" SG_ 2527679498 IAA_PSO_wake_up 0;
BA_ "GenSigSendType" SG_ 2527679498 Perso_Aktiv 4;
BA_ "GenSigSwitchedByIgnition" SG_ 2527679498 Perso_Aktiv 0;
BA_ "GenSigSendType" SG_ 2527679498 Perso_Bedienstelle 4;
BA_ "GenSigSwitchedByIgnition" SG_ 2527679498 Perso_Bedienstelle 0;
BA_ "GenSigSendType" SG_ 2527679498 Perso_Fahrernummer 4;
BA_ "GenSigSwitchedByIgnition" SG_ 2527679498 Perso_Fahrernummer 0;
BA_ "GenSigSendType" SG_ 2527679498 Perso_Freigabe_Verstellung 4;
BA_ "GenSigSwitchedByIgnition" SG_ 2527679498 Perso_Freigabe_Verstellung 0;
BA_ "GenSigSendType" SG_ 2527679498 Perso_Kontonummer 4;
BA_ "GenSigSwitchedByIgnition" SG_ 2527679498 Perso_Kontonummer 0;
BA_ "GenSigSendType" SG_ 2527679498 Perso_Schreibschutz 4;
BA_ "GenSigSwitchedByIgnition" SG_ 2527679498 Perso_Schreibschutz 0;
BA_ "GenSigSendType" SG_ 2527679498 Perso_Status 1;
BA_ "GenSigSwitchedByIgnition" SG_ 2527679498 Perso_Status 0;
BA_ "GenSigSendType" SG_ 2527679498 Perso_Steuerung 4;
BA_ "GenSigSwitchedByIgnition" SG_ 2527679498 Perso_Steuerung 0;
BA_ "GenSigSendType" SG_ 2527679498 Perso_Steuerungsparameter 4;
BA_ "GenSigSwitchedByIgnition" SG_ 2527679498 Perso_Steuerungsparameter 0;
BA_ "GenSigSendType" SG_ 1328 PTC_Aktiv 0;
BA_ "GenSigSwitchedByIgnition" SG_ 1328 PTC_Aktiv 0;
BA_ "GenSigSendType" SG_ 1328 PTC_Fehlerstatus 0;
BA_ "GenSigSwitchedByIgnition" SG_ 1328 PTC_Fehlerstatus 0;
BA_ "GenSigSendType" SG_ 1328 PTC_I_ist 0;
BA_ "GenSigStartValue" SG_ 1328 PTC_I_ist 254;
BA_ "GenSigSwitchedByIgnition" SG_ 1328 PTC_I_ist 0;
BA_ "GenSigSendType" SG_ 1328 PTC_Nenn_Strom 0;
BA_ "GenSigSwitchedByIgnition" SG_ 1328 PTC_Nenn_Strom 0;
BA_ "GenSigSendType" SG_ 1328 PTC_P_ist 0;
BA_ "GenSigStartValue" SG_ 1328 PTC_P_ist 254;
BA_ "GenSigSwitchedByIgnition" SG_ 1328 PTC_P_ist 0;
BA_ "GenSigSendType" SG_ 1328 PTCs_01_alt 0;
BA_ "GenSigStartValue" SG_ 1328 PTCs_01_alt 1;
BA_ "GenSigFuncType" SG_ 1328 PTCs_01_alt 5;
BA_ "GenSigSwitchedByIgnition" SG_ 1328 PTCs_01_alt 0;
BA_ "GenSigSendType" SG_ 1616 RA_AM_Tuning 3;
BA_ "GenSigSwitchedByIgnition" SG_ 1616 RA_AM_Tuning 0;
BA_ "GenSigSendType" SG_ 1616 RA_Frequency 3;
BA_ "GenSigSwitchedByIgnition" SG_ 1616 RA_Frequency 0;
BA_ "GenSigSendType" SG_ 1616 RA_Frequency_unit 3;
BA_ "GenSigSwitchedByIgnition" SG_ 1616 RA_Frequency_unit 0;
BA_ "GenSigSendType" SG_ 1616 RA_PowerAmpOn 3;
BA_ "GenSigSwitchedByIgnition" SG_ 1616 RA_PowerAmpOn 0;
BA_ "GenSigSendType" SG_ 1616 RA_Radio_Error_Flag 3;
BA_ "GenSigSwitchedByIgnition" SG_ 1616 RA_Radio_Error_Flag 0;
BA_ "GenSigSendType" SG_ 1616 RA_Radio_mute 3;
BA_ "GenSigSwitchedByIgnition" SG_ 1616 RA_Radio_mute 0;
BA_ "GenSigSendType" SG_ 1616 RA_Radio_on 3;
BA_ "GenSigSwitchedByIgnition" SG_ 1616 RA_Radio_on 0;
BA_ "GenSigSendType" SG_ 1616 RA_Radio_Surround 3;
BA_ "GenSigSwitchedByIgnition" SG_ 1616 RA_Radio_Surround 0;
BA_ "GenSigSendType" SG_ 1616 RA_VNC_OFF 3;
BA_ "GenSigSwitchedByIgnition" SG_ 1616 RA_VNC_OFF 0;
BA_ "GenSigSendType" SG_ 1525 RW_Gesamt_Reichweite 0;
BA_ "GenSigStartValue" SG_ 1525 RW_Gesamt_Reichweite 2046;
BA_ "GenSigSwitchedByIgnition" SG_ 1525 RW_Gesamt_Reichweite 0;
BA_ "Fehlerwert" SG_ 1525 RW_Gesamt_Reichweite 2047;
BA_ "GenSigSendType" SG_ 1525 RW_Gesamt_Reichweite_Max_Anzeige 0;
BA_ "GenSigStartValue" SG_ 1525 RW_Gesamt_Reichweite_Max_Anzeige 2046;
BA_ "GenSigSwitchedByIgnition" SG_ 1525 RW_Gesamt_Reichweite_Max_Anzeige 0;
BA_ "Fehlerwert" SG_ 1525 RW_Gesamt_Reichweite_Max_Anzeige 2047;
BA_ "GenSigSendType" SG_ 1525 RW_Prim_Reichweitenv_Einheit 0;
BA_ "GenSigStartValue" SG_ 1525 RW_Prim_Reichweitenv_Einheit 3;
BA_ "GenSigSwitchedByIgnition" SG_ 1525 RW_Prim_Reichweitenv_Einheit 0;
BA_ "GenSigSendType" SG_ 1525 RW_Prim_Reichweitenverbrauch 0;
BA_ "GenSigStartValue" SG_ 1525 RW_Prim_Reichweitenverbrauch 2047;
BA_ "GenSigSwitchedByIgnition" SG_ 1525 RW_Prim_Reichweitenverbrauch 0;
BA_ "GenSigSendType" SG_ 1525 RW_Primaer_Reichweite 0;
BA_ "GenSigStartValue" SG_ 1525 RW_Primaer_Reichweite 2046;
BA_ "GenSigSwitchedByIgnition" SG_ 1525 RW_Primaer_Reichweite 0;
BA_ "Fehlerwert" SG_ 1525 RW_Primaer_Reichweite 2047;
BA_ "GenSigSendType" SG_ 1525 RW_Reservewarnung_2_aktiv 0;
BA_ "GenSigSwitchedByIgnition" SG_ 1525 RW_Reservewarnung_2_aktiv 0;
BA_ "GenSigSendType" SG_ 1525 RW_RWDS_Lastprofil 0;
BA_ "GenSigStartValue" SG_ 1525 RW_RWDS_Lastprofil 2046;
BA_ "GenSigSwitchedByIgnition" SG_ 1525 RW_RWDS_Lastprofil 0;
BA_ "Fehlerwert" SG_ 1525 RW_RWDS_Lastprofil 2047;
BA_ "GenSigSendType" SG_ 1440 LS_defekt 0;
BA_ "GenSigSwitchedByIgnition" SG_ 1440 LS_defekt 0;
BA_ "GenSigSendType" SG_ 1440 LS_Helligkeit_FW 0;
BA_ "GenSigStartValue" SG_ 1440 LS_Helligkeit_FW 1022;
BA_ "GenSigSwitchedByIgnition" SG_ 1440 LS_Helligkeit_FW 0;
BA_ "Fehlerwert" SG_ 1440 LS_Helligkeit_FW 1023;
BA_ "GenSigMissingSourceValue" SG_ 1440 LS_Helligkeit_FW 1023;
BA_ "GenSigSendType" SG_ 1440 LS_Helligkeit_IR 0;
BA_ "GenSigStartValue" SG_ 1440 LS_Helligkeit_IR 254;
BA_ "GenSigSwitchedByIgnition" SG_ 1440 LS_Helligkeit_IR 0;
BA_ "Fehlerwert" SG_ 1440 LS_Helligkeit_IR 255;
BA_ "GenSigMissingSourceValue" SG_ 1440 LS_Helligkeit_IR 255;
BA_ "GenSigSendType" SG_ 1440 LS_Verbau 0;
BA_ "GenSigSwitchedByIgnition" SG_ 1440 LS_Verbau 0;
BA_ "GenSigSendType" SG_ 1440 RLS_Vorfeldhelligkeit_Boost 0;
BA_ "GenSigStartValue" SG_ 1440 RLS_Vorfeldhelligkeit_Boost 15;
BA_ "GenSigSwitchedByIgnition" SG_ 1440 RLS_Vorfeldhelligkeit_Boost 0;
BA_ "GenSigSendType" SG_ 1440 RS_defekt 0;
BA_ "GenSigSwitchedByIgnition" SG_ 1440 RS_defekt 0;
BA_ "GenSigSendType" SG_ 1440 RS_Regenmenge 0;
BA_ "GenSigStartValue" SG_ 1440 RS_Regenmenge 14;
BA_ "GenSigSwitchedByIgnition" SG_ 1440 RS_Regenmenge 0;
BA_ "Fehlerwert" SG_ 1440 RS_Regenmenge 15;
BA_ "GenSigMissingSourceValue" SG_ 1440 RS_Regenmenge 15;
BA_ "GenSigSendType" SG_ 1440 RS_Schwall 0;
BA_ "GenSigSwitchedByIgnition" SG_ 1440 RS_Schwall 0;
BA_ "GenSigSendType" SG_ 1440 RS_Verbau 0;
BA_ "GenSigSwitchedByIgnition" SG_ 1440 RS_Verbau 0;
BA_ "GenSigSendType" SG_ 1440 RS_Verglasung_schliessen 0;
BA_ "GenSigSwitchedByIgnition" SG_ 1440 RS_Verglasung_schliessen 0;
BA_ "GenSigSendType" SG_ 1440 RS_Wischergeschwindigkeit 0;
BA_ "GenSigSwitchedByIgnition" SG_ 1440 RS_Wischergeschwindigkeit 0;
BA_ "GenSigSendType" SG_ 1440 SLS_Helligkeit_IR 0;
BA_ "GenSigStartValue" SG_ 1440 SLS_Helligkeit_IR 254;
BA_ "GenSigSwitchedByIgnition" SG_ 1440 SLS_Helligkeit_IR 0;
BA_ "Fehlerwert" SG_ 1440 SLS_Helligkeit_IR 255;
BA_ "GenSigSendType" SG_ 2584746776 SACID_1_AuthTime_Req_Data 3;
BA_ "GenSigFuncType" SG_ 2584746776 SACID_1_AuthTime_Req_Data 9;
BA_ "GenSigSwitchedByIgnition" SG_ 2584746776 SACID_1_AuthTime_Req_Data 0;
BA_ "GenSigSendType" SG_ 2584877848 SACID_1_AuthTime_Resp_Data 3;
BA_ "GenSigFuncType" SG_ 2584877848 SACID_1_AuthTime_Resp_Data 9;
BA_ "GenSigSwitchedByIgnition" SG_ 2584877848 SACID_1_AuthTime_Resp_Data 0;
BA_ "GenSigSendType" SG_ 2630884158 SACID_1_PLC_Req_FD_Data 3;
BA_ "GenSigFuncType" SG_ 2630884158 SACID_1_PLC_Req_FD_Data 9;
BA_ "GenSigSwitchedByIgnition" SG_ 2630884158 SACID_1_PLC_Req_FD_Data 0;
BA_ "GenSigSendType" SG_ 2631015230 SACID_1_PLC_Resp_FD_Data 3;
BA_ "GenSigFuncType" SG_ 2631015230 SACID_1_PLC_Resp_FD_Data 9;
BA_ "GenSigSwitchedByIgnition" SG_ 2631015230 SACID_1_PLC_Resp_FD_Data 0;
BA_ "GenSigSendType" SG_ 1504 MD1_Lage 0;
BA_ "GenSigSwitchedByIgnition" SG_ 1504 MD1_Lage 0;
BA_ "GenSigSendType" SG_ 1504 MD1_Position 0;
BA_ "GenSigStartValue" SG_ 1504 MD1_Position 126;
BA_ "GenSigSwitchedByIgnition" SG_ 1504 MD1_Position 0;
BA_ "GenSigSendType" SG_ 1504 MD3_Lage 0;
BA_ "GenSigSwitchedByIgnition" SG_ 1504 MD3_Lage 0;
BA_ "GenSigSendType" SG_ 1504 MD3_Position 0;
BA_ "GenSigSwitchedByIgnition" SG_ 1504 MD3_Position 0;
BA_ "GenSigSendType" SG_ 1504 MRollo_Lage 0;
BA_ "GenSigSwitchedByIgnition" SG_ 1504 MRollo_Lage 0;
BA_ "GenSigSendType" SG_ 1504 MRollo_Position 0;
BA_ "GenSigStartValue" SG_ 1504 MRollo_Position 126;
BA_ "GenSigSwitchedByIgnition" SG_ 1504 MRollo_Position 0;
BA_ "GenSigSendType" SG_ 1504 Rollo_normiert 3;
BA_ "GenSigSwitchedByIgnition" SG_ 1504 Rollo_normiert 0;
BA_ "GenSigSendType" SG_ 1504 Rollo_Thermoschutz 3;
BA_ "GenSigSwitchedByIgnition" SG_ 1504 Rollo_Thermoschutz 0;
BA_ "GenSigSendType" SG_ 1504 Rollo_UEKB_aktiv 3;
BA_ "GenSigSwitchedByIgnition" SG_ 1504 Rollo_UEKB_aktiv 0;
BA_ "GenSigSendType" SG_ 1504 SAD_Anf_ESC_Zuschaltung 3;
BA_ "GenSigSwitchedByIgnition" SG_ 1504 SAD_Anf_ESC_Zuschaltung 0;
BA_ "GenSigSendType" SG_ 1504 SAD_normiert 3;
BA_ "GenSigSwitchedByIgnition" SG_ 1504 SAD_normiert 0;
BA_ "GenSigSendType" SG_ 1504 SAD_Taster_Deckel_hi 4;
BA_ "GenSigSwitchedByIgnition" SG_ 1504 SAD_Taster_Deckel_hi 0;
BA_ "GenSigSendType" SG_ 1504 SAD_Taster_Deckel_vo 4;
BA_ "GenSigSwitchedByIgnition" SG_ 1504 SAD_Taster_Deckel_vo 0;
BA_ "GenSigSendType" SG_ 1504 SAD_Taster_Rollo_hi 4;
BA_ "GenSigSwitchedByIgnition" SG_ 1504 SAD_Taster_Rollo_hi 0;
BA_ "GenSigSendType" SG_ 1504 SAD_Taster_Rollo_vo 4;
BA_ "GenSigSwitchedByIgnition" SG_ 1504 SAD_Taster_Rollo_vo 0;
BA_ "GenSigSendType" SG_ 1504 SAD_Thermoschutz 3;
BA_ "GenSigSwitchedByIgnition" SG_ 1504 SAD_Thermoschutz 0;
BA_ "GenSigSendType" SG_ 1504 SAD_UEKB_aktiv 3;
BA_ "GenSigSwitchedByIgnition" SG_ 1504 SAD_UEKB_aktiv 0;
BA_ "GenSigSendType" SG_ 980 BH_Blinker_Fehler 4;
BA_ "GenSigSwitchedByIgnition" SG_ 980 BH_Blinker_Fehler 0;
BA_ "Fehlerwert" SG_ 980 BH_Blinker_Fehler 1;
BA_ "GenSigSendType" SG_ 980 BH_Blinker_li 4;
BA_ "GenSigSwitchedByIgnition" SG_ 980 BH_Blinker_li 0;
BA_ "GenSigSendType" SG_ 980 BH_Blinker_re 4;
BA_ "GenSigSwitchedByIgnition" SG_ 980 BH_Blinker_re 0;
BA_ "GenSigSendType" SG_ 980 BH_Fernlicht 3;
BA_ "GenSigSwitchedByIgnition" SG_ 980 BH_Fernlicht 0;
BA_ "GenSigSendType" SG_ 980 BH_Lichthupe 4;
BA_ "GenSigSwitchedByIgnition" SG_ 980 BH_Lichthupe 0;
BA_ "GenSigSendType" SG_ 980 FAS_Taster 3;
BA_ "GenSigSwitchedByIgnition" SG_ 980 FAS_Taster 0;
BA_ "GenSigSendType" SG_ 980 FAS_Taster_Fehler 3;
BA_ "GenSigSwitchedByIgnition" SG_ 980 FAS_Taster_Fehler 0;
BA_ "Fehlerwert" SG_ 980 FAS_Taster_Fehler 1;
BA_ "GenSigSendType" SG_ 980 LRH_aktiv 3;
BA_ "GenSigSwitchedByIgnition" SG_ 980 LRH_aktiv 0;
BA_ "GenSigSendType" SG_ 980 LRH_On_Off 3;
BA_ "GenSigSwitchedByIgnition" SG_ 980 LRH_On_Off 0;
BA_ "Fehlerwert" SG_ 980 LRH_On_Off 3;
BA_ "GenSigSendType" SG_ 980 LSS_Tastencode 3;
BA_ "GenSigSwitchedByIgnition" SG_ 980 LSS_Tastencode 0;
BA_ "GenSigSendType" SG_ 980 SMLS_01_BZ 0;
BA_ "GenSigFuncType" SG_ 980 SMLS_01_BZ 1;
BA_ "GenSigSwitchedByIgnition" SG_ 980 SMLS_01_BZ 0;
BA_ "GenSigSendType" SG_ 980 SMLS_01_CRC 0;
BA_ "GenSigFuncType" SG_ 980 SMLS_01_CRC 2;
BA_ "GenSigSwitchedByIgnition" SG_ 980 SMLS_01_CRC 0;
BA_ "GenSigSendType" SG_ 980 SMLS_Hupe 4;
BA_ "GenSigSwitchedByIgnition" SG_ 980 SMLS_Hupe 0;
BA_ "GenSigSendType" SG_ 980 SMLS_P_verriegelt 4;
BA_ "GenSigSwitchedByIgnition" SG_ 980 SMLS_P_verriegelt 0;
BA_ "Fehlerwert" SG_ 980 SMLS_P_verriegelt 3;
BA_ "GenSigSendType" SG_ 980 SMLS_P_verriegelt_plausibel 3;
BA_ "GenSigSwitchedByIgnition" SG_ 980 SMLS_P_verriegelt_plausibel 0;
BA_ "GenSigSendType" SG_ 980 SMLS_PTT 4;
BA_ "GenSigSendType" SG_ 980 WH_Frontwaschen 3;
BA_ "GenSigSwitchedByIgnition" SG_ 980 WH_Frontwaschen 0;
BA_ "GenSigSendType" SG_ 980 WH_Heckintervall 3;
BA_ "GenSigSwitchedByIgnition" SG_ 980 WH_Heckintervall 0;
BA_ "GenSigSendType" SG_ 980 WH_Heckwaschen 3;
BA_ "GenSigSwitchedByIgnition" SG_ 980 WH_Heckwaschen 0;
BA_ "GenSigSendType" SG_ 980 WH_Intervall 3;
BA_ "GenSigSwitchedByIgnition" SG_ 980 WH_Intervall 0;
BA_ "GenSigSendType" SG_ 980 WH_Intervallstufen 3;
BA_ "GenSigSwitchedByIgnition" SG_ 980 WH_Intervallstufen 0;
BA_ "Fehlerwert" SG_ 980 WH_Intervallstufen 15;
BA_ "GenSigMissingSourceValue" SG_ 980 WH_Intervallstufen 15;
BA_ "GenSigSendType" SG_ 980 WH_SRA 3;
BA_ "GenSigSwitchedByIgnition" SG_ 980 WH_SRA 0;
BA_ "GenSigSendType" SG_ 980 WH_Tipwischen 4;
BA_ "GenSigSwitchedByIgnition" SG_ 980 WH_Tipwischen 0;
BA_ "GenSigSendType" SG_ 980 WH_Tipwischen_lang 4;
BA_ "GenSigSwitchedByIgnition" SG_ 980 WH_Tipwischen_lang 0;
BA_ "GenSigSendType" SG_ 980 WH_Wischer_Fehler 3;
BA_ "GenSigSwitchedByIgnition" SG_ 980 WH_Wischer_Fehler 0;
BA_ "Fehlerwert" SG_ 980 WH_Wischer_Fehler 1;
BA_ "GenSigSendType" SG_ 980 WH_WischerStufe1 3;
BA_ "GenSigSwitchedByIgnition" SG_ 980 WH_WischerStufe1 0;
BA_ "GenSigSendType" SG_ 980 WH_WischerStufe2 3;
BA_ "GenSigSwitchedByIgnition" SG_ 980 WH_WischerStufe2 0;
BA_ "GenSigSendType" SG_ 2464157766 SOK_FoD_Klima_Req_Challenge 3;
BA_ "GenSigSwitchedByIgnition" SG_ 2464157766 SOK_FoD_Klima_Req_Challenge 0;
BA_ "GenSigSendType" SG_ 2464292934 SOK_FoD_Klima_Resp_Challenge 3;
BA_ "GenSigSwitchedByIgnition" SG_ 2464292934 SOK_FoD_Klima_Resp_Challenge 0;
BA_ "GenSigSendType" SG_ 2589283756 SOK_ungeschuetzte_Zeit 3;
BA_ "GenSigSwitchedByIgnition" SG_ 2589283756 SOK_ungeschuetzte_Zeit 0;
BA_ "GenSigSendType" SG_ 2464153756 SOK_Zeit_BMS_48V_Challenge 3;
BA_ "GenSigSwitchedByIgnition" SG_ 2464153756 SOK_Zeit_BMS_48V_Challenge 0;
BA_ "GenSigSendType" SG_ 2464284828 SOK_Zeit_BMS_48V_Signatur 3;
BA_ "GenSigFuncType" SG_ 2464284828 SOK_Zeit_BMS_48V_Signatur 15;
BA_ "GenSigSwitchedByIgnition" SG_ 2464284828 SOK_Zeit_BMS_48V_Signatur 0;
BA_ "GenSigSendType" SG_ 2464284828 SOK_Zeit_BMS_48V_Zeit 3;
BA_ "GenSigSwitchedByIgnition" SG_ 2464284828 SOK_Zeit_BMS_48V_Zeit 0;
BA_ "GenSigSendType" SG_ 2464153925 SOK_Zeit_BMS_NV_Challenge 3;
BA_ "GenSigSwitchedByIgnition" SG_ 2464153925 SOK_Zeit_BMS_NV_Challenge 0;
BA_ "GenSigSendType" SG_ 2464284997 SOK_Zeit_BMS_NV_Signatur 3;
BA_ "GenSigFuncType" SG_ 2464284997 SOK_Zeit_BMS_NV_Signatur 15;
BA_ "GenSigSwitchedByIgnition" SG_ 2464284997 SOK_Zeit_BMS_NV_Signatur 0;
BA_ "GenSigSendType" SG_ 2464284997 SOK_Zeit_BMS_NV_Zeit 3;
BA_ "GenSigSwitchedByIgnition" SG_ 2464284997 SOK_Zeit_BMS_NV_Zeit 0;
BA_ "GenSigSendType" SG_ 2464153665 SOK_Zeit_DCDC_Challenge 3;
BA_ "GenSigSwitchedByIgnition" SG_ 2464153665 SOK_Zeit_DCDC_Challenge 0;
BA_ "GenSigSendType" SG_ 2464153785 SOK_Zeit_DCDC_NV_Challenge 3;
BA_ "GenSigSwitchedByIgnition" SG_ 2464153785 SOK_Zeit_DCDC_NV_Challenge 0;
BA_ "GenSigSendType" SG_ 2464284857 SOK_Zeit_DCDC_NV_Signatur 3;
BA_ "GenSigFuncType" SG_ 2464284857 SOK_Zeit_DCDC_NV_Signatur 15;
BA_ "GenSigSwitchedByIgnition" SG_ 2464284857 SOK_Zeit_DCDC_NV_Signatur 0;
BA_ "GenSigSendType" SG_ 2464284857 SOK_Zeit_DCDC_NV_Zeit 3;
BA_ "GenSigSwitchedByIgnition" SG_ 2464284857 SOK_Zeit_DCDC_NV_Zeit 0;
BA_ "GenSigSendType" SG_ 2464284737 SOK_Zeit_DCDC_Signatur 3;
BA_ "GenSigFuncType" SG_ 2464284737 SOK_Zeit_DCDC_Signatur 15;
BA_ "GenSigSwitchedByIgnition" SG_ 2464284737 SOK_Zeit_DCDC_Signatur 0;
BA_ "GenSigSendType" SG_ 2464284737 SOK_Zeit_DCDC_Zeit 3;
BA_ "GenSigSwitchedByIgnition" SG_ 2464284737 SOK_Zeit_DCDC_Zeit 0;
BA_ "GenSigSendType" SG_ 2464153723 SOK_Zeit_Hybrid_01_Challenge 3;
BA_ "GenSigSwitchedByIgnition" SG_ 2464153723 SOK_Zeit_Hybrid_01_Challenge 0;
BA_ "GenSigSendType" SG_ 2464284795 SOK_Zeit_Hybrid_01_Signatur 3;
BA_ "GenSigFuncType" SG_ 2464284795 SOK_Zeit_Hybrid_01_Signatur 15;
BA_ "GenSigSwitchedByIgnition" SG_ 2464284795 SOK_Zeit_Hybrid_01_Signatur 0;
BA_ "GenSigSendType" SG_ 2464284795 SOK_Zeit_Hybrid_01_Zeit 3;
BA_ "GenSigSwitchedByIgnition" SG_ 2464284795 SOK_Zeit_Hybrid_01_Zeit 0;
BA_ "GenSigSendType" SG_ 2464153670 SOK_Zeit_Klima_Challenge 3;
BA_ "GenSigSwitchedByIgnition" SG_ 2464153670 SOK_Zeit_Klima_Challenge 0;
BA_ "GenSigSendType" SG_ 2464284742 SOK_Zeit_Klima_Signatur 3;
BA_ "GenSigFuncType" SG_ 2464284742 SOK_Zeit_Klima_Signatur 15;
BA_ "GenSigSwitchedByIgnition" SG_ 2464284742 SOK_Zeit_Klima_Signatur 0;
BA_ "GenSigSendType" SG_ 2464288838 SOK_Zeit_Klima_Zeit 3;
BA_ "GenSigSwitchedByIgnition" SG_ 2464288838 SOK_Zeit_Klima_Zeit 0;
BA_ "GenSigSendType" SG_ 2464153668 SOK_Zeit_OCC_Challenge 3;
BA_ "GenSigSwitchedByIgnition" SG_ 2464153668 SOK_Zeit_OCC_Challenge 0;
BA_ "GenSigSendType" SG_ 2464284740 SOK_Zeit_OCC_Signatur 3;
BA_ "GenSigFuncType" SG_ 2464284740 SOK_Zeit_OCC_Signatur 15;
BA_ "GenSigSwitchedByIgnition" SG_ 2464284740 SOK_Zeit_OCC_Signatur 0;
BA_ "GenSigSendType" SG_ 2464284740 SOK_Zeit_OCC_Zeit 3;
BA_ "GenSigSwitchedByIgnition" SG_ 2464284740 SOK_Zeit_OCC_Zeit 0;
BA_ "GenSigSendType" SG_ 2464153883 SOK_Zeit_SACID_1_Challenge 3;
BA_ "GenSigSwitchedByIgnition" SG_ 2464153883 SOK_Zeit_SACID_1_Challenge 0;
BA_ "GenSigSendType" SG_ 2464284955 SOK_Zeit_SACID_1_Signatur 3;
BA_ "GenSigFuncType" SG_ 2464284955 SOK_Zeit_SACID_1_Signatur 15;
BA_ "GenSigSwitchedByIgnition" SG_ 2464284955 SOK_Zeit_SACID_1_Signatur 0;
BA_ "GenSigSendType" SG_ 2464284955 SOK_Zeit_SACID_1_Zeit 3;
BA_ "GenSigSwitchedByIgnition" SG_ 2464284955 SOK_Zeit_SACID_1_Zeit 0;
BA_ "GenSigSendType" SG_ 1467 SoSe_SunInt_2D_Li 0;
BA_ "GenSigStartValue" SG_ 1467 SoSe_SunInt_2D_Li 254;
BA_ "GenSigSwitchedByIgnition" SG_ 1467 SoSe_SunInt_2D_Li 0;
BA_ "Fehlerwert" SG_ 1467 SoSe_SunInt_2D_Li 255;
BA_ "GenSigSendType" SG_ 1467 SoSe_SunInt_2D_Re 0;
BA_ "GenSigStartValue" SG_ 1467 SoSe_SunInt_2D_Re 254;
BA_ "GenSigSwitchedByIgnition" SG_ 1467 SoSe_SunInt_2D_Re 0;
BA_ "Fehlerwert" SG_ 1467 SoSe_SunInt_2D_Re 255;
BA_ "GenSigSendType" SG_ 2527679739 STK_AirCLeaner_Anf 3;
BA_ "GenSigSwitchedByIgnition" SG_ 2527679739 STK_AirCLeaner_Anf 0;
BA_ "GenSigSendType" SG_ 2527679739 STK_Anf_AussenspiegelHZ 0;
BA_ "GenSigSwitchedByIgnition" SG_ 2527679739 STK_Anf_AussenspiegelHZ 0;
BA_ "GenSigSendType" SG_ 2527679739 STK_Berechnungsphase 3;
BA_ "GenSigStartValue" SG_ 2527679739 STK_Berechnungsphase 2;
BA_ "GenSigSwitchedByIgnition" SG_ 2527679739 STK_Berechnungsphase 0;
BA_ "Fehlerwert" SG_ 2527679739 STK_Berechnungsphase 3;
BA_ "GenSigSendType" SG_ 2527679739 STK_Betriebsdauer 0;
BA_ "GenSigSwitchedByIgnition" SG_ 2527679739 STK_Betriebsdauer 0;
BA_ "GenSigSendType" SG_ 2527679739 STK_ErwVK_Anf 3;
BA_ "GenSigSwitchedByIgnition" SG_ 2527679739 STK_ErwVK_Anf 0;
BA_ "GenSigSendType" SG_ 2527679739 STK_ErwVK_Beifahrerzone 3;
BA_ "GenSigSwitchedByIgnition" SG_ 2527679739 STK_ErwVK_Beifahrerzone 0;
BA_ "GenSigSendType" SG_ 2527679739 STK_ErwVK_Fahrerzone 3;
BA_ "GenSigSwitchedByIgnition" SG_ 2527679739 STK_ErwVK_Fahrerzone 0;
BA_ "GenSigSendType" SG_ 2527679739 STK_ErwVK_Heckzone2_links 0;
BA_ "GenSigSwitchedByIgnition" SG_ 2527679739 STK_ErwVK_Heckzone2_links 0;
BA_ "GenSigSendType" SG_ 2527679739 STK_ErwVK_Heckzone2_rechts 0;
BA_ "GenSigSwitchedByIgnition" SG_ 2527679739 STK_ErwVK_Heckzone2_rechts 0;
BA_ "GenSigSendType" SG_ 2527679739 STK_ErwVK_Heckzone_links 3;
BA_ "GenSigSwitchedByIgnition" SG_ 2527679739 STK_ErwVK_Heckzone_links 0;
BA_ "GenSigSendType" SG_ 2527679739 STK_ErwVK_Heckzone_rechts 3;
BA_ "GenSigSwitchedByIgnition" SG_ 2527679739 STK_ErwVK_Heckzone_rechts 0;
BA_ "GenSigSendType" SG_ 2527679739 STK_ErwVK_Modus 3;
BA_ "GenSigSwitchedByIgnition" SG_ 2527679739 STK_ErwVK_Modus 0;
BA_ "GenSigSendType" SG_ 2527679739 STK_ErwVK_Scheibenheizung 3;
BA_ "GenSigSwitchedByIgnition" SG_ 2527679739 STK_ErwVK_Scheibenheizung 0;
BA_ "GenSigSendType" SG_ 2527679739 STK_FSH_Anf 3;
BA_ "GenSigSwitchedByIgnition" SG_ 2527679739 STK_FSH_Anf 0;
BA_ "GenSigSendType" SG_ 2527679739 STK_GesamtEnergiebedarf 0;
BA_ "GenSigStartValue" SG_ 2527679739 STK_GesamtEnergiebedarf 254;
BA_ "GenSigSwitchedByIgnition" SG_ 2527679739 STK_GesamtEnergiebedarf 0;
BA_ "Fehlerwert" SG_ 2527679739 STK_GesamtEnergiebedarf 255;
BA_ "GenSigSendType" SG_ 2527679739 STK_HSH_Anf 3;
BA_ "GenSigSwitchedByIgnition" SG_ 2527679739 STK_HSH_Anf 0;
BA_ "GenSigSendType" SG_ 2527679739 STK_Klima_Temp 0;
BA_ "GenSigStartValue" SG_ 2527679739 STK_Klima_Temp 30;
BA_ "GenSigSwitchedByIgnition" SG_ 2527679739 STK_Klima_Temp 0;
BA_ "Fehlerwert" SG_ 2527679739 STK_Klima_Temp 31;
BA_ "GenSigSendType" SG_ 2527679739 STK_KurzVK_Anf 3;
BA_ "GenSigSwitchedByIgnition" SG_ 2527679739 STK_KurzVK_Anf 0;
BA_ "GenSigSendType" SG_ 2527679739 STK_MaxLeistung 0;
BA_ "GenSigStartValue" SG_ 2527679739 STK_MaxLeistung 254;
BA_ "GenSigSwitchedByIgnition" SG_ 2527679739 STK_MaxLeistung 0;
BA_ "Fehlerwert" SG_ 2527679739 STK_MaxLeistung 255;
BA_ "GenSigSendType" SG_ 2527679739 STK_Standklima_Anf 3;
BA_ "GenSigSwitchedByIgnition" SG_ 2527679739 STK_Standklima_Anf 0;
BA_ "GenSigSendType" SG_ 2527679739 STK_Standklima_Timer_Status 3;
BA_ "GenSigSwitchedByIgnition" SG_ 2527679739 STK_Standklima_Timer_Status 0;
BA_ "GenSigSendType" SG_ 2527679739 STK_Stecker_Status 0;
BA_ "GenSigSwitchedByIgnition" SG_ 2527679739 STK_Stecker_Status 0;
BA_ "GenSigSendType" SG_ 2527679739 STK_VK_Modus 3;
BA_ "GenSigSwitchedByIgnition" SG_ 2527679739 STK_VK_Modus 0;
BA_ "Fehlerwert" SG_ 2527679739 STK_VK_Modus 3;
BA_ "GenSigSendType" SG_ 2527679739 STK_VK_STH_Einsatz 3;
BA_ "GenSigStartValue" SG_ 2527679739 STK_VK_STH_Einsatz 6;
BA_ "GenSigSwitchedByIgnition" SG_ 2527679739 STK_VK_STH_Einsatz 0;
BA_ "Fehlerwert" SG_ 2527679739 STK_VK_STH_Einsatz 7;
BA_ "GenSigSendType" SG_ 2527679739 STK_VK_Timer_Status 3;
BA_ "GenSigSwitchedByIgnition" SG_ 2527679739 STK_VK_Timer_Status 0;
BA_ "GenSigSendType" SG_ 2527679739 STK_Voko_LED 3;
BA_ "GenSigSwitchedByIgnition" SG_ 2527679739 STK_Voko_LED 0;
BA_ "GenSigSendType" SG_ 1313 STH_EKP_Anst 0;
BA_ "GenSigSwitchedByIgnition" SG_ 1313 STH_EKP_Anst 0;
BA_ "GenSigSendType" SG_ 1313 STH_Fehler_ElWaPu 0;
BA_ "GenSigSwitchedByIgnition" SG_ 1313 STH_Fehler_ElWaPu 0;
BA_ "Fehlerwert" SG_ 1313 STH_Fehler_ElWaPu 1;
BA_ "GenSigSendType" SG_ 1313 STH_Fehlerstatus 0;
BA_ "GenSigSwitchedByIgnition" SG_ 1313 STH_Fehlerstatus 0;
BA_ "GenSigSendType" SG_ 1313 STH_Funk_aus 0;
BA_ "GenSigSwitchedByIgnition" SG_ 1313 STH_Funk_aus 0;
BA_ "GenSigSendType" SG_ 1313 STH_Funk_ein 0;
BA_ "GenSigSwitchedByIgnition" SG_ 1313 STH_Funk_ein 0;
BA_ "GenSigSendType" SG_ 1313 STH_Geblaese 0;
BA_ "GenSigSwitchedByIgnition" SG_ 1313 STH_Geblaese 0;
BA_ "GenSigSendType" SG_ 1313 STH_Heizleistung 0;
BA_ "GenSigSwitchedByIgnition" SG_ 1313 STH_Heizleistung 0;
BA_ "GenSigSendType" SG_ 1313 STH_KL_HUP 0;
BA_ "GenSigSwitchedByIgnition" SG_ 1313 STH_KL_HUP 0;
BA_ "GenSigSendType" SG_ 1313 STH_KVS 0;
BA_ "GenSigSwitchedByIgnition" SG_ 1313 STH_KVS 0;
BA_ "GenSigSendType" SG_ 1313 STH_KVS_Ueberlauf 0;
BA_ "GenSigSwitchedByIgnition" SG_ 1313 STH_KVS_Ueberlauf 0;
BA_ "GenSigSendType" SG_ 1313 STH_LED 0;
BA_ "GenSigSwitchedByIgnition" SG_ 1313 STH_LED 0;
BA_ "GenSigSendType" SG_ 1313 STH_Motorvorwaermung 0;
BA_ "GenSigSwitchedByIgnition" SG_ 1313 STH_Motorvorwaermung 0;
BA_ "GenSigSendType" SG_ 1313 STH_Pumpe_ein 0;
BA_ "GenSigSwitchedByIgnition" SG_ 1313 STH_Pumpe_ein 0;
BA_ "GenSigSendType" SG_ 1313 STH_Pumpen_Anf_extern 0;
BA_ "GenSigSwitchedByIgnition" SG_ 1313 STH_Pumpen_Anf_extern 0;
BA_ "GenSigSendType" SG_ 1313 STH_Servicemode 0;
BA_ "GenSigSwitchedByIgnition" SG_ 1313 STH_Servicemode 0;
BA_ "GenSigSendType" SG_ 1313 STH_SH_ZH 0;
BA_ "GenSigSwitchedByIgnition" SG_ 1313 STH_SH_ZH 0;
BA_ "GenSigSendType" SG_ 1313 STH_Start_folgt 0;
BA_ "GenSigSwitchedByIgnition" SG_ 1313 STH_Start_folgt 0;
BA_ "GenSigSendType" SG_ 1313 STH_Texte 0;
BA_ "GenSigSwitchedByIgnition" SG_ 1313 STH_Texte 0;
BA_ "GenSigSendType" SG_ 1313 STH_Ventil_Status 0;
BA_ "GenSigSwitchedByIgnition" SG_ 1313 STH_Ventil_Status 0;
BA_ "GenSigSendType" SG_ 1313 STH_Ventiloeffnungszeit 0;
BA_ "GenSigSwitchedByIgnition" SG_ 1313 STH_Ventiloeffnungszeit 0;
BA_ "GenSigSendType" SG_ 1313 STH_Waermeeintrag 0;
BA_ "GenSigSwitchedByIgnition" SG_ 1313 STH_Waermeeintrag 0;
BA_ "GenSigSendType" SG_ 1313 STH_war_aktiv 0;
BA_ "GenSigSwitchedByIgnition" SG_ 1313 STH_war_aktiv 0;
BA_ "GenSigSendType" SG_ 1313 STH_Wassertemp 0;
BA_ "GenSigStartValue" SG_ 1313 STH_Wassertemp 254;
BA_ "GenSigSwitchedByIgnition" SG_ 1313 STH_Wassertemp 0;
BA_ "Fehlerwert" SG_ 1313 STH_Wassertemp 255;
BA_ "GenSigSendType" SG_ 1313 STH_Zusatzheizung 0;
BA_ "GenSigSwitchedByIgnition" SG_ 1313 STH_Zusatzheizung 0;
BA_REL_ "GenSigTimeoutTime" BU_SG_REL_ BMS_NV_12V SG_ 2600468665 NM_DCDC_NV_NM_State 2000;
BA_REL_ "GenSigTimeoutTime" BU_SG_REL_ BMS_NV_12V SG_ 2600468496 NM_Gateway_NM_State 2000;
BA_REL_ "GenSigTimeoutTime" BU_SG_REL_ BMS_NV_12V SG_ 2600468550 NM_Klima_NM_State 2000;
BA_REL_ "GenSigTimeoutTime" BU_SG_REL_ Gateway_Max SG_ 2600468805 NM_BMS_NV_CBV_AWB 2000;
BA_REL_ "GenSigTimeoutTime" BU_SG_REL_ Gateway_Max SG_ 2600468805 NM_BMS_NV_CBV_CRI 2000;
BA_REL_ "GenSigTimeoutTime" BU_SG_REL_ Gateway_Max SG_ 2600468805 NM_BMS_NV_Car_Wakeup 2000;
BA_REL_ "GenSigTimeoutTime" BU_SG_REL_ Gateway_Max SG_ 2600468805 NM_BMS_NV_CAB_V14 2000;
BA_REL_ "GenSigTimeoutTime" BU_SG_REL_ Gateway_Max SG_ 2600468665 NM_DCDC_NV_CBV_AWB 2000;
BA_REL_ "GenSigTimeoutTime" BU_SG_REL_ Gateway_Max SG_ 2600468665 NM_DCDC_NV_CBV_CRI 2000;
BA_REL_ "GenSigTimeoutTime" BU_SG_REL_ Gateway_Max SG_ 2600468665 NM_DCDC_NV_Car_Wakeup 2000;
BA_REL_ "GenSigTimeoutTime" BU_SG_REL_ Gateway_Max SG_ 2600468665 NM_DCDC_CAB_V14 2000;
BA_REL_ "GenSigTimeoutTime" BU_SG_REL_ Gateway_Max SG_ 2600468550 NM_Klima_CBV_AWB 2000;
BA_REL_ "GenSigTimeoutTime" BU_SG_REL_ Gateway_Max SG_ 2600468550 NM_Klima_CBV_CRI 2000;
BA_REL_ "GenSigTimeoutTime" BU_SG_REL_ Gateway_Max SG_ 2600468550 NM_Klima_Car_Wakeup 2000;
BA_REL_ "GenSigTimeoutTime" BU_SG_REL_ Gateway_Max SG_ 2600468550 NM_Klima_CAB_V14 2000;
BA_REL_ "GenSigTimeoutTime" BU_SG_REL_ Gateway_Max SG_ 2463978776 OBG_01_CRC 1000;
BA_REL_ "GenSigTimeoutTime" BU_SG_REL_ Gateway_Max SG_ 2463978776 OBG_01_BZ 1000;
BA_REL_ "GenSigTimeoutTime" BU_SG_REL_ Gateway_Max SG_ 2463978776 HVLE_IstSpannung_HV 1000;
BA_REL_ "GenSigTimeoutTime" BU_SG_REL_ Gateway_Max SG_ 2463978776 HVLE_Ist_Wirkungsgrad 1000;
BA_REL_ "GenSigTimeoutTime" BU_SG_REL_ Gateway_Max SG_ 2463978776 HVLE_Netzfrequenz_EVU 1000;
BA_REL_ "GenSigTimeoutTime" BU_SG_REL_ Gateway_Max SG_ 2463978776 HVLE_Energiemenge_Laden 1000;
BA_REL_ "GenSigTimeoutTime" BU_SG_REL_ Gateway_Max SG_ 2463978776 HVLE_I_istAC_Netz_L1 1000;
BA_REL_ "GenSigTimeoutTime" BU_SG_REL_ Gateway_Max SG_ 2463978776 HVLE_I_istAC_Netz_L2 1000;
BA_REL_ "GenSigTimeoutTime" BU_SG_REL_ Gateway_Max SG_ 2463978776 HVLE_I_istAC_Netz_L3 1000;
BA_REL_ "GenSigTimeoutTime" BU_SG_REL_ Gateway_Max SG_ 2463978776 HVLE_U_istAC_Netz_L1 1000;
BA_REL_ "GenSigTimeoutTime" BU_SG_REL_ Gateway_Max SG_ 2463978776 HVLE_U_istAC_Netz_L2 1000;
BA_REL_ "GenSigTimeoutTime" BU_SG_REL_ Gateway_Max SG_ 2463978776 HVLE_U_istAC_Netz_L3 1000;
BA_REL_ "GenSigTimeoutTime" BU_SG_REL_ Gateway_Max SG_ 2463978776 HVLE_OBG_DC_MaxStrom 1000;
BA_REL_ "GenSigTimeoutTime" BU_SG_REL_ Gateway_Max SG_ 2463978776 HVLE_OBG_DC_IstStrom 1000;
BA_REL_ "GenSigTimeoutTime" BU_SG_REL_ Gateway_Max SG_ 2463978776 HVLE_Netzmodus 1000;
BA_REL_ "GenSigTimeoutTime" BU_SG_REL_ Gateway_Max SG_ 2463978776 HVLE_Derating_Temperatur 1000;
BA_REL_ "GenSigTimeoutTime" BU_SG_REL_ Gateway_Max SG_ 2463978776 HVLE_OBG_IstModus 1000;
BA_REL_ "GenSigTimeoutTime" BU_SG_REL_ Gateway_Max SG_ 2463978776 HVLE_OBG_Warnzustand 1000;
BA_REL_ "GenSigTimeoutTime" BU_SG_REL_ Gateway_Max SG_ 2463978776 HVLE_OBG_Fehlerstatus 1000;
BA_REL_ "GenSigTimeoutTime" BU_SG_REL_ Gateway_Max SG_ 2463978776 HVLE_OBG_Status_EoHVL 1000;
BA_REL_ "GenSigTimeoutTime" BU_SG_REL_ Gateway_Max SG_ 2463978776 HVLE_OBG_Fehlerstrom 1000;
BA_REL_ "GenSigTimeoutTime" BU_SG_REL_ Gateway_Max SG_ 2463978776 HVLE_AnzahlVerwendeterPhasen 1000;
BA_REL_ "GenSigTimeoutTime" BU_SG_REL_ Gateway_Max SG_ 2463978776 HVLE_AsymmetrischLadenMoeglich 1000;
BA_REL_ "GenSigTimeoutTime" BU_SG_REL_ Gateway_Max SG_ 2463978776 HVLE_OBG_Typ_verbaut 1000;
BA_REL_ "GenSigTimeoutTime" BU_SG_REL_ Gateway_Max SG_ 2463978776 HVLE_PE_Monitor 1000;
BA_REL_ "GenSigTimeoutTime" BU_SG_REL_ Gateway_Max SG_ 2463978776 HVLE_OBG_Status_Spgfreiheit 1000;
BA_REL_ "GenSigTimeoutTime" BU_SG_REL_ Gateway_Max SG_ 2463978776 HVLE_OBG_Kuehltemperatur 1000;
BA_REL_ "GenSigTimeoutTime" BU_SG_REL_ Gateway_Max SG_ 1328 PTC_I_ist 2000;
BA_REL_ "GenSigTimeoutTime" BU_SG_REL_ Klima SG_ 1156 ND_Heading 2000;
BA_REL_ "GenSigTimeoutTime" BU_SG_REL_ Klima SG_ 1157 NP_Altitude 2000;
BA_REL_ "GenSigTimeoutTime" BU_SG_REL_ Klima SG_ 1157 ND_UTC 2000;
BA_REL_ "GenSigTimeoutTime" BU_SG_REL_ Klima SG_ 1158 NP_LatDegree 2000;
BA_REL_ "GenSigTimeoutTime" BU_SG_REL_ Klima SG_ 1158 NP_LongDegree 2000;
BA_REL_ "GenSigTimeoutTime" BU_SG_REL_ Klima SG_ 1158 NP_LatDirection 2000;
BA_REL_ "GenSigTimeoutTime" BU_SG_REL_ Klima SG_ 1158 NP_LongDirection 2000;
BA_REL_ "GenSigTimeoutTime" BU_SG_REL_ Klima SG_ 2600468805 NM_BMS_NV_NM_State 2000;
BA_REL_ "GenSigTimeoutTime" BU_SG_REL_ Klima SG_ 2600468665 NM_DCDC_NV_NM_State 2000;
BA_REL_ "GenSigTimeoutTime" BU_SG_REL_ Klima SG_ 2600468496 NM_Gateway_NM_State 2000;
BA_REL_ "GenSigTimeoutTime" BU_SG_REL_ Klima SG_ 2589283656 ORU_Status 5000;
BA_REL_ "GenSigTimeoutTime" BU_SG_REL_ Klima SG_ 2527679498 Perso_Kontonummer 5000;
BA_REL_ "GenSigTimeoutTime" BU_SG_REL_ Klima SG_ 2527679498 Perso_Steuerung 5000;
BA_REL_ "GenSigTimeoutTime" BU_SG_REL_ Klima SG_ 2527679498 Perso_Steuerungsparameter 5000;
BA_REL_ "GenSigTimeoutTime" BU_SG_REL_ Klima SG_ 2527679498 Perso_Status 5000;
BA_REL_ "GenSigTimeoutTime" BU_SG_REL_ Klima SG_ 2527679498 Perso_Bedienstelle 5000;
BA_REL_ "GenSigTimeoutTime" BU_SG_REL_ Klima SG_ 2527679498 Perso_Freigabe_Verstellung 5000;
BA_REL_ "GenSigTimeoutTime" BU_SG_REL_ Klima SG_ 2527679498 Perso_Aktiv 5000;
BA_REL_ "GenSigTimeoutTime" BU_SG_REL_ Klima SG_ 2527679498 IAA_PSO_wake_up 5000;
BA_REL_ "GenSigTimeoutTime" BU_SG_REL_ Klima SG_ 2527679498 Perso_Fahrernummer 5000;
BA_REL_ "GenSigTimeoutTime" BU_SG_REL_ Klima SG_ 2527679498 Perso_Schreibschutz 5000;
BA_REL_ "GenSigTimeoutTime" BU_SG_REL_ Klima SG_ 2527679498 IAA_Active_User_ID 5000;
BA_REL_ "GenSigTimeoutTime" BU_SG_REL_ Klima SG_ 2527679498 IAA_Identified_User_ID 5000;
BA_REL_ "GenSigTimeoutTime" BU_SG_REL_ Klima SG_ 1616 RA_Frequency 5000;
BA_REL_ "GenSigTimeoutTime" BU_SG_REL_ Klima SG_ 1616 RA_Frequency_unit 5000;
BA_REL_ "GenSigTimeoutTime" BU_SG_REL_ Klima SG_ 1616 RA_AM_Tuning 5000;
BA_REL_ "GenSigTimeoutTime" BU_SG_REL_ Klima SG_ 1440 LS_Helligkeit_IR 2000;
BA_REL_ "GenSigTimeoutTime" BU_SG_REL_ Klima SG_ 1440 RS_Regenmenge 2000;
BA_REL_ "GenSigTimeoutTime" BU_SG_REL_ Klima SG_ 1440 RS_defekt 2000;
BA_REL_ "GenSigTimeoutTime" BU_SG_REL_ Klima SG_ 1440 RS_Wischergeschwindigkeit 2000;
BA_REL_ "GenSigTimeoutTime" BU_SG_REL_ Klima SG_ 1504 MD1_Position 5000;
BA_REL_ "GenSigTimeoutTime" BU_SG_REL_ Klima SG_ 1504 MD1_Lage 5000;
BA_REL_ "GenSigTimeoutTime" BU_SG_REL_ Klima SG_ 1504 MD3_Position 5000;
BA_REL_ "GenSigTimeoutTime" BU_SG_REL_ Klima SG_ 1504 MD3_Lage 5000;
BA_REL_ "GenSigTimeoutTime" BU_SG_REL_ Klima SG_ 1504 MRollo_Position 5000;
BA_REL_ "GenSigTimeoutTime" BU_SG_REL_ Klima SG_ 1504 MRollo_Lage 5000;
BA_REL_ "GenSigTimeoutTime" BU_SG_REL_ Klima SG_ 980 LRH_On_Off 5000;
BA_REL_ "GenSigTimeoutTime" BU_SG_REL_ Klima SG_ 1467 SoSe_SunInt_2D_Li 5000;
BA_REL_ "GenSigTimeoutTime" BU_SG_REL_ Klima SG_ 1467 SoSe_SunInt_2D_Re 5000;
BA_REL_ "GenSigTimeoutTime" BU_SG_REL_ Klima SG_ 2527679739 STK_Betriebsdauer 5000;
BA_REL_ "GenSigTimeoutTime" BU_SG_REL_ Klima SG_ 2527679739 STK_FSH_Anf 5000;
BA_REL_ "GenSigTimeoutTime" BU_SG_REL_ Klima SG_ 2527679739 STK_HSH_Anf 5000;
BA_REL_ "GenSigTimeoutTime" BU_SG_REL_ Klima SG_ 2527679739 STK_Klima_Temp 5000;
BA_REL_ "GenSigTimeoutTime" BU_SG_REL_ Klima SG_ 2527679739 STK_KurzVK_Anf 5000;
BA_REL_ "GenSigTimeoutTime" BU_SG_REL_ Klima SG_ 2527679739 STK_Standklima_Anf 5000;
BA_REL_ "GenSigTimeoutTime" BU_SG_REL_ Klima SG_ 2527679739 STK_Standklima_Timer_Status 5000;
BA_REL_ "GenSigTimeoutTime" BU_SG_REL_ Klima SG_ 2527679739 STK_AirCLeaner_Anf 5000;
BA_REL_ "GenSigTimeoutTime" BU_SG_REL_ Klima SG_ 2527679739 STK_VK_Modus 5000;
BA_REL_ "GenSigTimeoutTime" BU_SG_REL_ Klima SG_ 2527679739 STK_ErwVK_Anf 5000;
BA_REL_ "GenSigTimeoutTime" BU_SG_REL_ Klima SG_ 2527679739 STK_ErwVK_Modus 5000;
BA_REL_ "GenSigTimeoutTime" BU_SG_REL_ Klima SG_ 2527679739 STK_Berechnungsphase 5000;
BA_REL_ "GenSigTimeoutTime" BU_SG_REL_ Klima SG_ 2527679739 STK_Anf_AussenspiegelHZ 5000;
BA_REL_ "GenSigTimeoutTime" BU_SG_REL_ Klima SG_ 2527679739 STK_ErwVK_Beifahrerzone 5000;
BA_REL_ "GenSigTimeoutTime" BU_SG_REL_ Klima SG_ 2527679739 STK_ErwVK_Fahrerzone 5000;
BA_REL_ "GenSigTimeoutTime" BU_SG_REL_ Klima SG_ 2527679739 STK_ErwVK_Heckzone_links 5000;
BA_REL_ "GenSigTimeoutTime" BU_SG_REL_ Klima SG_ 2527679739 STK_ErwVK_Heckzone_rechts 5000;
BA_REL_ "GenSigTimeoutTime" BU_SG_REL_ Klima SG_ 2527679739 STK_ErwVK_Scheibenheizung 5000;
BA_REL_ "GenSigTimeoutTime" BU_SG_REL_ Klima SG_ 2527679739 STK_VK_STH_Einsatz 5000;
BA_REL_ "GenSigTimeoutTime" BU_SG_REL_ Klima SG_ 2527679739 STK_Voko_LED 5000;
BA_REL_ "GenSigTimeoutTime" BU_SG_REL_ Klima SG_ 2527679739 STK_MaxLeistung 5000;
BA_REL_ "GenSigTimeoutTime" BU_SG_REL_ Klima SG_ 2527679739 STK_Stecker_Status 5000;
BA_REL_ "GenSigTimeoutTime" BU_SG_REL_ Klima SG_ 2527679739 STK_ErwVK_Heckzone2_links 5000;
BA_REL_ "GenSigTimeoutTime" BU_SG_REL_ Klima SG_ 2527679739 STK_ErwVK_Heckzone2_rechts 5000;
BA_REL_ "GenSigTimeoutTime" BU_SG_REL_ Klima SG_ 1313 STH_LED 2000;
BA_REL_ "GenSigTimeoutTime" BU_SG_REL_ Klima SG_ 1313 STH_Geblaese 2000;
BA_REL_ "GenSigTimeoutTime" BU_SG_REL_ Klima SG_ 1313 STH_Ventil_Status 2000;
BA_REL_ "GenSigTimeoutTime" BU_SG_REL_ Klima SG_ 1313 STH_Waermeeintrag 2000;
BA_REL_ "GenSigTimeoutTime" BU_SG_REL_ Klima SG_ 1313 STH_KL_HUP 2000;
BA_REL_ "GenSigTimeoutTime" BU_SG_REL_ Klima SG_ 1313 STH_Fehlerstatus 2000;
BA_REL_ "GenSigTimeoutTime" BU_SG_REL_ Klima SG_ 1313 STH_Heizleistung 2000;
BA_REL_ "GenSigTimeoutTime" BU_SG_REL_ Klima SG_ 1313 STH_Wassertemp 2000;
BA_REL_ "GenSigTimeoutTime" BU_SG_REL_ Klima SG_ 1313 STH_Texte 2000;
BA_REL_ "GenSigTimeoutTime" BU_SG_REL_ Klima SG_ 1313 STH_war_aktiv 2000;
BA_REL_ "GenSigTimeoutTime" BU_SG_REL_ Klima SG_ 1313 STH_SH_ZH 2000;
VAL_ 1156 ND_VDOP 1022 "Init" 1023 "Fehler" ;
VAL_ 1156 ND_TDOP 1022 "Init" 1023 "Fehler" ;
VAL_ 1156 ND_HDOP 1022 "Init" 1023 "Fehler" ;
VAL_ 1156 ND_GDOP 1022 "Init" 1023 "Fehler" ;
VAL_ 1156 ND_PDOP 1022 "Init" 1023 "Fehler" ;
VAL_ 1156 ND_Heading 4094 "Init" 4095 "Fehler" ;
VAL_ 1156 ND_Init 0 "nicht_Initialisiert" 1 "Initialisiert" ;
VAL_ 1157 ND_SatInUse 30 "Init" 31 "Fehler" ;
VAL_ 1157 POS_Guete_horizontal_verfuegbar 0 "nicht_verfuegbar" 1 "verfuegbar" ;
VAL_ 1157 ND_SatInView 30 "Init" 31 "Fehler" ;
VAL_ 1157 POS_Guete_horizontal 124 "von_248m_bis_400m" 125 "mehr_als_400m" 126 "Init" 127 "Fehler" ;
VAL_ 1157 NP_Altitude 4094 "Init" 4095 "Fehler" ;
VAL_ 1158 NP_LatDegree 134217726 "Init" 134217727 "Fehler" ;
VAL_ 1158 NP_LongDegree 268435454 "Init" 268435455 "Fehler" ;
VAL_ 1158 NP_LatDirection 0 "Nord" 1 "Sued" ;
VAL_ 1158 NP_LongDirection 0 "Ost" 1 "West" ;
VAL_ 1158 NP_Sat 30 "Init" 31 "Fehler" ;
VAL_ 1158 NP_Fix 0 "Init" 1 "No_Fix" 2 "2D_Fix" 3 "3D_Fix" ;
VAL_ 2600468805 NM_BMS_NV_CBV_AWB 0 "Passiver_WakeUp" 1 "Aktiver_WakeUp" ;
VAL_ 2600468805 NM_BMS_NV_CBV_CRI 0 "NM_ohne_Clusteranforderungen" 1 "NM_mit_Clusteranforderungen" ;
VAL_ 2600468805 NM_BMS_NV_NM_State 0 "Init" 1 "NM_RM_aus_BSM" 2 "NM_RM_aus_PBSM" 4 "NM_NO_aus_RM" 8 "NM_NO_aus_RS" 16 "reserved" 32 "reserved" ;
VAL_ 2600468805 NM_BMS_NV_Car_Wakeup 0 "Inaktiv" 1 "Car_Wakeup" ;
VAL_ 2600468805 NM_BMS_NV_UDS_CC 0 "Inaktiv" 1 "CC_aktiv" ;
VAL_ 2600468805 NM_BMS_NV_NM_aktiv_KL15 0 "Inaktiv" 1 "KL15_EIN" ;
VAL_ 2600468805 NM_BMS_NV_NM_aktiv_Diagnose 0 "Init" 1 "Diagnose_aktiv" ;
VAL_ 2600468805 NM_BMS_NV_NM_aktiv_Tmin 0 "Inaktiv" 1 "Mindestaktivzeit" ;
VAL_ 2600468805 NM_BMS_NV_CAB_V14 0 "Init" 1 "CAB_01_Antrieb" 2 "CAB_02_Hybrid_Laden" 4 "CAB_03_Fahrwerk" 8 "CAB_04_Fahrerassistenz" 16 "CAB_05_Komfort" 32 "CAB_06_Anzeige" 64 "CAB_07_Connect" 128 "CAB_08_MIB" 256 "CAB_09_Standheizung" 1024 "CAB_11_VLAN_Fahrerassistenz" 2048 "CAB_12_VLAN_Komfort" 4096 "CAB_13_VLAN_Connect" 8192 "CAB_14_VLAN_Infotainment" 16384 "CAB_15_Laden" 32768 "CAB_16_Licht" ;
VAL_ 2600468665 NM_DCDC_NV_CBV_AWB 0 "Passiver_WakeUp" 1 "Aktiver_WakeUp" ;
VAL_ 2600468665 NM_DCDC_NV_CBV_CRI 0 "NM_ohne_Clusteranforderungen" 1 "NM_mit_Clusteranforderungen" ;
VAL_ 2600468665 NM_DCDC_NV_NM_State 0 "Init" 1 "NM_RM_aus_BSM" 2 "NM_RM_aus_PBSM" 4 "NM_NO_aus_RM" 8 "NM_NO_aus_RS" 16 "reserved" 32 "reserved" ;
VAL_ 2600468665 NM_DCDC_NV_Car_Wakeup 0 "Inaktiv" 1 "Car_Wakeup" ;
VAL_ 2600468665 NM_DCDC_NV_UDS_CC 0 "Inaktiv" 1 "CC_aktiv" ;
VAL_ 2600468665 NM_DCDC_NV_NM_aktiv_KL15 0 "Inaktiv" 1 "KL15_EIN" ;
VAL_ 2600468665 NM_DCDC_NV_NM_aktiv_Diagnose 0 "Inaktiv" 1 "Diagnose_aktiv" ;
VAL_ 2600468665 NM_DCDC_NV_NM_aktiv_Tmin 0 "Inaktiv" 1 "Mindestaktivzeit" ;
VAL_ 2600468665 NM_DCDC_NV_DCDC_aktiv 0 "Inaktiv" 1 "DCDC_NV_aktiv" ;
VAL_ 2600468665 NM_DCDC_NV_aktiv_Tmin_NO 0 "Inaktiv" 1 "Mindestaktivzeit_NormalOperation" ;
VAL_ 2600468665 NM_DCDC_CAB_V14 0 "Init" 1 "CAB_01_Antrieb" 2 "CAB_02_Hybrid_Laden" 4 "CAB_03_Fahrwerk" 8 "CAB_04_Fahrerassistenz" 16 "CAB_05_Komfort" 32 "CAB_06_Anzeige" 64 "CAB_07_Connect" 128 "CAB_08_MIB" 256 "CAB_09_Standheizung" 1024 "CAB_11_VLAN_Fahrerassistenz" 2048 "CAB_12_VLAN_Komfort" 4096 "CAB_13_VLAN_Connect" 8192 "CAB_14_VLAN_Infotainment" 16384 "CAB_15_Laden" 32768 "CAB_16_Licht" ;
VAL_ 2600468496 NM_Gateway_CBV_AWB 0 "Passiver_WakeUp" 1 "Aktiver_WakeUp" ;
VAL_ 2600468496 NM_Gateway_CBV_CRI 0 "NM_ohne_Clusteranforderungen" 1 "NM_mit_Clusteranforderungen" ;
VAL_ 2600468496 NM_Gateway_NM_State 0 "Init" 1 "NM_RM_aus_BSM" 2 "NM_RM_aus_PBSM" 4 "NM_NO_aus_RM" 8 "NM_NO_aus_RS" 16 "reserved" 32 "reserved" ;
VAL_ 2600468496 NM_Gateway_Car_Wakeup 0 "Inaktiv" 1 "Car_Wakeup" ;
VAL_ 2600468496 NM_Gateway_UDS_CC 0 "Inaktiv" 1 "CC_aktiv" ;
VAL_ 2600468496 NM_Gateway_NM_aktiv_KL15 0 "Inaktiv" 1 "KL15_EIN" ;
VAL_ 2600468496 NM_Gateway_NM_aktiv_Diagnose 0 "Init" 1 "Diagnose_aktiv" ;
VAL_ 2600468496 NM_Gateway_NM_aktiv_Tmin 0 "Inaktiv" 1 "Mindestaktivzeit" ;
VAL_ 2600468496 NM_Gateway_NM_aktiv_CWU 0 "kein_CWU_gesetzt" 1 "CWU_gesetzt" ;
VAL_ 2600468496 NM_Gateway_NM_aktiv_FC 0 "kein_FC_gesetzt" 1 "FC_gesetzt" ;
VAL_ 2600468496 NM_Gateway_NM_aktiv_EM 0 "inaktiv" 1 "Nachlauf_aufgrund_Energiemanagement" ;
VAL_ 2600468496 NM_Gateway_NM_aktiv_Buskopplung 0 "inaktiv" 1 "Nachlauf_aufgrund_Buskopplung" ;
VAL_ 2600468496 NM_Gateway_CAB_V14 0 "Init" 1 "CAB_01_Antrieb" 2 "CAB_02_Hybrid_Laden" 4 "CAB_03_Fahrwerk" 8 "CAB_04_Fahrerassistenz" 16 "CAB_05_Komfort" 32 "CAB_06_Anzeige" 64 "CAB_07_Connect" 128 "CAB_08_MIB" 256 "CAB_09_Standheizung" 1024 "CAB_11_VLAN_Fahrerassistenz" 2048 "CAB_12_VLAN_Komfort" 4096 "CAB_13_VLAN_Connect" 8192 "CAB_14_VLAN_Infotainment" 16384 "CAB_15_Laden" 32768 "CAB_16_Licht" ;
VAL_ 2600468550 NM_Klima_CBV_AWB 0 "Passiver_WakeUp" 1 "Aktiver_WakeUp" ;
VAL_ 2600468550 NM_Klima_CBV_CRI 0 "Standard_Layout" 1 "TNB_Layout" ;
VAL_ 2600468550 NM_Klima_NM_State 0 "Init" 1 "NM_RM_aus_BSM" 2 "NM_RM_aus_PBSM" 4 "NM_NO_aus_RM" 8 "NM_NO_aus_RS" 16 "reserved" 32 "reserved" ;
VAL_ 2600468550 NM_Klima_Car_Wakeup 0 "Inaktiv" 1 "Car_Wakeup" ;
VAL_ 2600468550 NM_Klima_UDS_CC 0 "Init" 1 "CC_aktiv" ;
VAL_ 2600468550 NM_Klima_NM_aktiv_KL15 0 "Inaktiv" 1 "KL15_EIN" ;
VAL_ 2600468550 NM_Klima_NM_aktiv_Diagnose 0 "Init" 1 "Diagnose_aktiv" ;
VAL_ 2600468550 NM_Klima_NM_aktiv_Tmin 0 "Inaktiv" 1 "Mindestaktivzeit" ;
VAL_ 2600468550 NM_Klima_NM_aktiv_STH 0 "Init" 1 "Kommunikation_zu_STH_aktiv" ;
VAL_ 2600468550 NM_Klima_CAB_V14 0 "Init" 1 "CAB_01_Antrieb" 2 "CAB_02_Hybrid_Laden" 4 "CAB_03_Fahrwerk" 8 "CAB_04_Fahrerassistenz" 16 "CAB_05_Komfort" 32 "CAB_06_Anzeige" 64 "CAB_07_Connect" 128 "CAB_08_MIB" 256 "CAB_09_Standheizung" 1024 "CAB_11_VLAN_Fahrerassistenz" 2048 "CAB_12_VLAN_Komfort" 4096 "CAB_13_VLAN_Connect" 8192 "CAB_14_VLAN_Infotainment" 16384 "CAB_15_Laden" 32768 "CAB_16_Licht" ;
VAL_ 2527679508 NVEM_Max_Rampenzeit 0 "No_LRC" 1 "250ms" 2 "500ms" 3 "750ms" 4 "1s" 5 "2s" 6 "3s" 7 "4s" 8 "5s" 9 "6s" 10 "7s" 11 "8s" 12 "9s" 13 "10s" 14 "12s" 15 "15s" ;
VAL_ 2527679508 NVEM_Min_Spannung 126 "Init" 127 "Fehler" ;
VAL_ 2527679508 NVEM_Min_Spannung_Start 62 "Init" 63 "Fehler" ;
VAL_ 2527679508 NVEM_Max_Spannung 126 "Init" 127 "Fehler" ;
VAL_ 2527679508 NVEM_Energie_Klima_Vorgabe 254 "Init" 255 "Fehler" ;
VAL_ 2527679508 NVEM_MV_DC_uMinLV 126 "Init" 127 "Fehler" ;
VAL_ 2527679508 NVEM_MV_DC_uSollLV 126 "Init" 127 "Fehler" ;
VAL_ 2527679508 NVEM_Bordnetzdiagnose 0 "kein_Fehler" 1 "Warnung_1" 2 "Warnung_2" 3 "Warnung_3" ;
VAL_ 527 NVEM_IBatt 255 "Fehler" ;
VAL_ 527 NVEM_MOD_Budget 15 "Init" ;
VAL_ 527 NVEM_MOD_Freigabe 0 "Freigabe_MOD" 1 "Freigabe_MOD_nur_mit_HV" 2 "Stopp_Kein_Wiederholen_Fehler" 3 "Init" ;
VAL_ 527 NVEM_MV_DC_iSoll_NV 254 "Init" 255 "Fehler" ;
VAL_ 527 NVEM_DC_iSoll_NV 254 "Init" 255 "Fehler" ;
VAL_ 527 NVEM_DC_uSoll_NV 255 "Fehler" ;
VAL_ 2463978776 HVLE_IstSpannung_HV 1022 "Init" 1023 "Fehler" ;
VAL_ 2463978776 HVLE_Ist_Wirkungsgrad 126 "Init" 127 "Fehler" ;
VAL_ 2463978776 HVLE_Netzfrequenz_EVU 509 "kein_Frequenz_erkannt" 510 "Init" 511 "Fehler" ;
VAL_ 2463978776 HVLE_I_istAC_Netz_L1 509 "nicht_vorhanden" 510 "Init" 511 "Fehler" ;
VAL_ 2463978776 HVLE_I_istAC_Netz_L2 509 "nicht_vorhanden" 510 "Init" 511 "Fehler" ;
VAL_ 2463978776 HVLE_I_istAC_Netz_L3 509 "nicht_vorhanden" 510 "Init" 511 "Fehler" ;
VAL_ 2463978776 HVLE_U_istAC_Netz_L1 509 "nicht_vorhanden" 510 "Init" 511 "Fehler" ;
VAL_ 2463978776 HVLE_U_istAC_Netz_L2 509 "nicht_vorhanden" 510 "Init" 511 "Fehler" ;
VAL_ 2463978776 HVLE_U_istAC_Netz_L3 509 "nicht_vorhanden" 510 "Init" 511 "Fehler" ;
VAL_ 2463978776 HVLE_OBG_DC_MaxStrom 2046 "Init" 2047 "Fehler" ;
VAL_ 2463978776 HVLE_OBG_DC_IstStrom 2046 "Init" 2047 "Fehler" ;
VAL_ 2463978776 HVLE_Netzmodus 0 "Init" 1 "no_grid" 2 "one_phase_L1" 3 "one_phase_not_L1" 4 "two_phase" 5 "three_phase" 6 "delta_grid" 7 "parallel_phases" 15 "Fehler" ;
VAL_ 2463978776 HVLE_Derating_Temperatur 0 "kein_Derating_aktiv" 1 "Derating_aktiv" ;
VAL_ 2463978776 HVLE_OBG_IstModus 0 "Standby" 1 "Netzladung_aktiv" 2 "Rueckspeisung_aktiv" 3 "Vorladen_aktiv" 4 "Vorladespannung_erreicht_und_halten" 5 "reserve" 6 "Init" 7 "Fehler" ;
VAL_ 2463978776 HVLE_OBG_Warnzustand 0 "keine_Warnung_aktiv" 1 "Leistungsbegrenzung_maxDCAusgangsstrom" 2 "Leistungsbegrenzung_maxDCAusgangsspannung" 3 "Leistungsbegrenzung_Spanungsnetz" 4 "Ueberspannung" 5 "minStromLimit" 6 "Ueberstrom_aktuell" 7 "Ueberstrom_Ladegeraet" 8 "Netzausfall" 9 "Komponentenschutz_aktiv" ;
VAL_ 2463978776 HVLE_OBG_Fehlerstatus 0 "kein_Fehler_aktiv" 1 "Fehler_aktiv_Laden_beendet" ;
VAL_ 2463978776 HVLE_OBG_Status_EoHVL 0 "Init" 1 "Keine_offene_HV_Leitung_erkannt" 2 "offene_HV_Leitung_erkannt" 3 "Fehler" ;
VAL_ 2463978776 HVLE_OBG_Fehlerstrom 0 "Kein_Fehlerstrom" 1 "Fehlerstrom" ;
VAL_ 2463978776 HVLE_OBG_ACDC_IstLeistung 2046 "Init" 2047 "Fehler" ;
VAL_ 2463978776 HVLE_OBG_ACDC_MaxLeistung 2046 "Init" 2047 "Fehler" ;
VAL_ 2463978776 HVLE_OBG_AC_maxStrom 1022 "Init" 1023 "Fehler" ;
VAL_ 2463978776 HVLE_OBG_AC_maxSpannung 1022 "Init" 1023 "Fehler" ;
VAL_ 2463978776 HVLE_AnzahlVerwendeterPhasen 0 "eine_phase_verwendet" 1 "zwei_phasen_verwendet" 2 "drei_phasen_verwendet" 3 "Fehler" ;
VAL_ 2463978776 HVLE_AsymmetrischLadenMoeglich 0 "moeglich" 1 "nicht_moeglich" ;
VAL_ 2463978776 HVLE_OBG_Typ_verbaut 0 "IPB_galvanisch_nichtGetrennt" 1 "SAC" 2 "OCC" 3 "IPB_galvanisch_getrennt" 4 "SAC_galvanisch_getrennt" 5 "Reserve" 6 "Reserve" 7 "Init" ;
VAL_ 2463978776 HVLE_PE_Monitor 0 "keine_PE_Messung_aktiv" 1 "PE_erkannt" 2 "IT-Netz_erkannt" 3 "PE_nicht_erkannt" 7 "Fehler" ;
VAL_ 2463978776 HVLE_OBG_Status_Spgfreiheit 0 "Init__ohne_Funktion" 1 "HV_Komponente_Spannungsfrei" 2 "HV_Komponente_nichtSpannungsfrei" 3 "Fehler" ;
VAL_ 2463978776 HVLE_OBG_Kuehltemperatur 254 "Init" 255 "Fehler" ;
VAL_ 2589283656 ORU_Warnung 0 "keine_Anzeige" 1 "Update_unvollstaendig_Prio1" 2 "Update_fehlgeschlagen_Prio1" 3 "reserviert" ;
VAL_ 2589283656 ORU_Status 0 "IDLE" 1 "PENDING" 2 "PREPARATION" 3 "PREPARATION_HV" 4 "RUNNING" 5 "RUNNING_HV" 6 "PENDING_NOTREADY" 7 "FAILURE_POWERTRAIN_DISABLED" ;
VAL_ 2527679498 Perso_Kontonummer 0 "kein_Benutzerkonto" 1 "Benutzerkonto_1" 2 "Benutzerkonto_2" 3 "Benutzerkonto_3" 4 "Benutzerkonto_4" 5 "Benutzerkonto_5" 6 "Benutzerkonto_6" 7 "Benutzerkonto_7" ;
VAL_ 2527679498 Perso_Steuerung 0 "keine_Steuerung" 1 "Reset_alle_Konten" 2 "Reset_aktives_Konto" 3 "Kopiere_aktives_Konto_nach" 4 "Wiederherstellen_aktives_Konto" 5 "Aktivieren_aktives_Konto" 6 "Reset_Konto" 7 "Reset_alle_Fahrer" 8 "Reset_aktiver_Fahrer" 9 "Reset_Fahrer" ;
VAL_ 2527679498 Perso_Steuerungsparameter 0 "kein_Parameter" 1 "Benutzerkonto_1" 2 "Benutzerkonto_2" 3 "Benutzerkonto_3" 4 "Benutzerkonto_4" 5 "Benutzerkonto_5" 6 "Benutzerkonto_6" 7 "Benutzerkonto_7" ;
VAL_ 2527679498 Perso_Status 0 "deaktiviert" 1 "PSO_1x_aktiviert" 2 "PSO_2x_aktiviert" ;
VAL_ 2527679498 Perso_Bedienstelle 0 "Init" 1 "Kombiinstrument" 2 "ABT" ;
VAL_ 2527679498 Perso_Freigabe_Verstellung 0 "Init" 1 "freigegeben" ;
VAL_ 2527679498 Perso_Aktiv 0 "deaktiviert" 1 "aktiviert" ;
VAL_ 2527679498 IAA_PSO_wake_up 0 "wake_up_inactive" 1 "wake_up_active" ;
VAL_ 2527679498 Perso_Fahrernummer 0 "kein_Fahrer" 1 "Fahrer_1" 2 "Fahrer_2" 3 "Fahrer_3" 4 "Fahrer_4" 5 "Fahrer_5" 6 "Fahrer_6" 7 "Fahrer_7" ;
VAL_ 2527679498 Perso_Schreibschutz 0 "Schreibschutz_deaktiviert" 1 "Schreibschutz_aktiviert" ;
VAL_ 1328 PTC_I_ist 254 "Init" 255 "Fehler" ;
VAL_ 1328 PTC_P_ist 254 "Init" 255 "Fehler" ;
VAL_ 1328 PTCs_01_alt 0 "aktuell" 1 "veraltet" ;
VAL_ 1616 RA_Radio_Error_Flag 0 "kein_KD_Fehler" 1 "KD_Fehler" ;
VAL_ 1616 RA_Frequency_unit 0 "1_kHz" 1 "100_kHz" ;
VAL_ 1616 RA_AM_Tuning 0 "frequency_locked" 1 "AM_tuning" ;
VAL_ 1525 RW_Gesamt_Reichweite_Max_Anzeige 2045 "nicht_verbaut" 2046 "Init" 2047 "Fehler" ;
VAL_ 1525 RW_Reservewarnung_2_aktiv 0 "Init" 1 "inaktiv" 2 "aktiv" 3 "reserviert" ;
VAL_ 1525 RW_RWDS_Lastprofil 2046 "Init" 2047 "Fehler" ;
VAL_ 1525 RW_Gesamt_Reichweite 2045 "nicht_verbaut" 2046 "Init" 2047 "Fehler" ;
VAL_ 1525 RW_Prim_Reichweitenverbrauch 2047 "Init" ;
VAL_ 1525 RW_Prim_Reichweitenv_Einheit 0 "Liter_pro_100km" 1 "kWh_pro_100km" 2 "Kg_pro_100km" 3 "nicht_verbaut" ;
VAL_ 1525 RW_Primaer_Reichweite 2045 "nicht_verbaut" 2046 "Init" 2047 "Fehler" ;
VAL_ 1440 LS_Helligkeit_IR 254 "Init" 255 "Fehler" ;
VAL_ 1440 LS_Helligkeit_FW 1022 "Init" 1023 "Fehler" ;
VAL_ 1440 LS_defekt 0 "OK" 1 "defekt" ;
VAL_ 1440 LS_Verbau 0 "Init" 1 "Lichtsensor_verbaut" ;
VAL_ 1440 RS_Regenmenge 0 "0" 1 "0,0_bis_0,3" 2 "0,31_bis_1,4" 3 "1,41_bis_2,0" 4 "2,01_bis_2,8" 5 "2,81_bis_3,3" 6 "3,31_bis_4,0" 7 "4,01_bis_5,0" 8 "5,01_bis_7,0" 9 "7,01_bis_9,0" 10 "9,01_bis_11,0" 11 "11,01_bis_15,0" 12 "15,01_bis_22,0" 13 ">22,01" 14 "Init" 15 "Fehler" ;
VAL_ 1440 RS_Schwall 0 "Aus" 1 "Ein" ;
VAL_ 1440 RS_Verbau 0 "Init" 1 "Regensensor verbaut" ;
VAL_ 1440 RS_Verglasung_schliessen 0 "Verglasung nicht schliessen" 1 "Verglasung schliessen" ;
VAL_ 1440 RS_defekt 0 "OK" 1 "defekt" ;
VAL_ 1440 RS_Wischergeschwindigkeit 0 "kein Wischen" 1 "42 Huebe/min" 2 "45 Huebe/min" 3 "48 Huebe/min" 4 "51 Huebe/min" 5 "54 Huebe/min" 6 "57 Huebe/min" 7 "60 Huebe/min" ;
VAL_ 1440 RLS_Vorfeldhelligkeit_Boost 0 "groesser_24413_Lux" 1 "bis_24413_Lux" 2 "bis_22193_Lux" 3 "bis_20176_Lux" 4 "bis_18342_Lux" 5 "bis_16647_Lux" 6 "bis_15158_Lux" 7 "bis_13780_Lux" 8 "bis_12527_Lux" 9 "bis_11388_Lux" 10 "bis_10353_Lux" 11 "bis_9412_Lux" 12 "bis_8556_Lux" 13 "bis_7778_Lux" 14 "bis_7071_Lux" 15 "bis_6428_Lux" ;
VAL_ 1440 SLS_Helligkeit_IR 254 "Init" 255 "Fehler" ;
VAL_ 1504 MD1_Position 126 "Init" 127 "nicht_normiert" ;
VAL_ 1504 MD1_Lage 0 "Ausstelllage" 1 "Schiebelage" ;
VAL_ 1504 MD3_Lage 0 "Ausstelllage" 1 "Schiebelage" ;
VAL_ 1504 MRollo_Position 126 "Init" 127 "nicht_normiert" ;
VAL_ 1504 MRollo_Lage 0 "Ausstelllage" 1 "Schiebelage" ;
VAL_ 1504 SAD_normiert 0 "inaktiv" 1 "aktiv" ;
VAL_ 1504 SAD_Thermoschutz 0 "inaktiv" 1 "aktiv" ;
VAL_ 1504 SAD_UEKB_aktiv 0 "inaktiv" 1 "aktiv" ;
VAL_ 1504 Rollo_normiert 0 "inaktiv" 1 "aktiv" ;
VAL_ 1504 Rollo_Thermoschutz 0 "inaktiv" 1 "aktiv" ;
VAL_ 1504 Rollo_UEKB_aktiv 0 "inaktiv" 1 "aktiv" ;
VAL_ 1504 SAD_Taster_Deckel_hi 0 "nicht_betaetigt" 1 "man_sl_zu" 2 "auto_sl_zu" 3 "man_sl_auf" 4 "auto_sl_auf" 5 "man_al_auf" 6 "auto_al_auf" 7 "man_al_zu" 8 "auto_al_zu" 14 "fehler_schalter_haengt" 15 "fehler_schalter_unplausibel" ;
VAL_ 1504 SAD_Taster_Deckel_vo 0 "nicht_betaetigt" 1 "man_sl_zu" 2 "auto_sl_zu" 3 "man_sl_auf" 4 "auto_sl_auf" 5 "man_al_auf" 6 "auto_al_auf" 7 "man_al_zu" 8 "auto_al_zu" 14 "fehler_schalter_haengt" 15 "fehler_schalter_unplausibel" ;
VAL_ 1504 SAD_Taster_Rollo_hi 0 "nicht_betaetigt" 1 "man_zu" 2 "auto_zu" 3 "man_auf" 4 "auto_auf" 6 "fehler_schalter_haengt" 7 "fehler_schalter_unplausibel" ;
VAL_ 1504 SAD_Taster_Rollo_vo 0 "nicht_betaetigt" 1 "man_zu" 2 "auto_zu" 3 "man_auf" 4 "auto_auf" 6 "fehler_schalter_haengt" 7 "fehler_schalter_unplausibel" ;
VAL_ 1504 SAD_Anf_ESC_Zuschaltung 0 "inaktiv" 1 "aktiv" ;
VAL_ 980 BH_Blinker_li 0 "nicht_betaetigt" 1 "Blinkerhebel_Pos_li_betaetigt" ;
VAL_ 980 BH_Blinker_re 0 "nicht_betaetigt" 1 "Blinkerhebel_Pos_re_betaetigt" ;
VAL_ 980 BH_Lichthupe 0 "nicht_betaetigt" 1 "Blinkerhebel in Richtung Lichthupe betaetigt" ;
VAL_ 980 BH_Fernlicht 0 "nicht_betaetigt" 1 "Blinkerhebel_in_Richtung_Fernlicht_betaetigt" ;
VAL_ 980 WH_Tipwischen 0 "nicht_betaetigt" 1 "betaetigt" ;
VAL_ 980 WH_Intervall 0 "aus" 1 "Wischerhebel in Stellung Intervall" ;
VAL_ 980 WH_WischerStufe1 0 "aus" 1 "Wischerhebel in Stufe Wischen 1" ;
VAL_ 980 WH_WischerStufe2 0 "aus" 1 "Wischerhebel in Stufe Wischen 2" ;
VAL_ 980 WH_Frontwaschen 0 "aus" 1 "Wischerhebel in Stellung Wisch Wasch vorne" ;
VAL_ 980 WH_Heckintervall 0 "nicht_betaetigt" 1 "Wischerhebel in Stellung Heckintervall" ;
VAL_ 980 WH_Heckwaschen 0 "nicht_betaetigt" 1 "Wischerhebel in Stellung Wisch Wasch hinten" ;
VAL_ 980 WH_Intervallstufen 0 "Init / Default" 1 "Intervallstufe 1" 5 "Intervallstufe 2" 9 "Intervallstufe 3" 13 "Intervallstufe 4" 15 "Fehler" ;
VAL_ 980 FAS_Taster 0 "nicht_betaetigt" 1 "betaetigt" ;
VAL_ 980 FAS_Taster_Fehler 0 "kein_Fehler" 1 "Fehler" ;
VAL_ 980 SMLS_Hupe 0 "nicht_betaetigt" 1 "Hupe_gedrueckt" ;
VAL_ 980 LRH_On_Off 0 "LRH_aus__keine Anzeige" 1 "LRH_aus" 2 "LRH_ein" 3 "Fehler" ;
VAL_ 980 LSS_Tastencode 0 "Key_Released__No_Key" 4 "Up" 5 "Down" 7 "OK__ThumbWheel_Button" ;
VAL_ 980 LRH_aktiv 0 "inaktiv" 1 "aktiv" ;
VAL_ 980 SMLS_P_verriegelt 0 "Init" 1 "nicht_verriegelt" 2 "verriegelt" 3 "Fehler" ;
VAL_ 980 SMLS_P_verriegelt_plausibel 0 "unplausibel" 1 "plausibel" ;
VAL_ 980 WH_SRA 0 "SRA_Aus" 1 "SRA_Ein" ;
VAL_ 980 WH_Wischer_Fehler 0 "kein_Fehler" 1 "Fehler" ;
VAL_ 980 BH_Blinker_Fehler 0 "kein_Fehler" 1 "Fehler" ;
VAL_ 980 SMLS_PTT 0 "nicht_betaetigt" 1 "PTT_gedrueckt" ;
VAL_ 980 WH_Tipwischen_lang 0 "nicht_betaetigt" 1 "betaetigt" ;
VAL_ 2589283756 SOK_ungeschuetzte_Zeit 0 "Init" ;
VAL_ 1467 SoSe_SunInt_2D_Li 254 "Init" 255 "Fehler" ;
VAL_ 1467 SoSe_SunInt_2D_Re 254 "Init" 255 "Fehler" ;
VAL_ 2527679739 STK_FSH_Anf 0 "keine_Anforderung" 1 "Frontscheibenheizung_Anf" ;
VAL_ 2527679739 STK_HSH_Anf 0 "keine_Anforderung" 1 "Heckscheibenheizung_Anf" ;
VAL_ 2527679739 STK_Klima_Temp 29 "VW_high_30C" 30 "Init" 31 "Fehler" ;
VAL_ 2527679739 STK_KurzVK_Anf 0 "nicht_angefordert" 1 "angefordert" ;
VAL_ 2527679739 STK_Standklima_Anf 0 "nicht_angefordert" 1 "angefordert" ;
VAL_ 2527679739 STK_Standklima_Timer_Status 0 "Standklimatimer_nicht_aktiv" 1 "Standklimatimer_aktiv" ;
VAL_ 2527679739 STK_AirCLeaner_Anf 0 "nicht_angefordert" 1 "angefordert" ;
VAL_ 2527679739 STK_VK_Modus 0 "keine_Vorkonditionierung" 1 "Sofort_Konditionierung" 2 "zeitversetzte_Konditionierung" 3 "Fehler" ;
VAL_ 2527679739 STK_ErwVK_Anf 0 "nicht_angefordert" 1 "angefordert" ;
VAL_ 2527679739 STK_ErwVK_Modus 0 "nicht_angefordert" 1 "Fahrerzone" 2 "Beifahrerzone" 3 "Heckzone_links" 4 "Heckzone_rechts" 5 "Scheibenheizung" ;
VAL_ 2527679739 STK_Berechnungsphase 0 "keine_Berechnungsphase" 1 "Berechnungsphase_erforderlich" 2 "Init" 3 "Fehler" ;
VAL_ 2527679739 STK_VK_Timer_Status 0 "nicht_aktiv" 1 "aktiv" 2 "Sofortstart_aktiv" ;
VAL_ 2527679739 STK_Anf_AussenspiegelHZ 0 "nicht_angefordert" 1 "angefordert" ;
VAL_ 2527679739 STK_ErwVK_Beifahrerzone 0 "nicht_angefordert" 1 "Beifahrerzone_angefordert" ;
VAL_ 2527679739 STK_ErwVK_Fahrerzone 0 "nicht_angefordert" 1 "Fahrerzone_angefordert" ;
VAL_ 2527679739 STK_ErwVK_Heckzone_links 0 "nicht_angefordert" 1 "Heckzone_links_angefordert" ;
VAL_ 2527679739 STK_ErwVK_Heckzone_rechts 0 "nicht_angefordert" 1 "Heckzone_rechts_angefordert" ;
VAL_ 2527679739 STK_ErwVK_Scheibenheizung 0 "nicht_angefordert" 1 "Scheibenheizung_angefordert" ;
VAL_ 2527679739 STK_VK_STH_Einsatz 0 "Verbrennerstandheizung verbieten" 1 "Automatik (Verbrennerstandheizung erlauben)" 2 "Verbrennerstandheizung erzwingen" 3 "reserviert" 4 "reserviert" 5 "reserviert" 6 "Init" 7 "Fehler" ;
VAL_ 2527679739 STK_Voko_LED 0 "Aus" 1 "Ein" ;
VAL_ 2527679739 STK_MaxLeistung 254 "Init" 255 "Fehler" ;
VAL_ 2527679739 STK_GesamtEnergiebedarf 254 "Init" 255 "Fehler" ;
VAL_ 2527679739 STK_Stecker_Status 0 "kein_Stecker_erkannt" 1 "AC_Stecker_erkannt" 2 "DC_Stecker_erkannt" ;
VAL_ 2527679739 STK_ErwVK_Heckzone2_links 0 "nicht_angefordert" 1 "Heckzone2_links_angefordert" ;
VAL_ 2527679739 STK_ErwVK_Heckzone2_rechts 0 "nicht_angefordert" 1 "Heckzone2_rechts_angefordert" ;
VAL_ 1313 STH_Funk_ein 0 "kein Funkbefehl zum Einschalten" 1 "Funkbefehl zum Einschalten erhalten" ;
VAL_ 1313 STH_Funk_aus 0 "kein Funkbefehl" 1 "Funkbefehl zum Ausschalten erhalten" ;
VAL_ 1313 STH_Zusatzheizung 0 "Zuheizer aus" 1 "Zuheizer ein" ;
VAL_ 1313 STH_LED 0 "keine Rückmeldung" 1 "Rueckmeldung Standheizung in Betrieb" ;
VAL_ 1313 STH_Geblaese 0 "kein Einschaltbefehl an die Klimaanlage, Gebläse" 1 "Einschaltbefehl an die Klimaanlage, Gebläse" ;
VAL_ 1313 STH_EKP_Anst 0 "EKP nicht ansteuern" 1 "EKP ansteuern" ;
VAL_ 1313 STH_Start_folgt 0 "kein_Start_folgt" 1 "Start_folgt" ;
VAL_ 1313 STH_Ventil_Status 0 "Ventil_offen__grosser_Kreislauf" 1 "Ventil_geschlossen__kleiner_Kreislauf" ;
VAL_ 1313 STH_Fehler_ElWaPu 0 "kein_Fehler" 1 "Fehler" ;
VAL_ 1313 STH_Pumpen_Anf_extern 0 "nicht_angefordert" 1 "angefordert" ;
VAL_ 1313 STH_KL_HUP 0 "Aus" 1 "Ein" ;
VAL_ 1313 STH_Fehlerstatus 0 "kein_Fehler" 1 "Unterspannung" 2 "Tankfuellstand_zu_gering" 3 "Fehler_Betrieb_verhindert" 4 "Heizgeraet_verriegelt" 5 "Fehler_Betrieb_nicht_verhindert" 6 "Emissionsüberschreitung" ;
VAL_ 1313 STH_Wassertemp 254 "Init" 255 "Fehler" ;
VAL_ 1313 STH_Texte 0 "keine_Anzeige" 1 "Batteriemanagementeinschraenkung" 2 "Kraftstoffmangel" 3 "interner_Systemfehler" 4 "Heizzeitueberschreitung" ;
VAL_ 1313 STH_Motorvorwaermung 0 "keine Motorvorwärmung erfolgt" 1 "Aufheizung mit Motorvorwärmung erfolgt" ;
VAL_ 1313 STH_Servicemode 0 "Servicemode nicht aktiv" 1 "Servicemode aktiv" ;
VAL_ 1313 STH_war_aktiv 0 "war inaktiv" 1 "Standheizung war letzte halbe Stunde aktiv" ;
VAL_ 1313 STH_KVS_Ueberlauf 0 "kein Überlauf" 1 "Kraftstoffverbrauchssignal, mindestens ein Überlauf hat stattgefunden" ;
VAL_ 1313 STH_SH_ZH 0 "Heizgeraet_WZH" 1 "Heizgeraet_ZH" ;
